VERSION "HNNBNNNYNNNNNNNNNNNNNNNNNNNNNNNNNNNNNNNNNN/4/%%%/4/'%**4NNN///"

NS_ :

BS_:

BU_: AWC BAP_Tester BMC_MLBevo BMS_MV BMS_NV DCDC_800V_PAG DCDC_HV DCDC_HV_02 DCDC_IHEV FCU_MLBevo_FCEV Gateway Gateway_PAG Ladegeraet_2 Ladegeraet_Konzern LE1 LE2 LE2_3_MLBevo_LB LE_MLBevo LE_MLBevo_LB Sub_Gateway TME

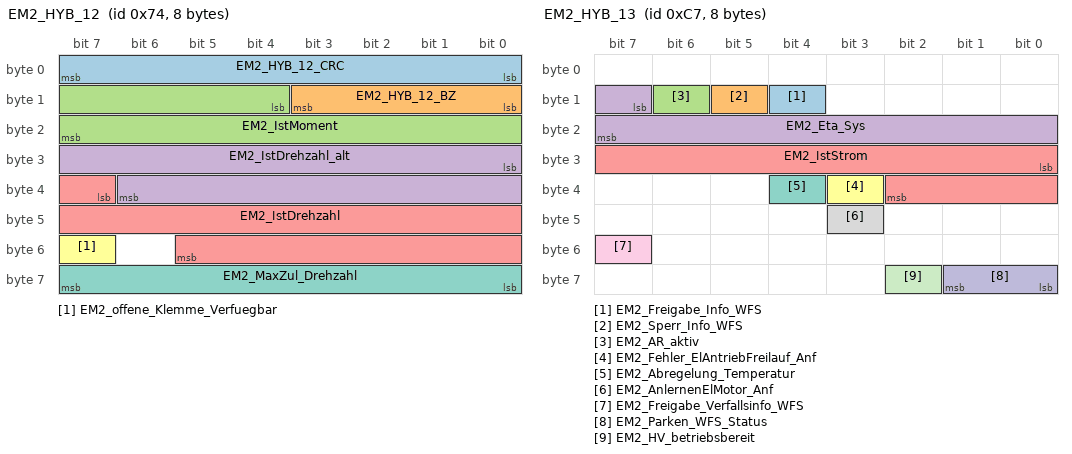
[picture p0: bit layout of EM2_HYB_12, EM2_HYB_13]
BO_ 116 EM2_HYB_12: 8 Gateway
 SG_ EM2_HYB_12_CRC : 0|8@1+ (1,0) [0|255] ""  Sub_Gateway
 SG_ EM2_HYB_12_BZ : 8|4@1+ (1,0) [0|15] ""  Sub_Gateway
 SG_ EM2_IstMoment : 12|12@1+ (0.5,-1023) [-1023|1023.5] "Unit_NewtoMeter"  Sub_Gateway
 SG_ EM2_IstDrehzahl_alt : 24|15@1+ (1,-10000) [-10000|22765] "Unit_MinutInver"  Sub_Gateway
 SG_ EM2_IstDrehzahl : 39|15@1+ (1,-10000) [-10000|22765] "Unit_MinutInver"  Sub_Gateway
 SG_ EM2_offene_Klemme_Verfuegbar : 55|1@1+ (1,0) [0|1] ""  Sub_Gateway
 SG_ EM2_MaxZul_Drehzahl : 56|8@1+ (80,0) [0|20240] "Unit_RevPerMinute"  Sub_Gateway

BO_ 199 EM2_HYB_13: 8 Gateway
 SG_ EM2_Freigabe_Info_WFS : 12|1@1+ (1,0) [0|1] ""  Sub_Gateway
 SG_ EM2_Sperr_Info_WFS : 13|1@1+ (1,0) [0|1] ""  Sub_Gateway
 SG_ EM2_AR_aktiv : 14|1@1+ (1,0) [0|1] ""  Sub_Gateway
 SG_ EM2_Eta_Sys : 15|9@1+ (0.2,0) [0|101.8] "Unit_PerCent"  Sub_Gateway
 SG_ EM2_IstStrom : 24|11@1+ (1,-1023) [-1023|1022] "Unit_Amper"  Sub_Gateway
 SG_ EM2_Fehler_ElAntriebFreilauf_Anf : 35|1@1+ (1,0) [0|1] ""  Sub_Gateway
 SG_ EM2_Abregelung_Temperatur : 36|1@1+ (1,0) [0|1] ""  Sub_Gateway
 SG_ EM2_AnlernenElMotor_Anf : 43|1@1+ (1,0) [0|1] ""  Sub_Gateway
 SG_ EM2_Freigabe_Verfallsinfo_WFS : 55|1@1+ (1,0) [0|1] ""  Sub_Gateway
 SG_ EM2_Parken_WFS_Status : 56|2@1+ (1,0) [0|3] ""  Sub_Gateway
 SG_ EM2_HV_betriebsbereit : 58|1@1+ (1,0) [0|1] ""  Sub_Gateway

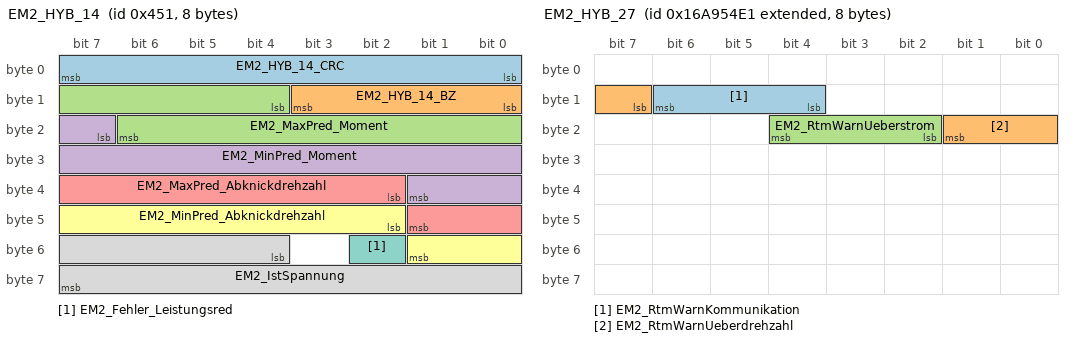
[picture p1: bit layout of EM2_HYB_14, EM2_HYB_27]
BO_ 1105 EM2_HYB_14: 8 Gateway
 SG_ EM2_HYB_14_CRC : 0|8@1+ (1,0) [0|255] ""  Sub_Gateway
 SG_ EM2_HYB_14_BZ : 8|4@1+ (1,0) [0|15] ""  Sub_Gateway
 SG_ EM2_MaxPred_Moment : 12|11@1+ (1,-1023) [-1023|1022] "Unit_NewtoMeter"  Sub_Gateway
 SG_ EM2_MinPred_Moment : 23|11@1+ (1,-1023) [-1023|1022] "Unit_NewtoMeter"  Sub_Gateway
 SG_ EM2_MaxPred_Abknickdrehzahl : 34|8@1+ (50,0) [0|12700] "Unit_MinutInver"  Sub_Gateway
 SG_ EM2_MinPred_Abknickdrehzahl : 42|8@1+ (50,0) [0|12700] "Unit_MinutInver"  Sub_Gateway
 SG_ EM2_Fehler_Leistungsred : 50|1@1+ (1,0) [0|1] ""  Sub_Gateway
 SG_ EM2_IstSpannung : 52|12@1+ (0.25,0) [0|1023.25] "Unit_Volt"  Sub_Gateway

BO_ 2527679713 EM2_HYB_27: 8 Gateway
 SG_ EM2_RtmWarnKommunikation : 12|3@1+ (1,0) [0|7] ""  Sub_Gateway
 SG_ EM2_RtmWarnUeberdrehzahl : 15|3@1+ (1,0) [0|7] ""  Sub_Gateway
 SG_ EM2_RtmWarnUeberstrom : 18|3@1+ (1,0) [0|7] ""  Sub_Gateway

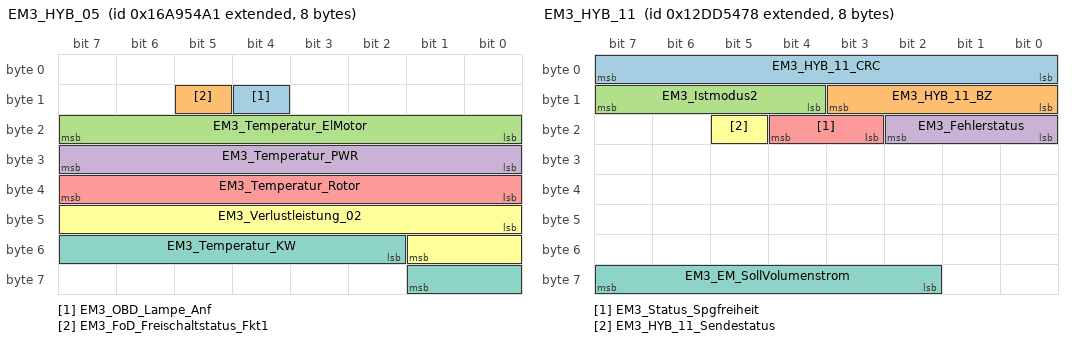
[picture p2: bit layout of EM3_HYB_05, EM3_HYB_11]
BO_ 2527679649 EM3_HYB_05: 8 Gateway
 SG_ EM3_OBD_Lampe_Anf : 12|1@1+ (1,0) [0|1] ""  Sub_Gateway
 SG_ EM3_FoD_Freischaltstatus_Fkt1 : 13|1@1+ (1,0) [0|1] ""  Sub_Gateway
 SG_ EM3_Temperatur_ElMotor : 16|8@1+ (1,-40) [-40|213] "Unit_DegreCelsi"  Sub_Gateway,TME
 SG_ EM3_Temperatur_PWR : 24|8@1+ (1,-40) [-40|213] "Unit_DegreCelsi"  Sub_Gateway,TME
 SG_ EM3_Temperatur_Rotor : 32|8@1+ (1,-40) [-40|213] "Unit_DegreCelsi"  Sub_Gateway,TME
 SG_ EM3_Verlustleistung_02 : 40|10@1+ (80,0) [0|81680] "Unit_Watt"  Sub_Gateway,TME
 SG_ EM3_Temperatur_KW : 50|8@1+ (0.75,-48) [-48|141.75] "Unit_DegreCelsi"  Sub_Gateway

BO_ 2463978616 EM3_HYB_11: 8 Gateway
 SG_ EM3_HYB_11_CRC : 0|8@1+ (1,0) [0|255] ""  Sub_Gateway
 SG_ EM3_HYB_11_BZ : 8|4@1+ (1,0) [0|15] ""  Sub_Gateway
 SG_ EM3_Istmodus2 : 12|4@1+ (1,0) [0|15] ""  Sub_Gateway,TME
 SG_ EM3_Fehlerstatus : 16|3@1+ (1,0) [0|7] ""  Sub_Gateway
 SG_ EM3_Status_Spgfreiheit : 19|2@1+ (1,0) [0|3] ""  Sub_Gateway
 SG_ EM3_HYB_11_Sendestatus : 21|1@1+ (1,0) [0|1] ""  Sub_Gateway
 SG_ EM3_EM_SollVolumenstrom : 58|6@1+ (0.5,0) [0|30.5] "Unit_LiterPerMinut"  Sub_Gateway,TME

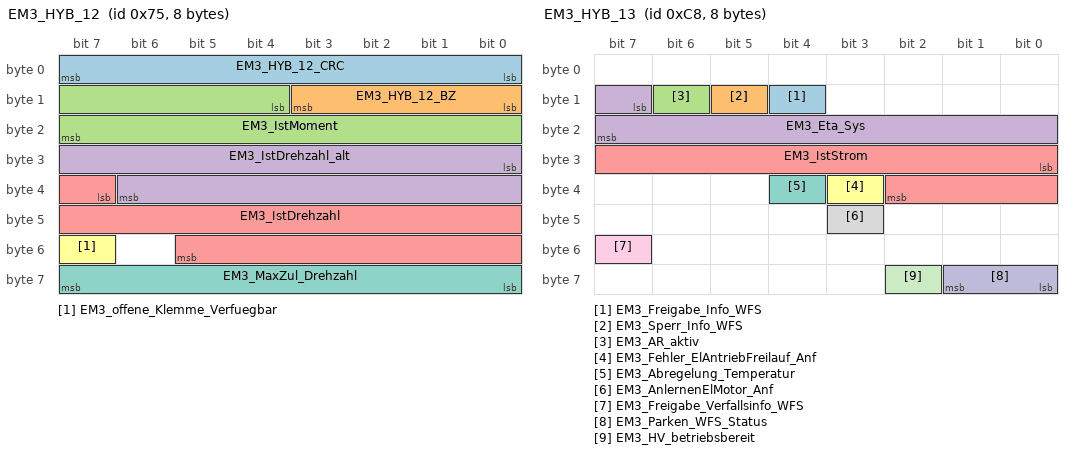
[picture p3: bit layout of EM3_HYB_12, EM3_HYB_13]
BO_ 117 EM3_HYB_12: 8 Gateway
 SG_ EM3_HYB_12_CRC : 0|8@1+ (1,0) [0|255] ""  Sub_Gateway
 SG_ EM3_HYB_12_BZ : 8|4@1+ (1,0) [0|15] ""  Sub_Gateway
 SG_ EM3_IstMoment : 12|12@1+ (0.5,-1023) [-1023|1023.5] "Unit_NewtoMeter"  Sub_Gateway
 SG_ EM3_IstDrehzahl_alt : 24|15@1+ (1,-10000) [-10000|22765] "Unit_MinutInver"  Sub_Gateway
 SG_ EM3_IstDrehzahl : 39|15@1+ (1,-10000) [-10000|22765] "Unit_MinutInver"  Sub_Gateway
 SG_ EM3_offene_Klemme_Verfuegbar : 55|1@1+ (1,0) [0|1] ""  Sub_Gateway
 SG_ EM3_MaxZul_Drehzahl : 56|8@1+ (80,0) [0|20240] "Unit_RevPerMinute"  Sub_Gateway

BO_ 200 EM3_HYB_13: 8 Gateway
 SG_ EM3_Freigabe_Info_WFS : 12|1@1+ (1,0) [0|1] ""  Sub_Gateway
 SG_ EM3_Sperr_Info_WFS : 13|1@1+ (1,0) [0|1] ""  Sub_Gateway
 SG_ EM3_AR_aktiv : 14|1@1+ (1,0) [0|1] ""  Sub_Gateway
 SG_ EM3_Eta_Sys : 15|9@1+ (0.2,0) [0|101.8] "Unit_PerCent"  Sub_Gateway
 SG_ EM3_IstStrom : 24|11@1+ (1,-1023) [-1023|1022] "Unit_Amper"  Sub_Gateway
 SG_ EM3_Fehler_ElAntriebFreilauf_Anf : 35|1@1+ (1,0) [0|1] ""  Sub_Gateway
 SG_ EM3_Abregelung_Temperatur : 36|1@1+ (1,0) [0|1] ""  Sub_Gateway
 SG_ EM3_AnlernenElMotor_Anf : 43|1@1+ (1,0) [0|1] ""  Sub_Gateway
 SG_ EM3_Freigabe_Verfallsinfo_WFS : 55|1@1+ (1,0) [0|1] ""  Sub_Gateway
 SG_ EM3_Parken_WFS_Status : 56|2@1+ (1,0) [0|3] ""  Sub_Gateway
 SG_ EM3_HV_betriebsbereit : 58|1@1+ (1,0) [0|1] ""  Sub_Gateway

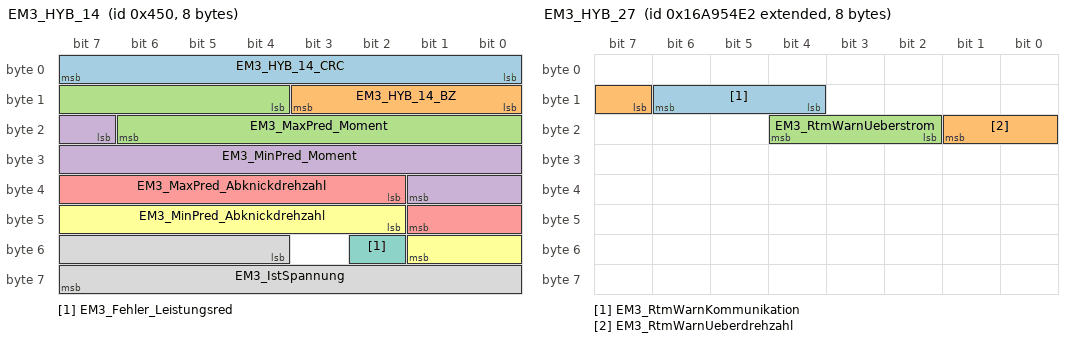
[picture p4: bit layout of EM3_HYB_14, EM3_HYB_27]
BO_ 1104 EM3_HYB_14: 8 Gateway
 SG_ EM3_HYB_14_CRC : 0|8@1+ (1,0) [0|255] ""  Sub_Gateway
 SG_ EM3_HYB_14_BZ : 8|4@1+ (1,0) [0|15] ""  Sub_Gateway
 SG_ EM3_MaxPred_Moment : 12|11@1+ (1,-1023) [-1023|1022] "Unit_NewtoMeter"  Sub_Gateway
 SG_ EM3_MinPred_Moment : 23|11@1+ (1,-1023) [-1023|1022] "Unit_NewtoMeter"  Sub_Gateway
 SG_ EM3_MaxPred_Abknickdrehzahl : 34|8@1+ (50,0) [0|12700] "Unit_MinutInver"  Sub_Gateway
 SG_ EM3_MinPred_Abknickdrehzahl : 42|8@1+ (50,0) [0|12700] "Unit_MinutInver"  Sub_Gateway
 SG_ EM3_Fehler_Leistungsred : 50|1@1+ (1,0) [0|1] ""  Sub_Gateway
 SG_ EM3_IstSpannung : 52|12@1+ (0.25,0) [0|1023.25] "Unit_Volt"  Sub_Gateway

BO_ 2527679714 EM3_HYB_27: 8 Gateway
 SG_ EM3_RtmWarnKommunikation : 12|3@1+ (1,0) [0|7] ""  Sub_Gateway
 SG_ EM3_RtmWarnUeberdrehzahl : 15|3@1+ (1,0) [0|7] ""  Sub_Gateway
 SG_ EM3_RtmWarnUeberstrom : 18|3@1+ (1,0) [0|7] ""  Sub_Gateway

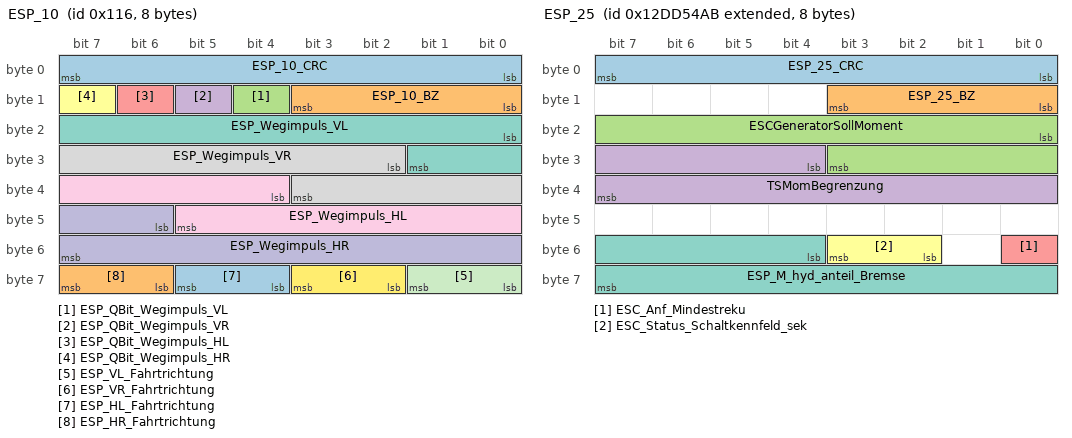
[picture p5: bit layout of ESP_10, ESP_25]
BO_ 278 ESP_10: 8 Gateway
 SG_ ESP_10_CRC : 0|8@1+ (1,0) [0|255] "" Vector__XXX
 SG_ ESP_10_BZ : 8|4@1+ (1,0) [0|15] "" Vector__XXX
 SG_ ESP_QBit_Wegimpuls_VL : 12|1@1+ (1,0) [0|1] ""  AWC
 SG_ ESP_QBit_Wegimpuls_VR : 13|1@1+ (1,0) [0|1] ""  AWC
 SG_ ESP_QBit_Wegimpuls_HL : 14|1@1+ (1,0) [0|1] ""  AWC
 SG_ ESP_QBit_Wegimpuls_HR : 15|1@1+ (1,0) [0|1] ""  AWC
 SG_ ESP_Wegimpuls_VL : 16|10@1+ (1,0) [0|1000] ""  AWC
 SG_ ESP_Wegimpuls_VR : 26|10@1+ (1,0) [0|1000] ""  AWC
 SG_ ESP_Wegimpuls_HL : 36|10@1+ (1,0) [0|1000] ""  AWC
 SG_ ESP_Wegimpuls_HR : 46|10@1+ (1,0) [0|1000] ""  AWC
 SG_ ESP_VL_Fahrtrichtung : 56|2@1+ (1,0) [0|3] ""  AWC
 SG_ ESP_VR_Fahrtrichtung : 58|2@1+ (1,0) [0|3] ""  AWC
 SG_ ESP_HL_Fahrtrichtung : 60|2@1+ (1,0) [0|3] ""  AWC
 SG_ ESP_HR_Fahrtrichtung : 62|2@1+ (1,0) [0|3] ""  AWC

BO_ 418 ESP_15: 8 Gateway
 SG_ ESP_15_CRC : 0|8@1+ (1,0) [0|255] "" Vector__XXX
 SG_ ESP_15_BZ : 8|4@1+ (1,0) [0|15] "" Vector__XXX
 SG_ HMS_P_beibehalten_GE : 12|2@1+ (1,0) [0|3] "" Vector__XXX
 SG_ HMS_Konsistenz_GE : 14|1@1+ (1,0) [0|1] "" Vector__XXX
 SG_ HMS_Konsistenz_IPA : 15|1@1+ (1,0) [0|1] "" Vector__XXX
 SG_ HMS_Konsistenz_STA : 18|1@1+ (1,0) [0|1] "" Vector__XXX
 SG_ HMS_Konsistenz_MO : 19|1@1+ (1,0) [0|1] "" Vector__XXX
 SG_ HMS_halten_nicht_verfuegbar : 20|1@1+ (1,0) [0|1] "" Vector__XXX
 SG_ NL_PRIM_STP_01_Status : 21|3@1+ (1,0) [0|7] "" Vector__XXX
 SG_ VMM_Warnblinken : 24|1@1+ (1,0) [0|1] "" Vector__XXX
 SG_ VZM_Status : 26|3@1+ (1,0) [0|7] "" Vector__XXX
 SG_ HMS_Notstopp_Status : 29|3@1+ (1,0) [0|7] "" Vector__XXX
 SG_ HMS_parken_nicht_verfuegbar : 32|1@1+ (1,0) [0|1] "" Vector__XXX
 SG_ HMS_Anforderung_GE : 33|3@1+ (1,0) [0|7] "" Vector__XXX
 SG_ HMS_Systemstatus : 36|4@1+ (1,0) [0|15] ""  FCU_MLBevo_FCEV,Ladegeraet_Konzern
 SG_ HMS_Stillstand : 40|3@1+ (1,0) [0|7] "" Vector__XXX
 SG_ HMS_aktives_System : 43|5@1+ (1,0) [0|31] ""  Ladegeraet_Konzern
 SG_ HMS_Konsistenz_HVLM : 48|1@1+ (1,0) [0|1] ""  Ladegeraet_Konzern
 SG_ HMS_Konsistenz_ACC : 49|1@1+ (1,0) [0|1] "" Vector__XXX
 SG_ HMS_Fehlerstatus : 50|3@1+ (1,0) [0|7] ""  FCU_MLBevo_FCEV,Ladegeraet_Konzern
 SG_ ESP_Index_Haltemoment : 53|1@1+ (1,0) [0|1] "" Vector__XXX
 SG_ ESP_Haltemoment : 54|10@1+ (10,0) [0|10210] "Unit_NewtoMeter" Vector__XXX

BO_ 1629 ESP_20: 8 Gateway
 SG_ ESP_20_CRC : 0|8@1+ (1,0) [0|255] "" Vector__XXX
 SG_ ESP_20_BZ : 8|4@1+ (1,0) [0|15] "" Vector__XXX
 SG_ BR_Systemart : 12|2@1+ (1,0) [0|3] "" Vector__XXX
 SG_ ESP_SpannungsAnf_02 : 14|2@1+ (1,0) [0|3] "" Vector__XXX
 SG_ ESP_Zaehnezahl : 16|8@1+ (1,0) [0|255] "" Vector__XXX
 SG_ ESP_Charisma_FahrPr : 24|4@1+ (1,0) [0|15] "" Vector__XXX
 SG_ ESP_Charisma_Status : 28|2@1+ (1,0) [0|3] "" Vector__XXX
 SG_ ESP_Wiederstart_Anz_01 : 30|1@1+ (1,0) [0|1] "" Vector__XXX
 SG_ ESP_Wiederstart_Anz_02 : 31|1@1+ (1,0) [0|1] "" Vector__XXX
 SG_ ESP_Wiederstart_Anz_03 : 32|1@1+ (1,0) [0|1] "" Vector__XXX
 SG_ ESP_Wiederstart_Anz_04 : 33|1@1+ (1,0) [0|1] "" Vector__XXX
 SG_ ESP_Stoppverbot_Anz_01 : 34|1@1+ (1,0) [0|1] "" Vector__XXX
 SG_ ESP_Stoppverbot_Anz_02 : 35|1@1+ (1,0) [0|1] "" Vector__XXX
 SG_ ESP_Stoppverbot_Anz_03 : 36|1@1+ (1,0) [0|1] "" Vector__XXX
 SG_ ESP_Stoppverbot_Anz_04 : 37|1@1+ (1,0) [0|1] "" Vector__XXX
 SG_ ESP_Stoppverbot_Anz_05 : 38|1@1+ (1,0) [0|1] "" Vector__XXX
 SG_ ESP_Stoppverbot_Anz_06 : 39|1@1+ (1,0) [0|1] "" Vector__XXX
 SG_ ESP_Stoppverbot_Anz_07 : 40|1@1+ (1,0) [0|1] "" Vector__XXX
 SG_ ESP_Stoppverbot_Anz_Std : 41|1@1+ (1,0) [0|1] "" Vector__XXX
 SG_ ESP_Dachrelingsensor : 42|2@1+ (1,0) [0|3] "" Vector__XXX
 SG_ ESP_Stoppverbot_Anz_08 : 44|1@1+ (1,0) [0|1] "" Vector__XXX
 SG_ HDC_Charisma_FahrPr : 45|4@1+ (1,0) [0|15] "" Vector__XXX
 SG_ HDC_Charisma_Status : 49|2@1+ (1,0) [0|3] "" Vector__XXX
 SG_ BR_QBit_Reifenumfang : 51|1@1+ (1,0) [0|1] ""  AWC
 SG_ BR_Reifenumfang : 52|12@1+ (1,0) [0|4095] "Unit_MilliMeter"  AWC

BO_ 795 ESP_24: 8 Gateway
 SG_ ESP_24_CRC : 0|8@1+ (1,0) [0|255] ""  Sub_Gateway
 SG_ ESP_24_BZ : 8|4@1+ (1,0) [0|15] ""  Sub_Gateway
 SG_ ESP_Lampe : 12|1@1+ (1,0) [0|1] ""  Sub_Gateway
 SG_ ABS_Lampe : 13|1@1+ (1,0) [0|1] ""  Sub_Gateway
 SG_ BK_Lampe_02 : 14|2@1+ (1,0) [0|3] ""  Sub_Gateway
 SG_ TC_Lampe : 16|1@1+ (1,0) [0|1] ""  Sub_Gateway
 SG_ ESP_m_Raddrehz : 17|15@1+ (0.002,0) [0|65.278] "Unit_Hertz"  Sub_Gateway
 SG_ ESP_Textanzeigen_03 : 32|5@1+ (1,0) [0|31] ""  Sub_Gateway
 SG_ ESP_Meldungen : 37|3@1+ (1,0) [0|7] ""  Sub_Gateway
 SG_ ESP_Wegimp_VA : 40|11@1+ (1,0) [0|2047] ""  Sub_Gateway
 SG_ ESP_Fehlerstatus_Wegimp : 51|1@1+ (1,0) [0|1] ""  Sub_Gateway
 SG_ ESP_Wegimp_Ueberlauf : 52|1@1+ (1,0) [0|1] ""  Sub_Gateway
 SG_ ESP_QBit_Wegimp_VA : 53|1@1+ (1,0) [0|1] ""  Sub_Gateway
 SG_ ESP_HDC_Geschw_Farbe : 54|1@1+ (1,0) [0|1] ""  Sub_Gateway
 SG_ ESP_Off_Lampe : 55|1@1+ (1,0) [0|1] ""  Sub_Gateway
 SG_ ESP_HDC_Regelgeschw : 56|7@1+ (0.32,0) [0.32|39.68] "Unit_KiloMeterPerHour"  Sub_Gateway
 SG_ ESP_BKV_Warnung : 63|1@1+ (1,0) [0|1] ""  Sub_Gateway

BO_ 2463978667 ESP_25: 8 Gateway
 SG_ ESP_25_CRC : 0|8@1+ (1,0) [0|255] "" Vector__XXX
 SG_ ESP_25_BZ : 8|4@1+ (1,0) [0|15] "" Vector__XXX
 SG_ ESCGeneratorSollMoment : 16|12@1+ (3,-12279) [-12279|0] "" Vector__XXX
 SG_ TSMomBegrenzung : 28|12@1+ (3,-12279) [-12279|0] "" Vector__XXX
 SG_ ESC_Anf_Mindestreku : 48|1@1+ (1,0) [0|1] ""  TME
 SG_ ESC_Status_Schaltkennfeld_sek : 50|2@1+ (1,0) [0|3] "" Vector__XXX
 SG_ ESP_M_hyd_anteil_Bremse : 52|12@1+ (4,0) [0|16372] "Unit_NewtoMeter" Vector__XXX

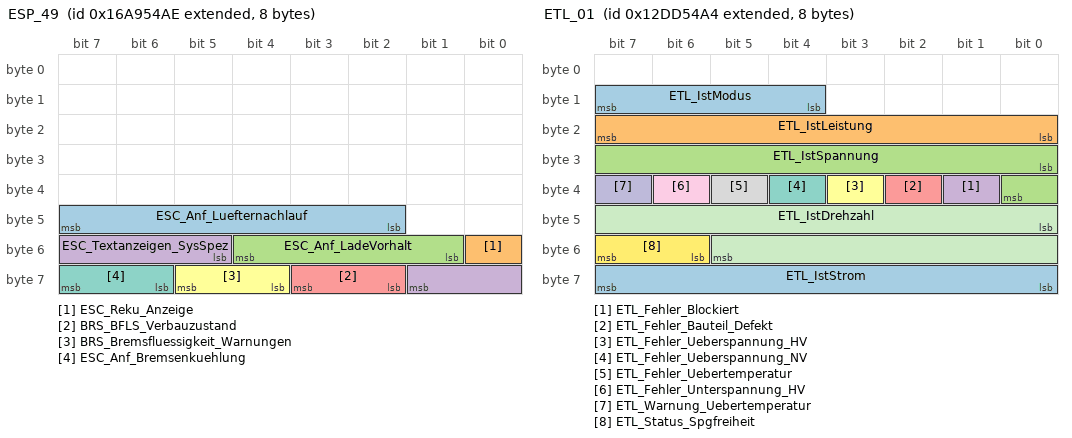
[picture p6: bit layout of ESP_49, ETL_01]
BO_ 2527679662 ESP_49: 8 Gateway
 SG_ ESC_Anf_Luefternachlauf : 42|6@1+ (15,0) [0|945] "Unit_Secon"  TME
 SG_ ESC_Reku_Anzeige : 48|1@1+ (1,0) [0|1] "" Vector__XXX
 SG_ ESC_Anf_LadeVorhalt : 49|4@1+ (1,0) [0|15] ""  Ladegeraet_Konzern
 SG_ ESC_Textanzeigen_SysSpez : 53|5@1+ (1,0) [0|31] "" Vector__XXX
 SG_ BRS_BFLS_Verbauzustand : 58|2@1+ (1,0) [0|3] "" Vector__XXX
 SG_ BRS_Bremsfluessigkeit_Warnungen : 60|2@1+ (1,0) [0|3] "" Vector__XXX
 SG_ ESC_Anf_Bremsenkuehlung : 62|2@1+ (1,0) [0|3] ""  TME

BO_ 2463978660 ETL_01: 8 FCU_MLBevo_FCEV
 SG_ ETL_IstModus : 12|4@1+ (1,0) [0|15] "" Vector__XXX
 SG_ ETL_IstLeistung : 16|8@1+ (200,-25400) [-25400|25400] "Unit_Watt" Vector__XXX
 SG_ ETL_IstSpannung : 24|9@1+ (2,0) [0|1020] "Unit_Volt"  Gateway
 SG_ ETL_Fehler_Blockiert : 33|1@1+ (1,0) [0|1] "" Vector__XXX
 SG_ ETL_Fehler_Bauteil_Defekt : 34|1@1+ (1,0) [0|1] "" Vector__XXX
 SG_ ETL_Fehler_Ueberspannung_HV : 35|1@1+ (1,0) [0|1] "" Vector__XXX
 SG_ ETL_Fehler_Ueberspannung_NV : 36|1@1+ (1,0) [0|1] "" Vector__XXX
 SG_ ETL_Fehler_Uebertemperatur : 37|1@1+ (1,0) [0|1] "" Vector__XXX
 SG_ ETL_Fehler_Unterspannung_HV : 38|1@1+ (1,0) [0|1] "" Vector__XXX
 SG_ ETL_Warnung_Uebertemperatur : 39|1@1+ (1,0) [0|1] "" Vector__XXX
 SG_ ETL_IstDrehzahl : 40|14@1+ (10,0) [0|163820] "Unit_RevPerMinute" Vector__XXX
 SG_ ETL_Status_Spgfreiheit : 54|2@1+ (1,0) [0|3] ""  Gateway
 SG_ ETL_IstStrom : 56|8@1+ (0.5,-63.5) [-63.5|63.5] "Unit_Amper" Vector__XXX

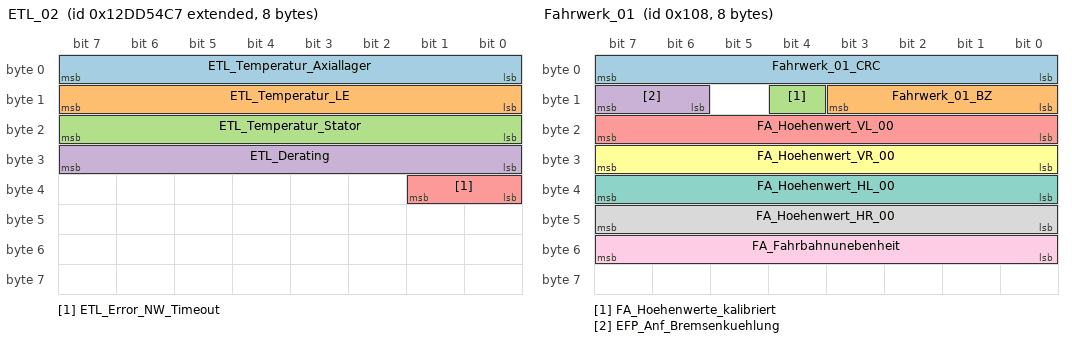
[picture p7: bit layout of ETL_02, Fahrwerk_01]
BO_ 2463978695 ETL_02: 8 FCU_MLBevo_FCEV
 SG_ ETL_Temperatur_Axiallager : 0|8@1+ (1,-40) [-40|213] "Unit_DegreCelsi"  TME
 SG_ ETL_Temperatur_LE : 8|8@1+ (1,-40) [-40|213] "Unit_DegreCelsi"  TME
 SG_ ETL_Temperatur_Stator : 16|8@1+ (1,-40) [-40|213] "Unit_DegreCelsi"  TME
 SG_ ETL_Derating : 24|8@1+ (0.5,0) [0|127] "Unit_PerCent" Vector__XXX
 SG_ ETL_Error_NW_Timeout : 32|2@1+ (1,0) [0|3] "" Vector__XXX

BO_ 264 Fahrwerk_01: 8 Gateway
 SG_ Fahrwerk_01_CRC : 0|8@1+ (1,0) [0|255] "" Vector__XXX
 SG_ Fahrwerk_01_BZ : 8|4@1+ (1,0) [0|15] "" Vector__XXX
 SG_ FA_Hoehenwerte_kalibriert : 12|1@1+ (1,0) [0|1] ""  AWC
 SG_ EFP_Anf_Bremsenkuehlung : 14|2@1+ (1,0) [0|3] ""  TME
 SG_ FA_Hoehenwert_VL_00 : 16|8@1+ (1,-127) [-127|126] "Unit_MilliMeter"  AWC
 SG_ FA_Hoehenwert_VR_00 : 24|8@1+ (1,-127) [-127|126] "Unit_MilliMeter"  AWC
 SG_ FA_Hoehenwert_HL_00 : 32|8@1+ (1,-127) [-127|126] "Unit_MilliMeter"  AWC
 SG_ FA_Hoehenwert_HR_00 : 40|8@1+ (1,-127) [-127|126] "Unit_MilliMeter"  AWC
 SG_ FA_Fahrbahnunebenheit : 48|8@1+ (1,0) [0|253] "" Vector__XXX

BO_ 222 FCU_01: 8 FCU_MLBevo_FCEV
 SG_ FCU_IstLeistung : 50|14@1+ (0.1,-200) [-200|1438.1] "Unit_KiloWatt"  Gateway

BO_ 379 FCU_02: 8 FCU_MLBevo_FCEV
 SG_ FCU_Warn_H2_Konzentrat_Motorraum : 12|3@1+ (1,0) [0|7] ""  Gateway,TME
 SG_ FCU_nicht_verfuegbar : 15|1@1+ (1,0) [0|1] ""  Gateway
 SG_ FCU_Startstopp_Anforderung : 16|4@1+ (1,0) [0|15] ""  Gateway
 SG_ FCU_HV_Anf : 20|2@1+ (1,0) [0|3] ""  Gateway
 SG_ FCU_Klima_Eingr : 22|2@1+ (1,0) [0|3] ""  Gateway,TME
 SG_ FCU_IstModus : 24|5@1+ (1,0) [0|31] ""  Gateway
 SG_ FCU_Status_Spgfreiheit : 29|2@1+ (1,0) [0|3] ""  Gateway
 SG_ FCU_Fehler_Leistungsreduzierung : 31|1@1+ (1,0) [0|1] ""  Gateway
 SG_ FCU_Fehler_Abschaltanforderung : 32|1@1+ (1,0) [0|1] ""  Gateway
 SG_ FCU_Fehler_Notabschaltung : 33|1@1+ (1,0) [0|1] ""  Gateway
 SG_ FCU_Fehler_Entladung_defekt : 34|2@1+ (1,0) [0|3] ""  Gateway
 SG_ FCU_Fehler_Isofehler_I : 36|2@1+ (1,0) [0|3] ""  Gateway
 SG_ FCU_Fehler_Isofehler_II : 38|2@1+ (1,0) [0|3] ""  Gateway
 SG_ FCU_OBD_Lampe_Anf : 40|1@1+ (1,0) [0|1] ""  Gateway
 SG_ FCU_Absperrventil_schliessen : 41|2@1+ (1,0) [0|3] ""  Gateway,TME
 SG_ FCU_TK_Betankung_Anforderung : 43|1@1+ (1,0) [0|1] ""  Gateway,Ladegeraet_Konzern
 SG_ FCU_MinAbs_Leistung : 44|10@1+ (0.1,-50) [-50|52.2] "Unit_KiloWatt"  Gateway
 SG_ FCU_Ionenspuelung_aktiv : 54|2@1+ (1,0) [0|3] ""  Gateway,TME
 SG_ FCU_TK_Freigabe_Tankklappe : 56|2@1+ (1,0) [0|3] ""  Gateway,Ladegeraet_Konzern

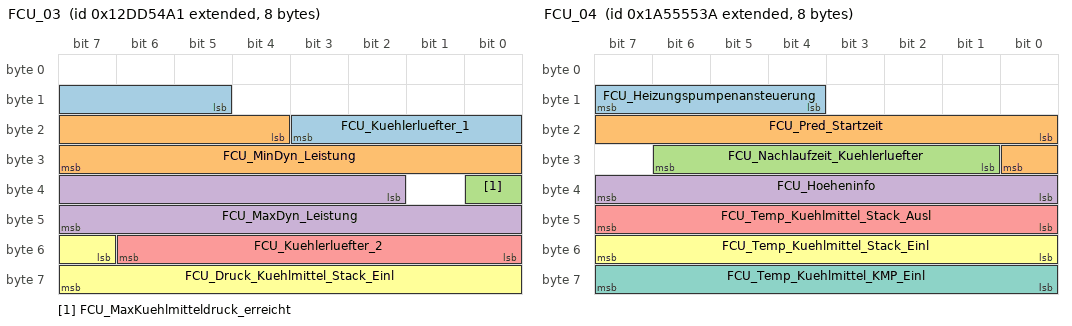
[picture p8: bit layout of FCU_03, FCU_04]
BO_ 2463978657 FCU_03: 8 FCU_MLBevo_FCEV
 SG_ FCU_Kuehlerluefter_1 : 13|7@1+ (1,0) [0|125] "Unit_PerCent"  Gateway,TME
 SG_ FCU_MinDyn_Leistung : 20|12@1+ (0.1,-200) [-200|209.4] "Unit_KiloWatt"  Gateway
 SG_ FCU_MaxKuehlmitteldruck_erreicht : 32|1@1+ (1,0) [0|1] ""  Gateway,TME
 SG_ FCU_MaxDyn_Leistung : 34|14@1+ (0.1,-200) [-200|1438.3] "Unit_KiloWatt"  Gateway
 SG_ FCU_Kuehlerluefter_2 : 48|7@1+ (1,0) [0|125] "Unit_PerCent"  Gateway,TME
 SG_ FCU_Druck_Kuehlmittel_Stack_Einl : 55|9@1+ (15,0) [0|7635] "Unit_MilliBar"  Gateway,TME

BO_ 2589283642 FCU_04: 8 FCU_MLBevo_FCEV
 SG_ FCU_Heizungspumpenansteuerung : 12|4@1+ (10,0) [0|100] "Unit_PerCent"  Gateway,TME
 SG_ FCU_Pred_Startzeit : 16|9@1+ (0.25,0) [0|127.25] "Unit_Secon"  Gateway
 SG_ FCU_Nachlaufzeit_Kuehlerluefter : 25|6@1+ (15,0) [0|945] "Unit_Secon"  Gateway,TME
 SG_ FCU_Hoeheninfo : 32|8@1+ (0.0078125,0) [0|1.984375] "Unit_None"  Gateway,TME
 SG_ FCU_Temp_Kuehlmittel_Stack_Ausl : 40|8@1+ (0.75,-48) [-48|141.75] "Unit_DegreCelsi"  Gateway,TME
 SG_ FCU_Temp_Kuehlmittel_Stack_Einl : 48|8@1+ (0.75,-48) [-48|141.75] "Unit_DegreCelsi"  Gateway,TME
 SG_ FCU_Temp_Kuehlmittel_KMP_Einl : 56|8@1+ (0.75,-48) [-48|141.75] "Unit_DegreCelsi"  Gateway,TME

BO_ 2589283646 FCU_05: 8 FCU_MLBevo_FCEV
 SG_ FCU_Istposition_Thermostatventil : 56|8@1+ (0.395257,0) [0|100.000021] "Unit_PerCent"  TME

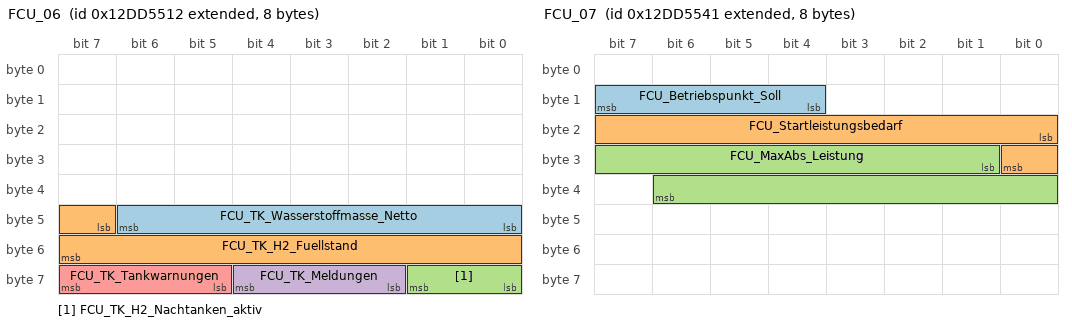
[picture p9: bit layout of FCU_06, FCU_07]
BO_ 2463978770 FCU_06: 8 FCU_MLBevo_FCEV
 SG_ FCU_TK_Wasserstoffmasse_Netto : 40|7@1+ (0.1,0) [0|12.7] "Unit_KiloGram"  Gateway
 SG_ FCU_TK_H2_Fuellstand : 47|9@1+ (0.25,0) [0|127.25] "Unit_PerCent"  Gateway
 SG_ FCU_TK_H2_Nachtanken_aktiv : 56|2@1+ (1,0) [0|3] ""  Gateway
 SG_ FCU_TK_Meldungen : 58|3@1+ (1,0) [0|7] ""  Gateway
 SG_ FCU_TK_Tankwarnungen : 61|3@1+ (1,0) [0|7] ""  Gateway

BO_ 2463978817 FCU_07: 8 FCU_MLBevo_FCEV
 SG_ FCU_Betriebspunkt_Soll : 12|4@1+ (1,0) [0|15] ""  Gateway
 SG_ FCU_Startleistungsbedarf : 16|9@1+ (0.1,0) [0|51] "Unit_KiloWatt"  Gateway
 SG_ FCU_MaxAbs_Leistung : 25|14@1+ (0.1,-200) [-200|1438.2] "Unit_KiloWatt"  Gateway

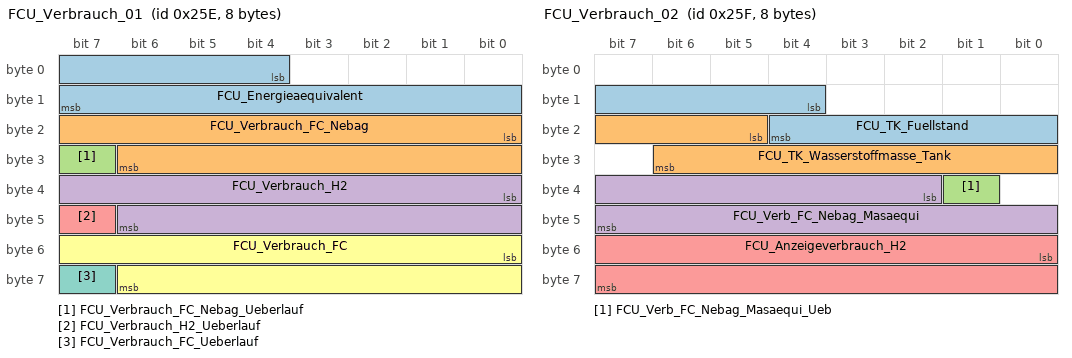
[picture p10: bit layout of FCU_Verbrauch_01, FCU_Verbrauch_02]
BO_ 606 FCU_Verbrauch_01: 8 FCU_MLBevo_FCEV
 SG_ FCU_Energieaequivalent : 4|12@1+ (30,0) [0|122820] "Unit_WattSeconPerGram"  Gateway
 SG_ FCU_Verbrauch_FC_Nebag : 16|15@1+ (1,0) [0|32767] "Unit_WattSecond"  Gateway
 SG_ FCU_Verbrauch_FC_Nebag_Ueberlauf : 31|1@1+ (1,0) [0|1] ""  Gateway
 SG_ FCU_Verbrauch_H2 : 32|15@1+ (0.1,0) [0|3276.7] "Unit_MilliGram"  Gateway
 SG_ FCU_Verbrauch_H2_Ueberlauf : 47|1@1+ (1,0) [0|1] ""  Gateway
 SG_ FCU_Verbrauch_FC : 48|15@1+ (1,0) [0|32767] "Unit_WattSecond"  Gateway
 SG_ FCU_Verbrauch_FC_Ueberlauf : 63|1@1+ (1,0) [0|1] ""  Gateway

BO_ 607 FCU_Verbrauch_02: 8 FCU_MLBevo_FCEV
 SG_ FCU_TK_Fuellstand : 12|9@1+ (0.25,0) [0|127.25] "Unit_PerCent"  Gateway
 SG_ FCU_TK_Wasserstoffmasse_Tank : 21|10@1+ (0.01,0) [0|10.21] "Unit_KiloGram"  Gateway
 SG_ FCU_Verb_FC_Nebag_Masaequi_Ueb : 33|1@1+ (1,0) [0|1] ""  Gateway
 SG_ FCU_Verb_FC_Nebag_Masaequi : 34|14@1+ (0.1,0) [0|1638.3] "Unit_MilliGram"  Gateway
 SG_ FCU_Anzeigeverbrauch_H2 : 48|16@1+ (0.0005,0) [0|32.7675] "Unit_KiloGramPerHour"  Gateway

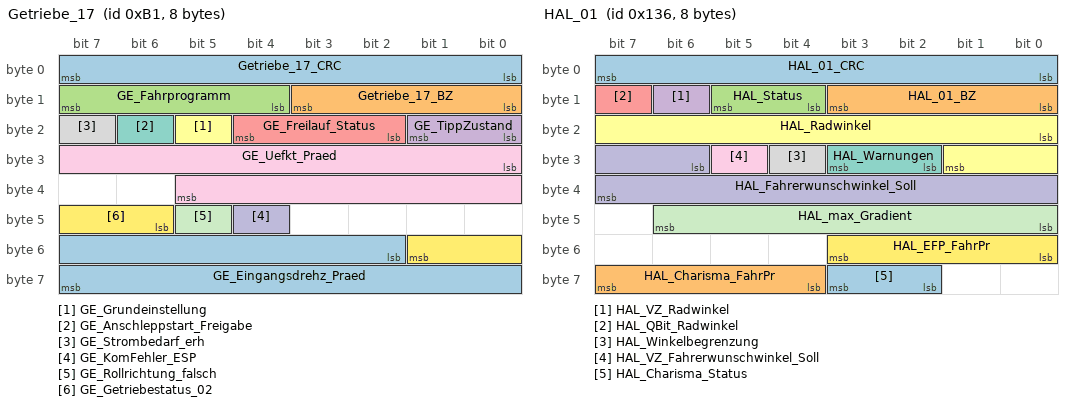
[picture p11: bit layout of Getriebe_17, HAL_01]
BO_ 177 Getriebe_17: 8 Gateway
 SG_ Getriebe_17_CRC : 0|8@1+ (1,0) [0|255] "" Vector__XXX
 SG_ Getriebe_17_BZ : 8|4@1+ (1,0) [0|15] "" Vector__XXX
 SG_ GE_Fahrprogramm : 12|4@1+ (1,0) [0|15] "" Vector__XXX
 SG_ GE_TippZustand : 16|2@1+ (1,0) [0|3] "" Vector__XXX
 SG_ GE_Freilauf_Status : 18|3@1+ (1,0) [0|7] "" Vector__XXX
 SG_ GE_Grundeinstellung : 21|1@1+ (1,0) [0|1] "" Vector__XXX
 SG_ GE_Anschleppstart_Freigabe : 22|1@1+ (1,0) [0|1] "" Vector__XXX
 SG_ GE_Strombedarf_erh : 23|1@1+ (1,0) [0|1] "" Vector__XXX
 SG_ GE_Uefkt_Praed : 24|14@1+ (0.008,0) [0|131.056] "" Vector__XXX
 SG_ GE_KomFehler_ESP : 44|1@1+ (1,0) [0|1] "" Vector__XXX
 SG_ GE_Rollrichtung_falsch : 45|1@1+ (1,0) [0|1] "" Vector__XXX
 SG_ GE_Getriebestatus_02 : 46|4@1+ (1,0) [0|15] ""  BMC_MLBevo,TME
 SG_ GE_Eingangsdrehz_Praed : 50|14@1+ (1,0) [0|16381] "Unit_MinutInver" Vector__XXX

BO_ 310 HAL_01: 8 Gateway
 SG_ HAL_01_CRC : 0|8@1+ (1,0) [0|255] "" Vector__XXX
 SG_ HAL_01_BZ : 8|4@1+ (1,0) [0|15] "" Vector__XXX
 SG_ HAL_Status : 12|2@1+ (1,0) [0|3] "" Vector__XXX
 SG_ HAL_VZ_Radwinkel : 14|1@1+ (1,0) [0|1] ""  AWC
 SG_ HAL_QBit_Radwinkel : 15|1@1+ (1,0) [0|1] ""  AWC
 SG_ HAL_Radwinkel : 16|10@1+ (0.01,0) [0|10.19] "Unit_DegreOfArc"  AWC
 SG_ HAL_Warnungen : 26|2@1+ (1,0) [0|3] "" Vector__XXX
 SG_ HAL_Winkelbegrenzung : 28|1@1+ (1,0) [0|1] "" Vector__XXX
 SG_ HAL_VZ_Fahrerwunschwinkel_Soll : 29|1@1+ (1,0) [0|1] "" Vector__XXX
 SG_ HAL_Fahrerwunschwinkel_Soll : 30|10@1+ (0.01,0) [0|10.21] "Unit_DegreOfArc" Vector__XXX
 SG_ HAL_max_Gradient : 40|7@1+ (0.1,0) [0|12.5] "Unit_DegreOfArcPerSecon" Vector__XXX
 SG_ HAL_EFP_FahrPr : 48|4@1+ (1,0) [0|15] "" Vector__XXX
 SG_ HAL_Charisma_Status : 58|2@1+ (1,0) [0|3] "" Vector__XXX
 SG_ HAL_Charisma_FahrPr : 60|4@1+ (1,0) [0|15] "" Vector__XXX

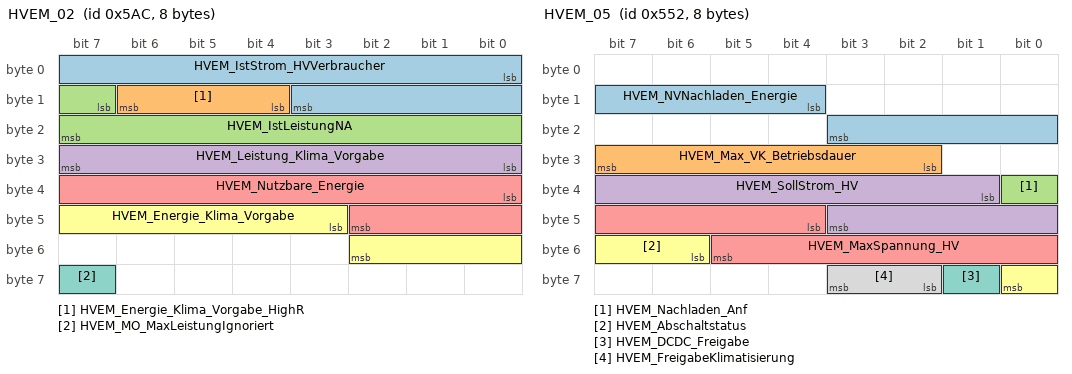
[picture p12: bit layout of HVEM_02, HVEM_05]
BO_ 1452 HVEM_02: 8 Gateway
 SG_ HVEM_IstStrom_HVVerbraucher : 0|12@1+ (0.1,-204.7) [-204.7|204.6] "Unit_Amper" Vector__XXX
 SG_ HVEM_Energie_Klima_Vorgabe_HighR : 12|3@1+ (10,0) [0|50] "Unit_WattHour"  TME
 SG_ HVEM_IstLeistungNA : 15|9@1+ (50,0) [0|25450] "Unit_Watt" Vector__XXX
 SG_ HVEM_Leistung_Klima_Vorgabe : 24|8@1+ (50,0) [0|12650] "Unit_Watt"  TME
 SG_ HVEM_Nutzbare_Energie : 32|11@1+ (50,0) [0|102200] "Unit_WattHour"  Ladegeraet_Konzern
 SG_ HVEM_Energie_Klima_Vorgabe : 43|8@1+ (50,0) [0|12650] "Unit_WattHour"  TME
 SG_ HVEM_MO_MaxLeistungIgnoriert : 63|1@1+ (1,0) [0|1] "" Vector__XXX

BO_ 1362 HVEM_05: 8 Gateway
 SG_ HVEM_NVNachladen_Energie : 12|8@1+ (25,0) [0|6325] "Unit_WattHour"  Ladegeraet_Konzern
 SG_ HVEM_Max_VK_Betriebsdauer : 26|6@1+ (1,0) [0|60] "Unit_Minut"  TME
 SG_ HVEM_Nachladen_Anf : 32|1@1+ (1,0) [0|1] ""  Ladegeraet_Konzern
 SG_ HVEM_SollStrom_HV : 33|11@1+ (0.2,-204.4) [-204.4|204.6] "Unit_Amper"  Ladegeraet_Konzern
 SG_ HVEM_MaxSpannung_HV : 44|10@1+ (1,0) [0|1021] "Unit_Volt" Vector__XXX
 SG_ HVEM_Abschaltstatus : 54|3@1+ (1,0) [0|7] ""  Ladegeraet_Konzern
 SG_ HVEM_DCDC_Freigabe : 57|1@1+ (1,0) [0|1] "" Vector__XXX
 SG_ HVEM_FreigabeKlimatisierung : 58|2@1+ (1,0) [0|3] ""  TME

BO_ 1283 HVK_01: 8 Gateway
 SG_ HVK_01_CRC : 0|8@1+ (1,0) [0|255] ""  BMC_MLBevo,DCDC_800V_PAG,DCDC_HV,DCDC_HV_02,FCU_MLBevo_FCEV,Ladegeraet_2,Ladegeraet_Konzern,LE1,LE2,LE_MLBevo,TME
 SG_ HVK_01_BZ : 8|4@1+ (1,0) [0|15] ""  BMC_MLBevo,DCDC_800V_PAG,DCDC_HV,DCDC_HV_02,FCU_MLBevo_FCEV,Ladegeraet_2,Ladegeraet_Konzern,LE1,LE2,LE_MLBevo,TME
 SG_ HVK_Istmodus_Anf : 12|1@1+ (1,0) [0|1] ""  BMC_MLBevo,DCDC_HV,FCU_MLBevo_FCEV,Ladegeraet_2,Ladegeraet_Konzern,LE1,LE2,LE_MLBevo
 SG_ HVK_TN1_Sollmodus : 13|2@1+ (1,0) [0|3] ""  DCDC_HV_02,FCU_MLBevo_FCEV
 SG_ HVK_MO_EmSollzustand : 16|8@1+ (1,0) [0|255] ""  FCU_MLBevo_FCEV
 SG_ HVK_BMS_Sollmodus : 24|3@1+ (1,0) [0|7] ""  BMC_MLBevo,FCU_MLBevo_FCEV
 SG_ HVK_DCDC_Sollmodus : 27|3@1+ (1,0) [0|7] ""  DCDC_800V_PAG,DCDC_HV,FCU_MLBevo_FCEV,LE_MLBevo
 SG_ HVK_EKK_Sollmodus : 30|3@1+ (1,0) [0|7] ""  FCU_MLBevo_FCEV,TME
 SG_ HVK_HVPTC_Sollmodus : 33|3@1+ (1,0) [0|7] ""  FCU_MLBevo_FCEV,TME
 SG_ HVK_HVLM_Sollmodus : 36|3@1+ (1,0) [0|7] ""  DCDC_HV_02,FCU_MLBevo_FCEV,Ladegeraet_Konzern
 SG_ HVK_HV_Netz_Warnungen : 39|2@1+ (1,0) [0|3] ""  FCU_MLBevo_FCEV
 SG_ HV_Bordnetz_aktiv : 41|1@1+ (1,0) [0|1] ""  DCDC_HV_02,FCU_MLBevo_FCEV,Ladegeraet_Konzern,LE1,LE2,LE_MLBevo
 SG_ HV_Bordnetz_Fehler : 42|1@1+ (1,0) [0|1] ""  FCU_MLBevo_FCEV,Ladegeraet_Konzern,TME
 SG_ HVK_Gesamtst_Spgfreiheit : 43|2@1+ (1,0) [0|3] ""  FCU_MLBevo_FCEV
 SG_ HVK_AktiveEntladung_Anf : 45|1@1+ (1,0) [0|1] ""  DCDC_800V_PAG,DCDC_HV,DCDC_HV_02,FCU_MLBevo_FCEV,LE1,LE2,LE_MLBevo
 SG_ HVK_Iso_Messung_Start : 50|3@1+ (1,0) [0|7] ""  BMC_MLBevo,FCU_MLBevo_FCEV
 SG_ HVK_DCDC_EKK_Sollmodus : 62|2@1+ (1,0) [0|3] ""  DCDC_800V_PAG,FCU_MLBevo_FCEV

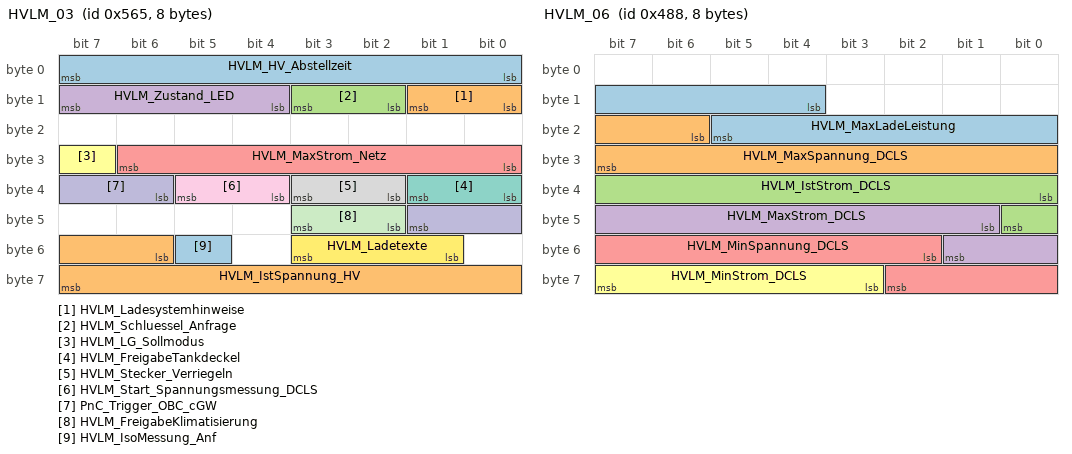
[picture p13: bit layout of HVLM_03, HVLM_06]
BO_ 1381 HVLM_03: 8 Ladegeraet_Konzern
 SG_ HVLM_HV_Abstellzeit : 0|8@1+ (4,0) [0|1012] "Unit_Minut"  Gateway,Gateway_PAG
 SG_ HVLM_Ladesystemhinweise : 8|2@1+ (1,0) [0|3] ""  Gateway,Gateway_PAG
 SG_ HVLM_Schluessel_Anfrage : 10|2@1+ (1,0) [0|3] ""  Gateway,Gateway_PAG
 SG_ HVLM_Zustand_LED : 12|4@1+ (1,0) [0|15] ""  AWC,Gateway,Gateway_PAG
 SG_ HVLM_MaxStrom_Netz : 24|7@1+ (0.5,0) [0|62.5] "Unit_Amper"  Gateway,Gateway_PAG
 SG_ HVLM_LG_Sollmodus : 31|1@1+ (1,0) [0|1] ""  Gateway,Gateway_PAG
 SG_ HVLM_FreigabeTankdeckel : 32|2@1+ (1,0) [0|3] ""  Gateway,Gateway_PAG
 SG_ HVLM_Stecker_Verriegeln : 34|2@1+ (1,0) [0|3] ""  Gateway,Gateway_PAG
 SG_ HVLM_Start_Spannungsmessung_DCLS : 36|2@1+ (1,0) [0|3] ""  BMC_MLBevo,Gateway,Gateway_PAG
 SG_ PnC_Trigger_OBC_cGW : 38|4@1+ (1,0) [0|15] ""  Gateway,Gateway_PAG
 SG_ HVLM_FreigabeKlimatisierung : 42|2@1+ (1,0) [0|3] ""  Gateway,Gateway_PAG,TME
 SG_ HVLM_Ladetexte : 49|3@1+ (1,0) [0|7] ""  Gateway,Gateway_PAG
 SG_ HVLM_IsoMessung_Anf : 53|1@1+ (1,0) [0|1] ""  BMC_MLBevo,DCDC_HV_02,Gateway,Gateway_PAG
 SG_ HVLM_IstSpannung_HV : 54|10@1+ (1,0) [0|1021] "Unit_Volt"  Gateway,Gateway_PAG

BO_ 1340 HVLM_04: 8 Ladegeraet_Konzern
 SG_ HVLM_04_CRC : 0|8@1+ (1,0) [0|255] ""  AWC,BMC_MLBevo,DCDC_HV,Gateway,Gateway_PAG,Sub_Gateway
 SG_ HVLM_04_BZ : 8|4@1+ (1,0) [0|15] ""  AWC,BMC_MLBevo,DCDC_HV,Gateway,Gateway_PAG,Sub_Gateway
 SG_ HVLM_STH_Betriebsmodus : 12|3@1+ (1,0) [0|7] ""  Gateway,Gateway_PAG,Sub_Gateway,TME
 SG_ HVLM_Standklima_Timer_Status : 15|1@1+ (1,0) [0|1] ""  Gateway,Gateway_PAG,Sub_Gateway
 SG_ HVLM_HVEM_MaxLeistung : 16|9@1+ (50,0) [0|25450] "Unit_Watt"  Gateway,Gateway_PAG,Sub_Gateway
 SG_ HVLM_Status_Netz : 25|1@1+ (1,0) [0|1] ""  Gateway,Gateway_PAG,Sub_Gateway,TME
 SG_ HVLM_Anf_Ladescreen : 26|1@1+ (1,0) [0|1] ""  Gateway,Gateway_PAG,Sub_Gateway
 SG_ HVLM_Ladeart : 27|2@1+ (1,0) [0|3] ""  Gateway,Gateway_PAG,Sub_Gateway
 SG_ HVLM_VK_STH_Einsatz : 29|3@1+ (1,0) [0|7] ""  Gateway,Gateway_PAG,Sub_Gateway,TME
 SG_ HVLM_VK_Modus : 32|2@1+ (1,0) [0|3] ""  Gateway,Gateway_PAG,Sub_Gateway,TME
 SG_ HVLM_IstModus_02 : 34|2@1+ (1,0) [0|3] ""  DCDC_800V_PAG,DCDC_HV,Gateway,Gateway_PAG,Sub_Gateway,TME
 SG_ HVLM_HV_Anf : 36|2@1+ (1,0) [0|3] ""  Gateway,Gateway_PAG,Sub_Gateway
 SG_ HVLM_Fehlerstatus : 38|3@1+ (1,0) [0|7] ""  Gateway,Gateway_PAG,Sub_Gateway
 SG_ HVLM_Anforderung_HMS : 41|3@1+ (1,0) [0|7] ""  Gateway,Gateway_PAG,Sub_Gateway
 SG_ HVLM_Parken_beibehalten_HMS : 44|2@1+ (1,0) [0|3] ""  Gateway,Gateway_PAG,Sub_Gateway
 SG_ HVLM_AWC_Sollmodus : 48|3@1+ (1,0) [0|7] ""  AWC,Gateway,Gateway_PAG,Sub_Gateway
 SG_ HVLM_Stecker_Status : 51|2@1+ (1,0) [0|3] ""  BMC_MLBevo,Gateway,Gateway_PAG,Sub_Gateway,TME
 SG_ HVLM_LadeAnforderung : 53|3@1+ (1,0) [0|7] ""  AWC,Gateway,Gateway_PAG,Sub_Gateway,TME
 SG_ HVLM_MaxBatLadestromHV : 56|8@1+ (1,0) [0|253] "Unit_Amper"  Gateway,Gateway_PAG,Sub_Gateway

BO_ 1160 HVLM_06: 8 Ladegeraet_Konzern
 SG_ HVLM_MaxLadeLeistung : 12|10@1+ (250,0) [0|150000] "Unit_Watt"  Gateway,Gateway_PAG,TME
 SG_ HVLM_MaxSpannung_DCLS : 22|10@1+ (1,0) [0|600] "Unit_Volt"  Gateway,Gateway_PAG
 SG_ HVLM_IstStrom_DCLS : 32|9@1+ (1,0) [0|400] "Unit_Amper"  Gateway,Gateway_PAG
 SG_ HVLM_MaxStrom_DCLS : 41|9@1+ (1,0) [0|400] "Unit_Amper"  Gateway,Gateway_PAG
 SG_ HVLM_MinSpannung_DCLS : 50|9@1+ (1,0) [0|400] "Unit_Volt"  Gateway,Gateway_PAG
 SG_ HVLM_MinStrom_DCLS : 59|5@1+ (1,0) [0|29] "Unit_Amper"  Gateway,Gateway_PAG

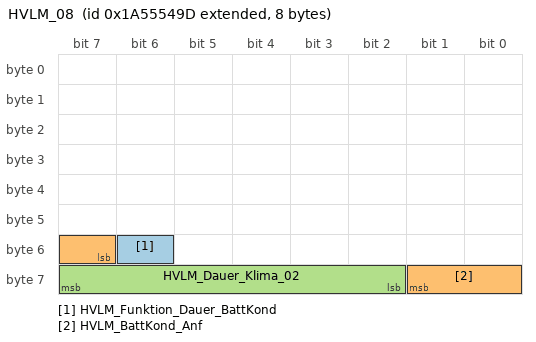
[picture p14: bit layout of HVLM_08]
BO_ 2589283485 HVLM_08: 8 Ladegeraet_Konzern
 SG_ HVLM_Funktion_Dauer_BattKond : 54|1@1+ (1,0) [0|1] ""  BMC_MLBevo,Gateway,Gateway_PAG
 SG_ HVLM_BattKond_Anf : 55|3@1+ (1,0) [0|7] ""  Gateway,Gateway_PAG,TME
 SG_ HVLM_Dauer_Klima_02 : 58|6@1+ (1,0) [0|60] "Unit_Minut"  Gateway,Gateway_PAG,TME

BO_ 2589283605 HVLM_09: 8 Ladegeraet_Konzern
 SG_ HVLM_AWC_Sollstrom : 55|9@1+ (0.1,0) [0|50.9] "Unit_Amper"  AWC

BO_TX_BU_ 116 : Gateway,Gateway_PAG;
BO_TX_BU_ 199 : Gateway,Gateway_PAG;
BO_TX_BU_ 1105 : Gateway,Gateway_PAG;
BO_TX_BU_ 2527679713 : Gateway,Gateway_PAG;
BO_TX_BU_ 2527679649 : Gateway,Gateway_PAG;
BO_TX_BU_ 2463978616 : Gateway,Gateway_PAG;
BO_TX_BU_ 117 : Gateway,Gateway_PAG;
BO_TX_BU_ 200 : Gateway,Gateway_PAG;
BO_TX_BU_ 1104 : Gateway,Gateway_PAG;
BO_TX_BU_ 2527679714 : Gateway,Gateway_PAG;
BO_TX_BU_ 278 : Gateway,Gateway_PAG;
BO_TX_BU_ 418 : Gateway,Gateway_PAG;
BO_TX_BU_ 1629 : Gateway,Gateway_PAG;
BO_TX_BU_ 795 : Gateway,Gateway_PAG;
BO_TX_BU_ 2463978667 : Gateway,Gateway_PAG;
BO_TX_BU_ 2527679662 : Gateway,Gateway_PAG;
BO_TX_BU_ 264 : Gateway,Gateway_PAG;
BO_TX_BU_ 177 : Gateway,Gateway_PAG;
BO_TX_BU_ 310 : Gateway,Gateway_PAG;
BO_TX_BU_ 1452 : Gateway,Gateway_PAG;
BO_TX_BU_ 1362 : Gateway,Gateway_PAG;
BO_TX_BU_ 1283 : Gateway,Gateway_PAG;
CM_ SG_ 116 EM2_HYB_12_CRC "Für MLB:
'Berechnung siehe Lastenheft 'Kommunikationsabsicherung für FlexRay und CAN''

Ab MQB und MLBevo:
'Berechnung siehe Lastenheft 'End-to-End Kommunikationsabsicherung''

Endwerte siehe Begleitdokument 'S-PDU Kennungsfolgen'";
CM_ SG_ 116 EM2_HYB_12_BZ "Botschaft asynchron geroutet. Zählerwert kann springen.";
CM_ SG_ 116 EM2_IstMoment "Momentanwert: E-Maschinen Moment";
CM_ SG_ 116 EM2_IstDrehzahl_alt "Momentanwert: E-Maschinen Drehzahl vor 2,5ms zur Aussetzerdiagnose";
CM_ SG_ 116 EM2_IstDrehzahl "Momentanwert: E-Maschinen Drehzahl";
CM_ SG_ 116 EM2_offene_Klemme_Verfuegbar "Information EM2: Open switches (freewheeling) available / Information EM2: Offene Klemme (Freilauf) verfügbar";
CM_ SG_ 116 EM2_MaxZul_Drehzahl "EM2_MaxZul_Drehzahl stellt die maximale Drehzahlgrenze für LE bzw. EM dar die im Freilauf zulässig ist. Für Drehzahlen größer dieser Grenze wird die LE zum Komponentenschutz unabhängig von der Kommandierung in den AKS umschalten.";
CM_ SG_ 199 EM2_Freigabe_Info_WFS "WFS-Freigabeinformation

";
CM_ SG_ 199 EM2_Sperr_Info_WFS "WFS-Sperrinformation
";
CM_ SG_ 199 EM2_AR_aktiv "Ruckeldämpfer aktiv";
CM_ SG_ 199 EM2_Eta_Sys "Instantaneous efficiency of electrical drive EM2 / Momentaner Wirkungsgrad elektrischer Antrieb EM2";
CM_ SG_ 199 EM2_IstStrom "Momentanwert: Strom über PWR";
CM_ SG_ 199 EM2_Fehler_ElAntriebFreilauf_Anf "Wird gesetzt um den zwingenden Bedarf einer Umschaltung in den Freilauf anzuzeigen. Vergleiche Signal EM1_MaxZul_Drehzahl.";
CM_ SG_ 199 EM2_Abregelung_Temperatur "Leistungsbegrenzung aufgrund Übertemperatur der E-Maschine / des PWR";
CM_ SG_ 199 EM2_AnlernenElMotor_Anf "Diagnoseanforderung von E-Maschine/PWR: Hybrid-Controller schaltet über MO_EM_Sollmodus=6 bzw. MY3_EM_modeReq=6 E-Maschine/PWR aktiv in den Kalibriermodus (Strategie muss sicherstellen, dass kein Moment bei der EM angefordert wird.)";
CM_ SG_ 199 EM2_Freigabe_Verfallsinfo_WFS "WFS";
CM_ SG_ 199 EM2_Parken_WFS_Status "Status der Limitierung";
CM_ SG_ 199 EM2_HV_betriebsbereit "1: Ready_HV / 1: HV-Netz Spannung im Betriebsbereich";
CM_ SG_ 1105 EM2_HYB_14_CRC "Für MLB:
'Berechnung siehe Lastenheft 'Kommunikationsabsicherung für FlexRay und CAN''

Ab MQB und MLBevo:
'Berechnung siehe Lastenheft 'End-to-End Kommunikationsabsicherung''

Endwerte siehe Begleitdokument 'S-PDU Kennungsfolgen'";
CM_ SG_ 1105 EM2_HYB_14_BZ "Botschaft asynchron geroutet. Zählerwert kann springen.";
CM_ SG_ 1105 EM2_MaxPred_Moment "maximal darstellbares Moment für eine im Funktionslastenheft definierte Dauer

Die Berechnung der Momentengrenzen wird projektspezifisch festgelegt
";
CM_ SG_ 1105 EM2_MinPred_Moment "minimal darstellbares Moment für eine im Funktionslastenheft definierte Dauer

Die Berechnung der Momentengrenzen wird projektspezifisch festgelegt
";
CM_ SG_ 1105 EM2_MaxPred_Abknickdrehzahl "rechnerischer Wert: Abknickdrehzahl für maximales motorisches Moment nach Definition Funktionslastenheft";
CM_ SG_ 1105 EM2_MinPred_Abknickdrehzahl "rechnerischer Wert: Abknickdrehzahl für minimales generatorisches Moment nach Definition Funktionslastenheft";
CM_ SG_ 1105 EM2_Fehler_Leistungsred "Eingeschränkte Leistungsfähigkeit auf Grund eins internen Fehlers";
CM_ SG_ 1105 EM2_IstSpannung "Momentanwert: HV-Spannung am PWR";
CM_ SG_ 2527679713 EM2_RtmWarnKommunikation "Real Time Monitoring EM2 bus communication fault";
CM_ SG_ 2527679713 EM2_RtmWarnUeberdrehzahl "RTM Signal overspeed warning EM2";
CM_ SG_ 2527679713 EM2_RtmWarnUeberstrom "RTM Signal over-current warning EM2";
CM_ SG_ 2527679649 EM3_OBD_Lampe_Anf "In allen VW-/Audi-Fahrzeugen ist ein MIL-Master-Konzept umgesetzt. Dazu ermittelt jedes OBD-Steuergerät den eigenen MIL-Status. Eine MIL-Ansteuerung wird vom betroffenen OBD-Steuergerät per MIL-Request über CAN an den MIL-Master weitergegeben. Der MIL-Mas";
CM_ SG_ 2527679649 EM3_FoD_Freischaltstatus_Fkt1 "zeigt den Status der FoD-Freischaltung für das Performanz Paket an";
CM_ SG_ 2527679649 EM3_Temperatur_ElMotor "Momentanwert: Temperatur der E-Maschine";
CM_ SG_ 2527679649 EM3_Temperatur_PWR "Momentanwert: Temperatur des PWR";
CM_ SG_ 2527679649 EM3_Temperatur_Rotor "Momentanwert: Temperatur des Rotors";
CM_ SG_ 2527679649 EM3_Verlustleistung_02 "Instantaneous power loss of electrical drive EM3 / Momentane Verlustleistung elektischer Antrieb EM3";
CM_ SG_ 2527679649 EM3_Temperatur_KW "Aktueller Ist-Wert Kuehlwassertemperatur Leistungselektronik / E-Machine 3";
CM_ SG_ 2463978616 EM3_HYB_11_CRC "Für MLB:
'Berechnung siehe Lastenheft 'Kommunikationsabsicherung für FlexRay und CAN''

Ab MQB und MLBevo:
'Berechnung siehe Lastenheft 'End-to-End Kommunikationsabsicherung''

Endwerte siehe Begleitdokument 'S-PDU Kennungsfolgen'";
CM_ SG_ 2463978616 EM3_HYB_11_BZ "Botschaftszähler";
CM_ SG_ 2463978616 EM3_Istmodus2 "aktuelle Betriebsart der E-Maschine...
0: Standby; Kommunikation aktiv; aktiver Kurzschluss
1: Momentenreglung
2: Drezahlregeung (interner Regelkreis)
3: Spannungsregelung
4: Drehzahlregelung (externer Regelkreis)
5: interner Inverter Fehler; angefo";
CM_ SG_ 2463978616 EM3_Fehlerstatus "aktueller Fehlerstatus der LE3. Anzeige von Fehlern der HV-Sicherheitsfunktionen.";
CM_ SG_ 2463978616 EM3_Status_Spgfreiheit "0 = Init (ohne Funktion)
1 = Leistungselektronik HV-Komponenten spannungsfrei (U_Zwkr < 20V)
2 = Leistungselektronik HV_Komponenten nicht spannungsfrei (U_Zwkr >= 20V)
3 = Fehler (z. B. Fehler in der Sensorik)";
CM_ SG_ 2463978616 EM3_HYB_11_Sendestatus "Gibt den Sendestatus der Botschaft EM3_HYB_11 an (notwendig für IL-Unterstützung)
Dauer hängt von gesetzem HVK_Istmodus_Anf ab.";
CM_ SG_ 2463978616 EM3_EM_SollVolumenstrom "Für die Kühlung der E-Maschine aktuell mindestens benötigter Kühlwasservolumenstrom";
CM_ SG_ 117 EM3_HYB_12_CRC "Für MLB:
'Berechnung siehe Lastenheft 'Kommunikationsabsicherung für FlexRay und CAN''

Ab MQB und MLBevo:
'Berechnung siehe Lastenheft 'End-to-End Kommunikationsabsicherung''

Endwerte siehe Begleitdokument 'S-PDU Kennungsfolgen'";
CM_ SG_ 117 EM3_HYB_12_BZ "Fehlende Beschreibung (Import)
Botschaft asynchron geroutet. Zählerwert kann springen.";
CM_ SG_ 117 EM3_IstMoment "Momentanwert: E-Maschinen Moment";
CM_ SG_ 117 EM3_IstDrehzahl_alt "Momentanwert: E-Maschinen Drehzahl vor 2,5ms zur Aussetzerdiagnose";
CM_ SG_ 117 EM3_IstDrehzahl "Momentanwert: E-Maschinen Drehzahl";
CM_ SG_ 117 EM3_offene_Klemme_Verfuegbar "Information EM3: Open switches (freewheeling) available / Information EM3: Offene Klemme (Freilauf) verfügbar";
CM_ SG_ 117 EM3_MaxZul_Drehzahl "EM2_MaxZul_Drehzahl stellt die maximale Drehzahlgrenze für LE bzw. EM dar die im Freilauf zulässig ist. Für Drehzahlen größer dieser Grenze wird die LE zum Komponentenschutz unabhängig von der Kommandierung in den AKS umschalten.";
CM_ SG_ 200 EM3_Freigabe_Info_WFS "WFS-Freigabeinformation";
CM_ SG_ 200 EM3_Sperr_Info_WFS "WFS-Sperrinformation";
CM_ SG_ 200 EM3_AR_aktiv "Ruckeldämpfer aktiv";
CM_ SG_ 200 EM3_Eta_Sys "Instantaneous efficiency of electrical drive EM3 / Momentaner Wirkungsgrad elektrischer Antrieb EM3";
CM_ SG_ 200 EM3_IstStrom "Momentanwert: Strom über PWR";
CM_ SG_ 200 EM3_Fehler_ElAntriebFreilauf_Anf "Wird gesetzt um den zwingenden Bedarf einer Umschaltung in den Freilauf anzuzeigen. Vergleiche Signal EM3_MaxZul_Drehzahl.";
CM_ SG_ 200 EM3_Abregelung_Temperatur "Leistungsbegrenzung aufgrund Übertemperatur der E-Maschine / des PWR";
CM_ SG_ 200 EM3_AnlernenElMotor_Anf "Diagnoseanforderung von E-Maschine/PWR: Hybrid-Controller schaltet über MO_EM_Sollmodus=6 bzw. MY3_EM_modeReq=6 E-Maschine/PWR aktiv in den Kalibriermodus (Strategie muss sicherstellen, dass kein Moment bei der EM angefordert wird.)";
CM_ SG_ 200 EM3_Freigabe_Verfallsinfo_WFS "WFS Verfallsinfo der Freischaltung";
CM_ SG_ 200 EM3_Parken_WFS_Status "Status der Limitierung";
CM_ SG_ 200 EM3_HV_betriebsbereit "1: Ready_HV / 1: HV-Netz Spannung im Betriebsbereich";
CM_ SG_ 1104 EM3_HYB_14_CRC "Für MLB:
Berechnung siehe Lastenheft 'Kommunikationsabsicherung für FlexRay und CAN'
Ab MQB und MLBevo:
Berechnung siehe Lastenheft 'End-to-End Kommunikationsabsicherung'

Endwerte siehe Begleitdokument 'S-PDU Kennungsfolgen'";
CM_ SG_ 1104 EM3_HYB_14_BZ "4bit Botschaftszähler, wird mit jeder Sendebotschaft inkrementiert
Botschaft asynchron geroutet. Zählerwert kann springen.";
CM_ SG_ 1104 EM3_MaxPred_Moment "maximal darstellbares Moment für eine im Funktionslastenheft definierte Dauer

Die Berechnung der Momentengrenzen wird projektspezifisch festgelegt
";
CM_ SG_ 1104 EM3_MinPred_Moment "minimal darstellbares Moment für eine im Funktionslastenheft definierte Dauer

Die Berechnung der Momentengrenzen wird projektspezifisch festgelegt";
CM_ SG_ 1104 EM3_MaxPred_Abknickdrehzahl "rechnerischer Wert: Abknickdrehzahl für maximales motorisches Moment nach Definition Funktionslastenheft";
CM_ SG_ 1104 EM3_MinPred_Abknickdrehzahl "rechnerischer Wert: Abknickdrehzahl für minimales generatorisches Moment nach Definition Funktionslastenheft";
CM_ SG_ 1104 EM3_Fehler_Leistungsred "Eingeschränkte Leistungsfähigkeit auf Grund eins internen Fehlers";
CM_ SG_ 1104 EM3_IstSpannung "Momentanwert: HV-Spannung am PWR";
CM_ SG_ 2527679714 EM3_RtmWarnKommunikation "Real Time Monitoring EM3 bus communication fault";
CM_ SG_ 2527679714 EM3_RtmWarnUeberdrehzahl "RTM Signal overspeed warning EM3";
CM_ SG_ 2527679714 EM3_RtmWarnUeberstrom "RTM Signal over-current warning EM3";
CM_ SG_ 278 ESP_10_CRC "Für MLB:
'Berechnung siehe Lastenheft 'Kommunikationsabsicherung für FlexRay und CAN''

Ab MQB und MLBevo:
'Berechnung siehe Lastenheft 'End-to-End Kommunikationsabsicherung''

Endwerte siehe Begleitdokument 'S-PDU Kennungsfolgen'

Wird im Projekt";
CM_ SG_ 278 ESP_10_BZ "Botschaftszähler

Wird im Projekt D4 und D4Hybrid nicht verwendet!  Wird im D4 PA verwendet
Botschaft asynchron geroutet. Zählerwert kann springen.";
CM_ SG_ 278 ESP_QBit_Wegimpuls_VL "Qualifizierungsbit Wegimpulszähler VL

Wird im Projekt D4 und D4Hybrid nicht verwendet!  Wird im D4 PA verwendet";
CM_ SG_ 278 ESP_QBit_Wegimpuls_VR "Qualifizierungsbit Wegimpulszähler VR

Wird im Projekt D4 und D4Hybrid nicht verwendet!  Wird im D4 PA verwendet";
CM_ SG_ 278 ESP_QBit_Wegimpuls_HL "Qualifizierungsbit Wegimpulszähler HL

Wird im Projekt D4 und D4Hybrid nicht verwendet!  Wird im D4 PA verwendet";
CM_ SG_ 278 ESP_QBit_Wegimpuls_HR "Qualifizierungsbit Wegimpulszähler HR

Wird im Projekt D4 und D4Hybrid nicht verwendet!  Wird im D4 PA verwendet";
CM_ SG_ 278 ESP_Wegimpuls_VL "Wegimpulszähler VL.
Anzahl der Wegimpulse Vorderrad links (steigende und fallende Flanke)
Zähler läuft grundsätzlich vorwärts, auch bei Rückwärtsfahrt.
Nach SG-Reset ist immer, ohne Ausnahme, 1mal der Init Wert 1021 zu senden.

Wird im Projekt D4 und";
CM_ SG_ 278 ESP_Wegimpuls_VR "Wegimpulszähler VR.
Anzahl der Wegimpulse Vorderrad rechts (steigende und fallende Flanke)
Zähler läuft grundsätzlich vorwärts, auch bei Rückwärtsfahrt.
Nach SG-Reset ist immer, ohne Ausnahme, 1mal der Init Wert 1021 zu senden.

Wird im Projekt D4 un";
CM_ SG_ 278 ESP_Wegimpuls_HL "Wegimpulszähler HL.
Anzahl der Wegimpulse Hinterrad links (steigende und fallende Flanke)
Zähler läuft grundsätzlich vorwärts, auch bei Rückwärtsfahrt.
Nach SG-Reset ist immer, ohne Ausnahme, 1mal der Init Wert 1021 zu senden.

Wird im Projekt D4 und";
CM_ SG_ 278 ESP_Wegimpuls_HR "Wegimpulszähler HR.
Anzahl der Wegimpulse Hinterrad rechts (steigende und fallende Flanke)
Zähler läuft grundsätzlich vorwärts, auch bei Rückwärtsfahrt.
Nach SG-Reset ist immer, ohne Ausnahme, 1mal der Init Wert 1021 zu senden.

Wird im Projekt D4 un";
CM_ SG_ 278 ESP_VL_Fahrtrichtung "Drehrichtung Rad VL

Weiterführende Informationen im Lastenheft spezifiziert und in der entsprechenden Fachabteilung zu erfragen.

Wird im Projekt D4 und D4Hybrid nicht verwendet!  Wird im D4 PA verwendet";
CM_ SG_ 278 ESP_VR_Fahrtrichtung "Drehrichtung Rad VR

Weiterführende Informationen im Lastenheft spezifiziert und in der entsprechenden Fachabteilung zu erfragen.

Wird im Projekt D4 und D4Hybrid nicht verwendet!  Wird im D4 PA verwendet";
CM_ SG_ 278 ESP_HL_Fahrtrichtung "Drehrichtung Rad HL

Weiterführende Informationen im Lastenheft spezifiziert und in der entsprechenden Fachabteilung zu erfragen.

Wird im Projekt D4 und D4Hybrid nicht verwendet!  Wird im D4 PA verwendet";
CM_ SG_ 278 ESP_HR_Fahrtrichtung "Drehrichtung Rad HR

Weiterführende Informationen im Lastenheft spezifiziert und in der entsprechenden Fachabteilung zu erfragen.

Wird im Projekt D4 und D4Hybrid nicht verwendet!  Wird im D4 PA verwendet";
CM_ BO_ 418 "MLBevo verlangsamte 100ms-Botschaft";
CM_ SG_ 418 ESP_15_CRC "Für MLB:
'Berechnung siehe Lastenheft 'Kommunikationsabsicherung für FlexRay und CAN''

Ab MQB und MLBevo:
'Berechnung siehe Lastenheft 'End-to-End Kommunikationsabsicherung''

Endwerte siehe Begleitdokument 'S-PDU Kennungsfolgen'

Wird im Projekt";
CM_ SG_ 418 ESP_15_BZ "Botschaftszähler
Botschaft asynchron geroutet. Zählerwert kann springen.";
CM_ SG_ 418 HMS_P_beibehalten_GE "Fordert das Getriebe auf in Stellung 'P' zu bleiben.";
CM_ SG_ 418 HMS_Konsistenz_GE "Zeigt an, ob die Kommunikation und die Anforderungen plausibel sind.";
CM_ SG_ 418 HMS_Konsistenz_IPA "Zeigt an, ob die Kommunikation und die Anforderungen plausibel sind.
";
CM_ SG_ 418 HMS_Konsistenz_STA "Zeigt an, ob die Kommunikation und die Anforderungen plausibel sind.";
CM_ SG_ 418 HMS_Konsistenz_MO "Zeigt an, ob die Kommunikation und die Anforderungen plausibel sind.";
CM_ SG_ 418 HMS_halten_nicht_verfuegbar "Rueckmeldung HMS-Teilfunktion 'Halten' nicht verfuegbar.";
CM_ SG_ 418 NL_PRIM_STP_01_Status "Das Primär- Bremsregelsystem übermittelt seinen Systemstatus an zFAS und Sekundär- Bremsregelsystem. 

Der Staupilot ermittelt sich über den Status des Primär-und des Sekundärbremsregelsystems den Gesamtzustand des Notlaufreglers.";
CM_ SG_ 418 VMM_Warnblinken "Über dieses Signal wird ein Warnblinken von Funktionen des VMM (VehicleMotionManagers) angefordert.";
CM_ SG_ 418 VZM_Status "Zeigt die Verfuegbarkeit und den Zustand der VZM Funktionen im ESC an";
CM_ SG_ 418 HMS_Notstopp_Status "Statusinformation des Notstoppsystems an die beteiligten Systeme.";
CM_ SG_ 418 HMS_parken_nicht_verfuegbar "Rueckmeldung HMS-Teilfunktionen 'Parken' nicht verfuegbar.";
CM_ SG_ 418 HMS_Anforderung_GE "Fordert vom Getriebe bestimmte Schaltstellungen an.";
CM_ SG_ 418 HMS_Systemstatus "Zeigt den aktuellen Systemstatus des HMS an.";
CM_ SG_ 418 HMS_Stillstand "Das Signal zeigt, basierend auf den vier ESP-Raddrehzahlinformatioen, gefiltert und/oder entprellt mehrstufig den Fahrzeuggeschwindigkeitszustand an.";
CM_ SG_ 418 HMS_aktives_System "Zeigt an, von welchem System die Anforderung gerade umgesetzt wird.";
CM_ SG_ 418 HMS_Konsistenz_HVLM "Zeigt an, ob die Kommunikation und die Anforderungen plausibel sind.";
CM_ SG_ 418 HMS_Konsistenz_ACC "Zeigt an, ob die Kommunikation und die Anforderungen plausibel sind.";
CM_ SG_ 418 HMS_Fehlerstatus "Zeigt den Fehlerstatus des Haltemanagementsystems HMS an.
Details zu den Werten 3/4:
3=Systemeinschränkung, Parken EPB oder GSG nicht möglich
4=Systemstörung bzw. Parken EPB und GSG nicht möglich  ";
CM_ SG_ 418 ESP_Index_Haltemoment "Zeigt an, ob das Summen-Radmoment von ESP_Haltemoment ein Bremsmoment (bergab) oder ein Antriebsmoment (bergauf) darstellt.";
CM_ SG_ 418 ESP_Haltemoment "Zeigt in Abhängigkeit von ESP_Index_Haltemoment das notwendige Summen-Radmoment an (bergab: Bremsmoment; bergauf: Antriebsmoment), das mindestens notwendig ist um das Fahrzeug an der aktuellen Neigung zu halten.";
CM_ BO_ 1629 "neu im MQB";
CM_ SG_ 1629 ESP_20_CRC "Für MLB:
'Berechnung siehe Lastenheft 'Kommunikationsabsicherung für FlexRay und CAN''

Ab MQB und MLBevo:
'Berechnung siehe Lastenheft 'End-to-End Kommunikationsabsicherung''

Endwerte siehe Begleitdokument 'S-PDU Kennungsfolgen'";
CM_ SG_ 1629 ESP_20_BZ "Botschaft asynchron geroutet. Zählerwert kann springen.";
CM_ SG_ 1629 BR_Systemart "Identifikation des verbauten Bremssystems

Dient dem Kombi zur Plausibilisierung";
CM_ SG_ 1629 ESP_SpannungsAnf_02 "Forderung des ESP-SG's zur Spannungsanhebung.";
CM_ SG_ 1629 ESP_Zaehnezahl "Konstanter Wert der Zähnezahl des verwendeten Impulsrades wird ausgegeben, jeder Empfänger der Wegimpulse muss die Zähnezahl einlesen, um eine volle Umdrehung des Rades zu erkennen. 

Weiterführende Informationen im Lastenheft spezifiziert und in der en";
CM_ SG_ 1629 ESP_Charisma_FahrPr "MLBevo: Aktuelles Fahrprogramm des Charisma-Teilnehmers (siehe Systemlastenheft Drive Select)
MQB: Istwert der Kennlinie (siehe Systemlastenheft MQB FPA)";
CM_ SG_ 1629 ESP_Charisma_Status "Systemstatus des Charismateilnehmers

Wert 0x3 ist nur für Fahrzeuge ab MQB relevant";
CM_ SG_ 1629 ESP_Wiederstart_Anz_01 "Dieses Signal gibt die detaillierte Begründung für einen Wiederstart vom Bremsensteuergerät an. ";
CM_ SG_ 1629 ESP_Wiederstart_Anz_02 "Dieses Signal gibt die detaillierte Begründung für einen Wiederstart vom Bremsensteuergerät an. ";
CM_ SG_ 1629 ESP_Wiederstart_Anz_03 "Dieses Signal gibt die detaillierte Begründung für einen Wiederstart vom Bremsensteuergerät an. ";
CM_ SG_ 1629 ESP_Wiederstart_Anz_04 "Dieses Signal gibt die detaillierte Begründung für einen Wiederstart vom Bremsensteuergerät an.";
CM_ SG_ 1629 ESP_Stoppverbot_Anz_01 "Dieses Signal gibt die detaillierte Begründung für ein Stoppverbot vom Bremsensteuergerät an.";
CM_ SG_ 1629 ESP_Stoppverbot_Anz_02 "Dieses Signal gibt die detaillierte Begründung für ein Stoppverbot vom Bremsensteuergerät an.";
CM_ SG_ 1629 ESP_Stoppverbot_Anz_03 "Dieses Signal gibt die detaillierte Begründung für ein Stoppverbot vom Bremsensteuergerät an.";
CM_ SG_ 1629 ESP_Stoppverbot_Anz_04 "Dieses Signal gibt die detaillierte Begründung für ein Stoppverbot vom Bremsensteuergerät an.";
CM_ SG_ 1629 ESP_Stoppverbot_Anz_05 "Dieses Signal gibt die detaillierte Begründung für ein Stoppverbot vom Bremsensteuergerät an.";
CM_ SG_ 1629 ESP_Stoppverbot_Anz_06 "Dieses Signal gibt die detaillierte Begründung für ein Stoppverbot vom Bremsensteuergerät an.";
CM_ SG_ 1629 ESP_Stoppverbot_Anz_07 "Dieses Signal gibt die detaillierte Begründung für ein Stoppverbot vom Bremsensteuergerät an.";
CM_ SG_ 1629 ESP_Stoppverbot_Anz_Std "Dieses Signal gibt die detaillierte Begründung für ein Stoppverbot vom Bremsensteuergerät an.";
CM_ SG_ 1629 ESP_Dachrelingsensor "Erkennung auf Verbau des Dachrelingsensors und Dachquerträger.";
CM_ SG_ 1629 ESP_Stoppverbot_Anz_08 "Dieses Signal gibt die detaillierte Begründung für ein Stoppverbot vom Bremsensteuergerät an.";
CM_ SG_ 1629 HDC_Charisma_FahrPr "MLBevo: Aktuelles Fahrprogramm des Charisma-Teilnehmers (siehe Systemlastenheft Drive Select)
MQB: Istwert der Kennlinie (siehe Systemlastenheft MQB FPA)";
CM_ SG_ 1629 HDC_Charisma_Status "Systemstatus des Charismateilnehmers

Wert 0x3 ist nur für Fahrzeuge ab MQB relevant";
CM_ SG_ 1629 BR_QBit_Reifenumfang "Gesetzt bei Ersatzwert, Init oder Fehler.";
CM_ SG_ 1629 BR_Reifenumfang "Mittlerer Radumfang gerechnet in Millimeter.
Von der Bremse plausibilisierter Wert (Kopie von KBI_Reifenumfang wenn dieser plausibel) oder Ersatzwert aus Bremse wenn KBI_Reifenumfang unplausibel. Bitte das QBit beachten!

Im MEB wird das Signal KBI_Rei";
CM_ BO_ 795 "neu für MQB wg. Absicherung
Entstanden aus ESP_04";
CM_ SG_ 795 ESP_24_CRC "Für MLB:
'Berechnung siehe Lastenheft 'Kommunikationsabsicherung für FlexRay und CAN''

Ab MQB und MLBevo:
'Berechnung siehe Lastenheft 'End-to-End Kommunikationsabsicherung''

Endwerte siehe Begleitdokument 'S-PDU Kennungsfolgen'";
CM_ SG_ 795 ESP_24_BZ "Botschaft asynchron geroutet. Zählerwert kann springen.";
CM_ SG_ 795 ESP_Lampe "Zustand der Fahrdynamikregelungslampe (MLB: ASR und/oder ESP, MQB: nur ESP)

Weiterführende Informationen im Lastenheft spezifiziert und in der entsprechenden Fachabteilung zu erfragen.";
CM_ SG_ 795 ABS_Lampe "Sicherheitswarnlampe

Weiterführende Informationen im Lastenheft spezifiziert und in der entsprechenden Fachabteilung zu erfragen.";
CM_ SG_ 795 BK_Lampe_02 "Sicherheitswarnlampe signalisiert EBV-Ausfall

MQB: wird auch bei HBV-Ausfall verwendet.

Weiterführende Informationen im Lastenheft spezifiziert und in der entsprechenden Fachabteilung zu erfragen.";
CM_ SG_ 795 TC_Lampe "M-ABS Lampe (separate Lampe für M-ABS-Systeme Markt Brasilien)

Weiterführende Informationen im Lastenheft spezifiziert und in der entsprechenden Fachabteilung zu erfragen.";
CM_ SG_ 795 ESP_m_Raddrehz "Radumdrehungen pro Sekunde sind Eingangsgröße für die Geschwindigkeitsberechnung im Kombi. Aus dieser Raddrehzahl und dem Radumfang wird die Fahrzeuggeschwindigkeit errechnet.

MLB: Exklusiver Empfänger ist das Kombiinstrument!
MQB: Bei Frontantrieb un";
CM_ SG_ 795 ESP_Textanzeigen_03 "Textanzeigen der Fahrdynamikregelung im Kombiinstrument

Weiterführende Informationen im Lastenheft spezifiziert und in der entsprechenden Fachabteilung zu erfragen.

Der Signalwert 24 wird nur im BY736 verwendet.";
CM_ SG_ 795 ESP_Meldungen "ESP sendet im Hinweis- /Störungsfall an das Kombi Informationen zum Anzeigen

Weiterführende Informationen im Lastenheft spezifiziert und in der entsprechenden Fachabteilung zu erfragen.
Ergänzender Hinweis:
1 = Autohold_Hinweis_1 (Anfahrassistent: nu";
CM_ SG_ 795 ESP_Wegimp_VA "Weiterführende Informationen im Lastenheft spezifiziert und in der entsprechenden Fachabteilung zu erfragen.

MLB: Die Wegimpulse Vorderachse sind die gemittelten Werte (reine mathematische Operation: Addition und Division durch zwei, keine Filterung) d";
CM_ SG_ 795 ESP_Fehlerstatus_Wegimp "Weiterführende Informationen im Lastenheft spezifiziert und in der entsprechenden Fachabteilung zu erfragen.

MLB: Fehler wird gesetzt, wenn beide ESP-Drehzahlfühler an der Vorderachse defekt sind.

MQB: Fehler wird gesetzt, wenn beide Raddrehzahlfühl";
CM_ SG_ 795 ESP_Wegimp_Ueberlauf "Der Wegimpulszähler ist pro Zündungslauf mindestens einmal übergelaufen

Weiterführende Informationen im Lastenheft spezifiziert und in der entsprechenden Fachabteilung zu erfragen.";
CM_ SG_ 795 ESP_QBit_Wegimp_VA "Gesetzt bei Ersatzwert, Init oder Fehler.";
CM_ SG_ 795 ESP_HDC_Geschw_Farbe "Farbdarstellung der angezeigten HDC-Geschwindigkeit";
CM_ SG_ 795 ESP_Off_Lampe "Bit zur Ansteuerung der separaten ESP-off-Lampe im Kombi (Gesetzesforderung USA)

MLB:
Verwendung/Bedienung ab D4";
CM_ SG_ 795 ESP_HDC_Regelgeschw "Verwendung/Bedienung nur im AU57x Allroad:
HDC-Geschwindigkeit
Dient der Anzeige der HDC-Geschwindigkeit und eines Bergabfahrsymbols im Kombi.
HDC-Standby wird gesetzt sobald der Fahrer den HDC-Taster aktiviert hat.
Bei HDC-Off oder während der Initia";
CM_ SG_ 795 ESP_BKV_Warnung "ESP sendet im Hinweis- /Störungsfall an das Kombi Informationen zum Anzeigen (Text + Akustik)

Im MQB wird dieses Signal nicht unterstützt!
";
CM_ SG_ 2463978667 ESP_25_CRC "Für MLB:
'Berechnung siehe Lastenheft 'Kommunikationsabsicherung für FlexRay und CAN''

Ab MQB und MLBevo:
'Berechnung siehe Lastenheft 'End-to-End Kommunikationsabsicherung''

Endwerte siehe Begleitdokument 'S-PDU Kennungsfolgen'";
CM_ SG_ 2463978667 ESP_25_BZ "Botschaftszaehler
Botschaft asynchron geroutet. Zählerwert kann springen.";
CM_ SG_ 2463978667 ESCGeneratorSollMoment "In MLBevo Faktor in TS_Faktor_Radmomente beachten!

Verzögernd wirkender Antriebsstrangsollmomentenanteil aus Bremspedalbetätigung auf Summenradebene.";
CM_ SG_ 2463978667 TSMomBegrenzung "In MLBevo Faktor in TS_Faktor_Radmomente beachten!

Begrenzung des verzögernd wirkenden Antriebsstrangsollmomentenanteil auf Summenradebene";
CM_ SG_ 2463978667 ESC_Anf_Mindestreku "Bei Wert == 1 soll durch den Antrieb eine im Projekt definierte Mindestrekuperationsleistung des E-Antriebs zur Anforderung durch das Bremssystem schnellst möglich frei gegeben werden. Dies dient zur Entlastung der Reibbremse.";
CM_ SG_ 2463978667 ESC_Status_Schaltkennfeld_sek "Das Signal qualifiziert Wunscheingriffe auf die Getriebeschaltstrategie der sekundären Achse! Signal zur Verwendung im B9 PHEV mit e-quattro Antriebsstrang!";
CM_ SG_ 2463978667 ESP_M_hyd_anteil_Bremse "- Sollmoment hydraulisch bei Rekuperation 
- evtl. Sollmoment hydraulisch bei aktiven Druckaufbauten über eBKV
- Summenradmoment";
CM_ SG_ 2527679662 ESC_Anf_Luefternachlauf "Steuert den Nachlauf des Kühlerlüfters zur Bremsenkühlung nach Klemme 15 aus.";
CM_ SG_ 2527679662 ESC_Reku_Anzeige "Mit der Reku Anzeige wird eine durch einen Fehler verursachte nicht verfügbare Rekuperationsfunktion
im Kombi angezeigt";
CM_ SG_ 2527679662 ESC_Anf_LadeVorhalt "Steuert den Ladevorhalt, um Rekuperation bei langer Bergabfahrt sicherzustellen.";
CM_ SG_ 2527679662 ESC_Textanzeigen_SysSpez "Textanzeigen des Bremsregelsystems zur Anzeige von systemspezifischen Textmeldungen";
CM_ SG_ 2527679662 BRS_BFLS_Verbauzustand "Verbauzustand Bremsfluessigkeitsstand-Sensor (BFLS).

0: Init
1: Sensor nicht am BRS verbaut (MLBevo-Standard: BCM1)
2: Sensor am BRS verbaut

ESP & ESP_PAG: Dauerhafte Bedienung Init.";
CM_ SG_ 2527679662 BRS_Bremsfluessigkeit_Warnungen "Ansteuerung Bewarnung Bremsflüssigkeitsmangel.

0: Init
1: Fuellstand i.O.
2: Warnstufe 1 (gelbe Lampe)
3: Warnstufe 2 (rote Lampe)";
CM_ SG_ 2527679662 ESC_Anf_Bremsenkuehlung "Signal steuert das Oeffnen des Bremsenkuehlkanals und ggf. das Aktivieren eines unterstützenden Lüfters.";
CM_ SG_ 2463978660 ETL_IstModus "Istmodus des ETLs, gesendet von ETL";
CM_ SG_ 2463978660 ETL_IstLeistung "DC-Leistungsaufnahme des ETL, gesendet von ETL";
CM_ SG_ 2463978660 ETL_IstSpannung "DC-Spannung des ETL, gesendet von ETL";
CM_ SG_ 2463978660 ETL_Fehler_Blockiert "Läufer des ETLs ist blockiert, gesendet von ETL";
CM_ SG_ 2463978660 ETL_Fehler_Bauteil_Defekt "Fehler bei Bauteildefekt (elekrischer Fehler, o.ä.), gesendet von ETL";
CM_ SG_ 2463978660 ETL_Fehler_Ueberspannung_HV "Ueberspannung im HV-DC-Netz, gesendet von ETL";
CM_ SG_ 2463978660 ETL_Fehler_Ueberspannung_NV "Ueberspannung im NV-Netz, gesendet von ETL";
CM_ SG_ 2463978660 ETL_Fehler_Uebertemperatur "Fehler sobald Temperatur eine kritische Fehlerschwelle ueberschreitet, gesendet von ETL";
CM_ SG_ 2463978660 ETL_Fehler_Unterspannung_HV "Unterspannung im HV-DC-Netz, gesendet von ETL";
CM_ SG_ 2463978660 ETL_Warnung_Uebertemperatur "Warnung sobald Temperaturschwelle überschritten wird, gesendet von ETL";
CM_ SG_ 2463978660 ETL_IstDrehzahl "Ist-Drehzahl, gesendet von ETL";
CM_ SG_ 2463978660 ETL_Status_Spgfreiheit "Status der HV-Spannungsfreiheitserfassungsfunktion in der LE des ETL";
CM_ SG_ 2463978660 ETL_IstStrom "aktuell gezogener DC Strom, gesendet von ETL";
CM_ SG_ 2463978695 ETL_Temperatur_Axiallager "Temperatur am Axiallager, gesendet von ETL";
CM_ SG_ 2463978695 ETL_Temperatur_LE "Temperatur Leistungselektronik, gesendet von ETL";
CM_ SG_ 2463978695 ETL_Temperatur_Stator "Stator-Temperatur, gesendet von ETL";
CM_ SG_ 2463978695 ETL_Derating "Rückmeldung des ETL falls und wie stark er 'derated', gesendet von ETL";
CM_ SG_ 2463978695 ETL_Error_NW_Timeout "Fehler in CAN-Kommunikation, gesendet von ETL";
CM_ BO_ 264 "ab MLBevo mit CRC";
CM_ SG_ 264 Fahrwerk_01_CRC "Für MLB:
'Berechnung siehe Lastenheft 'Kommunikationsabsicherung für FlexRay und CAN''

Ab MQB und MLBevo:
'Berechnung siehe Lastenheft 'End-to-End Kommunikationsabsicherung''

Endwerte siehe Begleitdokument 'S-PDU Kennungsfolgen'";
CM_ SG_ 264 Fahrwerk_01_BZ "Botschaft asynchron geroutet. Zählerwert kann springen.";
CM_ SG_ 264 FA_Hoehenwerte_kalibriert "Legt fest, wie die Höhensensorwerte interpretiert werden müssen. Umschaltung kalibrierte Höhenwerte / Rohsignale in Byte 3-6

Achtung:
Im AUDI B8 Konstante: 0x1. D.h. es werden nur Rohwerte bedient!
Im AUDI D4 Konstante: 0x0. D.h. es werden nur Millim";
CM_ SG_ 264 EFP_Anf_Bremsenkuehlung "Signal steuert das Oeffnen des Bremsenkuehlkanals und ggf. das Aktivieren eines unterstützenden Lüfters.";
CM_ SG_ 264 FA_Hoehenwert_VL_00 "Aktueller Höhenwert (kalibriert) Vorne Links; ungefiltertes Signal
Einheit, Offset und Faktor sind abhänig von 'FA_Hoehenwert_kalibriert'

Achtung:
Wird im AUDI B8 nicht bedient";
CM_ SG_ 264 FA_Hoehenwert_VR_00 "Aktueller Höhenwert (kalibriert) Vorne Rechts; ungefiltertes Signal
Einheit, Offset und Faktor sind abhänig von 'FA_Hoehenwert_kalibriert'

Achtung:
Wird im AUDI B8 nicht bedient";
CM_ SG_ 264 FA_Hoehenwert_HL_00 "Aktueller Höhenwert (kalibriert) Hinten Links; ungefiltertes Signal
Einheit, Offset und Faktor sind abhänig von 'FA_Hoehenwert_kalibriert'

Achtung:
Wird im AUDI B8 nicht bedient";
CM_ SG_ 264 FA_Hoehenwert_HR_00 "Aktueller Höhenwert (kalibriert) Hinten Rechts; ungefiltertes Signal
Einheit, Offset und Faktor sind abhänig von 'FA_Hoehenwert_kalibriert'

Achtung:
Wird im AUDI B8 nicht bedient";
CM_ SG_ 264 FA_Fahrbahnunebenheit "Informationsbeschreibung des Fahrbahnzustandes";
CM_ SG_ 222 FCU_IstLeistung "Aktuelle Ist-Leistung (netto) des Brennstoffzellensystems 

Leistungsabgabe BZ-System - positiv
Leistungsaufnahme BZ-System - negativ";
CM_ SG_ 379 FCU_Warn_H2_Konzentrat_Motorraum "Warnung H2-Konzentration im Motorraum

Ansteuerung Kühlerlüfter für Motorraumspülung & ggf. Deaktivierung Innenraumgebläse. Ggf. müssen Akustikgrenzen aufgehoben werden";
CM_ SG_ 379 FCU_nicht_verfuegbar "FCU-System-Verfuegbarkeitsstatus";
CM_ SG_ 379 FCU_Startstopp_Anforderung "Start/Stop-Anforderungen der FCU, z.B. Stopverbot, -freigabe, -anforderung, -wunsch und Startwunsch";
CM_ SG_ 379 FCU_HV_Anf "Anforderung 'HV-Netz aktivieren'";
CM_ SG_ 379 FCU_Klima_Eingr "beschränkt Kompressorleistung / Kompressorabwurf";
CM_ SG_ 379 FCU_IstModus "IST-Modus des FCU-Systems";
CM_ SG_ 379 FCU_Status_Spgfreiheit "0=Init
1=HV-Komponente spannungsfrei (U_Zwkr < 20V)
2=HV-Komponente nicht spannungsfrei (U_Zwkr >/= 25V, Hysterese)
3=Fehler (z.B. Fehler in der Sensorik)";
CM_ SG_ 379 FCU_Fehler_Leistungsreduzierung "Leistungsreduzierung der FCU aufgrund Fehler aktiv (nur mit Fehlerspeichereintrag), z.B. LimpHome";
CM_ SG_ 379 FCU_Fehler_Abschaltanforderung "FCU-System-Stoppanforderung der FCU aufgrund Fehler in der FCU (nur mit Fehlerspeichereintrag)";
CM_ SG_ 379 FCU_Fehler_Notabschaltung "FCU-System-Notabschaltung  aufgrund Fehler in der FCU (nur mit Fehlerspeichereintrag)";
CM_ SG_ 379 FCU_Fehler_Entladung_defekt "Aktueller Fehlerstatus der Entladung";
CM_ SG_ 379 FCU_Fehler_Isofehler_I "Aktueller Isofehlerstatus des Brennstoffzellensystems";
CM_ SG_ 379 FCU_Fehler_Isofehler_II "Aktueller Isofehlerstatus des Brennstoffzellensystems";
CM_ SG_ 379 FCU_OBD_Lampe_Anf "Anforderung MIL (MalfunctionIndicationLamp) von FCU";
CM_ SG_ 379 FCU_Absperrventil_schliessen "Abtrennung HT-Kreis von Heizkreis";
CM_ SG_ 379 FCU_TK_Betankung_Anforderung "Notwendig für Tankvorgang, um Weiterfahrt zu unterbinden.

Triggert:
- BZ zum Herunterfahren bzw. Sleep-Mode
- EPB aktivieren
- Fahrbereitschaft deaktivieren";
CM_ SG_ 379 FCU_MinAbs_Leistung "Absolute minimale Leistung des BZ-Systems

Leistungsabgabe BZ-System - positiv
Leistungsaufnahme BZ-System - negativ";
CM_ SG_ 379 FCU_Ionenspuelung_aktiv "Spülung aller Kühlkreisläufe der Brennstoffzelle
0= keine Spülung
1= Spülung zwingend notwendig
2= Spülung Anforderung";
CM_ SG_ 379 FCU_TK_Freigabe_Tankklappe "Freigabesignal für Entriegelung Tankklappe.";
CM_ SG_ 2463978657 FCU_Kuehlerluefter_1 "Ansteuertastverhaeltnis (PWM) der Kuehlerluefterendstufe 1";
CM_ SG_ 2463978657 FCU_MinDyn_Leistung "minimale Leistung des BZ-Systems Wert ist für eine Dauer von 1s garantiert

Leistungsabgabe BZ-System - positiv
Leistungsaufnahme BZ-System - negativ";
CM_ SG_ 2463978657 FCU_MaxKuehlmitteldruck_erreicht "maximaler Kuehlmitteldruck erreicht";
CM_ SG_ 2463978657 FCU_MaxDyn_Leistung "maximale Leistung des BZ-Systems Wert ist für eine Dauer von 1s garantiert

Leistungsabgabe BZ-System - positiv
Leistungsaufnahme BZ-System - negativ";
CM_ SG_ 2463978657 FCU_Kuehlerluefter_2 "Ansteuertastverhaeltnis (PWM) der Kuehlerluefterendstufe 2";
CM_ SG_ 2463978657 FCU_Druck_Kuehlmittel_Stack_Einl "Mapping Sensor 3p1";
CM_ SG_ 2589283642 FCU_Heizungspumpenansteuerung "Heizungspumpenansteuerung. Erforderlich für Leitfähigkeit-Spülfunktion";
CM_ SG_ 2589283642 FCU_Pred_Startzeit "Prädizierte Startzeit (-dauer) für den nächsten Start des FCU-System";
CM_ SG_ 2589283642 FCU_Nachlaufzeit_Kuehlerluefter "Nachlaufzeit des Kuehlerluefters am HWK";
CM_ SG_ 2589283642 FCU_Hoeheninfo "Korrekturfaktor Höhe (1 entspricht 1013 mbar)";
CM_ SG_ 2589283642 FCU_Temp_Kuehlmittel_Stack_Ausl "Mapping von Sensor 3T2";
CM_ SG_ 2589283642 FCU_Temp_Kuehlmittel_Stack_Einl "Mapping von Sensor 3T1";
CM_ SG_ 2589283642 FCU_Temp_Kuehlmittel_KMP_Einl "Mapping von Sensor 3T3";
CM_ SG_ 2589283646 FCU_Istposition_Thermostatventil "Istposition 3V1 Thermostatventil";
CM_ SG_ 2463978770 FCU_TK_Wasserstoffmasse_Netto "Wasserstoffmasse Netto ( Behälterschutz und Worst-Case-Reserve berücksichtigt)";
CM_ SG_ 2463978770 FCU_TK_H2_Fuellstand "Wasserstoff-Füllstand für Anzeige im Kombi";
CM_ SG_ 2463978770 FCU_TK_H2_Nachtanken_aktiv "Wird bei einer H2 Betankung gesetzt, und bleibt gesetzt bis v>5km/h für >5s";
CM_ SG_ 2463978770 FCU_TK_Meldungen "Anzeige von Infos und Fehler im  Kombi";
CM_ SG_ 2463978770 FCU_TK_Tankwarnungen "Warnt den Fahrer vor geringem Füllstand (analog: Reserve 1; Reserve 2)";
CM_ SG_ 2463978817 FCU_Betriebspunkt_Soll "Betriebspunkt-Anforderung des Brennstofzellensystems an die Betriebsstrategie";
CM_ SG_ 2463978817 FCU_Startleistungsbedarf "Leistungsaufnahme des BZ-Systems im Startfall";
CM_ SG_ 2463978817 FCU_MaxAbs_Leistung "Absolute maximale Leistung des BZ-Systems

Leistungsabgabe BZ-System - positiv
Leistungsaufnahme BZ-System - negativ";
CM_ SG_ 606 FCU_Energieaequivalent "BZ-System-Wirkungsgrad korrigierter Heizwert";
CM_ SG_ 606 FCU_Verbrauch_FC_Nebag "Überlaufender Zähler von den BZ Nebenaggregaten aufgenommene Arbeit";
CM_ SG_ 606 FCU_Verbrauch_FC_Nebag_Ueberlauf "Erster Überlauf Verbrauchssignal";
CM_ SG_ 606 FCU_Verbrauch_H2 "Überlaufender Zähler/Eingebrachte H2 Masse";
CM_ SG_ 606 FCU_Verbrauch_H2_Ueberlauf "Erster Überlauf Verbrauchssignal";
CM_ SG_ 606 FCU_Verbrauch_FC "Überlaufender Zähler von der BZ abgegebene elektrische Arbeit";
CM_ SG_ 606 FCU_Verbrauch_FC_Ueberlauf "Erster Überlauf Verbrauchssignal";
CM_ SG_ 607 FCU_TK_Fuellstand "Aktueller nutzbarer Tankfüllstand wird in FCU berechnet.";
CM_ SG_ 607 FCU_TK_Wasserstoffmasse_Tank "Nutzbare Gewichtsmasse des sich in den Tanks befindenden Wasserstoffs.";
CM_ SG_ 607 FCU_Verb_FC_Nebag_Masaequi_Ueb "Erster Überlauf Verbrauchssignal";
CM_ SG_ 607 FCU_Verb_FC_Nebag_Masaequi "Überlaufender Zähler/Eingebrachte H2 Masse für Nebenaggregate";
CM_ SG_ 607 FCU_Anzeigeverbrauch_H2 "Momentanverbrauch H2";
CM_ SG_ 177 Getriebe_17_CRC "Für MLB:
'Berechnung siehe Lastenheft 'Kommunikationsabsicherung für FlexRay und CAN''

Ab MQB und MLBevo:
'Berechnung siehe Lastenheft 'End-to-End Kommunikationsabsicherung''

Endwerte siehe Begleitdokument 'S-PDU Kennungsfolgen'";
CM_ SG_ 177 Getriebe_17_BZ "Botschaftszähler
Botschaft asynchron geroutet. Zählerwert kann springen.";
CM_ SG_ 177 GE_Fahrprogramm "Signalisiert das Fahrprogramm  im Bezug auf
die Fahrstufe des Getriebes.

Audi/MQB:
Offroad

Bentley:
Snow
Gravel
Mud_Ruts
Sand_Dune

Touareg:
Offroad
Snow";
CM_ SG_ 177 GE_TippZustand "Zeigt den Tippzustand in eine Fahrstufe und ein Fahrprogramm via Paddles oder Schaltbetätigung an.
Das Signal ist gültig in Kombination mit GE_Fahrstufe und GE_Fahrprogramm.

MLBevo:
DL und AL: nur Tipp_in_permanent
PDK2: Tipp_in_temporaer und Tipp_i";
CM_ SG_ 177 GE_Freilauf_Status "Freilauf-Status-Signal vom Frailauf-Master an aktive Freilauf-Teilnehmer. In diesem Signal zeigt der Freilauf-Master an, welchen aktuellen Status die Freilauf-Betriebsstrategie hat.";
CM_ SG_ 177 GE_Grundeinstellung "Grundeinstellung des Getriebes ist aktiv

Hinweis:
Verwendung nur im MQB";
CM_ SG_ 177 GE_Anschleppstart_Freigabe "Bilden einer Schleppstartfreigabe aus Fahrdynamiksicht. Schleppstartabbruch bei kritischer Fahrzeugstabilität";
CM_ SG_ 177 GE_Strombedarf_erh "Das GSG teilt dem MSG einen aufgrund der Kühlung erhöhten Strombedarf mit, damit gleichzeitig die Kühler-Lüfter-Ansteuerung kurzzeitig reduziert wird.

Signal wird bisher nur im MQB-PHEV verwendet.";
CM_ SG_ 177 GE_Uefkt_Praed "Praedizierte Triebstrangübertragungsfunktion 
(Verständnis Übertragungsfunktion gemäß Ge_Uefkt_02)
Weiterführende Informationen sind bei der entsprechenden Fachabteilung zu erfragen.";
CM_ SG_ 177 GE_KomFehler_ESP "Anzeige Kommunikationsfehler bei Empfang vom ESP.

Einsatz nur in PDK-Projekten.";
CM_ SG_ 177 GE_Rollrichtung_falsch "Rollrichtung des Fahrzeugs ist entgegen der eingelegten Fahrstufe (bezogen auf GE_Fahrstufe);
0 = Rollrichtung richtig bzw. Init (auch im Stillstand bzw. in P/N/Zwischenposition)
1 = Rollrichtung falsch";
CM_ SG_ 177 GE_Getriebestatus_02 "Signalisierung von speziellen Betriebszuständen des Getriebes:
1= Rennstartvorbereitung; genutzt im MSG zum Aufbau einer Momentenreserve, in Allrad und Quersperre (GQS)
2= Rennstart; nicht genutzt im MSG
3= Anfahrt; genutzt im MSG zur Umschaltung des F";
CM_ SG_ 177 GE_Eingangsdrehz_Praed "prädizierte Getriebe-Eingangsdrehzahl (während Schaltungen kann die voraussichtliche Drehzahl am Ende der Schaltung gezeigt werden)";
CM_ SG_ 310 HAL_01_CRC "Für MLB:
'Berechnung siehe Lastenheft 'Kommunikationsabsicherung für FlexRay und CAN''

Ab MQB und MLBevo:
'Berechnung siehe Lastenheft 'End-to-End Kommunikationsabsicherung''

Endwerte siehe Begleitdokument 'S-PDU Kennungsfolgen'
";
CM_ SG_ 310 HAL_01_BZ "Botschaft asynchron geroutet. Zählerwert kann springen.";
CM_ SG_ 310 HAL_Status "Status der Hinterachslenkung
0: normaler Betrieb 
1: HAL verriegelt (z.B. harter Fehler, nicht kalibriert)
2: Rücknahme der Leistung, Funktion eingeschränkt/Derating aktiv 
3: HAL deaktiviert";
CM_ SG_ 310 HAL_VZ_Radwinkel "Lenkrichtung der HAL";
CM_ SG_ 310 HAL_QBit_Radwinkel "Wenn Bit gesetzt, dann entspreicht das Signal nicht mehr ASIL-D. (z.B. Ausfall der redundanten Sensorik)";
CM_ SG_ 310 HAL_Radwinkel "Zusätzlich durch die HAL gestellter Radwinkeloffset an der Hinterachse in Grad";
CM_ SG_ 310 HAL_Warnungen "Warnmeldungsanforderung von der Hinterachslenkung an das Kombiinstrumnent";
CM_ SG_ 310 HAL_Winkelbegrenzung "Signal liefert die Info über eine aktive Winkelbegrenzung in der HAL aufgrund Bauteilschutz";
CM_ SG_ 310 HAL_VZ_Fahrerwunschwinkel_Soll "Soll-Lenkrichtung der HAL";
CM_ SG_ 310 HAL_Fahrerwunschwinkel_Soll "Zielwinkel (=Fahrerwunschwinkel) am Rad Hinterachslenkung in Grad";
CM_ SG_ 310 HAL_max_Gradient "maximaler Zustellgradient für die Stabilisierungsfunktion mit HAL durch ESP";
CM_ SG_ 310 HAL_EFP_FahrPr "Aktueller Ist-Zustand der HAL";
CM_ SG_ 310 HAL_Charisma_Status "Rückmeldung an den Charisma-Master";
CM_ SG_ 310 HAL_Charisma_FahrPr "MLBevo: Aktuelles Fahrprogramm des Charisma-Teilnehmers (siehe Systemlastenheft Drive Select)
MQB: Istwert der Kennlinie (siehe Systemlastenheft MQB FPA)";
CM_ SG_ 1452 HVEM_IstStrom_HVVerbraucher "Iststromaufnahme der elektrischen Nebenaggregate aus dem HV Zwischenkreis";
CM_ SG_ 1452 HVEM_Energie_Klima_Vorgabe_HighR "Erweiterte Auflösung von 10Wh für Signal HVEM_Energie_Klima_Vorgabe.
Signalwert wird zu HVEM_Energie_Klima_Vorgabe Addiert";
CM_ SG_ 1452 HVEM_IstLeistungNA "aktuelle Leistungsaufnahme der Nebenaggregate";
CM_ SG_ 1452 HVEM_Leistung_Klima_Vorgabe "Leistungsvorgabe Thermo (für Kühlen und Heizen)";
CM_ SG_ 1452 HVEM_Nutzbare_Energie "Nutzbare Energie welche für Komfortfunktionen vom HVEM freigegeben wird.";
CM_ SG_ 1452 HVEM_Energie_Klima_Vorgabe "HVEM-Energievorgabe für Klima-Vorkonditionierung";
CM_ SG_ 1452 HVEM_MO_MaxLeistungIgnoriert "Rueckmeldung des HVEM ob die vorgegebene MaxLeistung vom MSG eingehalten wird.";
CM_ SG_ 1362 HVEM_NVNachladen_Energie "HV-Lademanagement benötigt die Energiemenge für das Laden der 12V Batterie, um die Ladezeit zu berechnen";
CM_ SG_ 1362 HVEM_Max_VK_Betriebsdauer "Betriebslaufzeit der Standklimatisierung";
CM_ SG_ 1362 HVEM_Nachladen_Anf "Anforderung für HV Laden bei gestecktem Stecker und deaktivierter Ladeanforderung";
CM_ SG_ 1362 HVEM_SollStrom_HV "Sollstrom Laden auf der HV-Seite";
CM_ SG_ 1362 HVEM_MaxSpannung_HV "maximale Ladespannung an das Ladegerät bzw. DC-Ladestation";
CM_ SG_ 1362 HVEM_Abschaltstatus "Status der Reduzierungsstufen der Klimakomponenten beim Laden

0 = 100% (keine Reduzierung)
1 = 75%
2 = 50%
3 = 25%
7 = Init";
CM_ SG_ 1362 HVEM_DCDC_Freigabe "Freigabe des DCDC wenn das Fzg nicht Fahrbereit ist.";
CM_ SG_ 1362 HVEM_FreigabeKlimatisierung "Klimatisierung freigeben";
CM_ SG_ 1283 HVK_01_CRC "Für MLB:
'Berechnung siehe Lastenheft 'Kommunikationsabsicherung für FlexRay und CAN''

Ab MQB und MLBevo:
'Berechnung siehe Lastenheft 'End-to-End Kommunikationsabsicherung''

Endwerte siehe Begleitdokument 'S-PDU Kennungsfolgen'";
CM_ SG_ 1283 HVK_Istmodus_Anf "HVK-Anforderung an alle HV-Komponenten deren Istmodus im schnellen Zyklus (Inhibitzeit) zu senden.";
CM_ SG_ 1283 HVK_TN1_Sollmodus "Angeforderter Sollmodus der Steuereinheit für das Schütze des Teilnetz1 'Ladepfad':
0 : HV_Off                                
1 : HV_On (Schütz geschlossen)                
2 : reserviert
3 : Init   (CAN-Initialisierung)";
CM_ SG_ 1283 HVK_MO_EmSollzustand "Anforderung vom HVK Sollzustand der Elm_State
0 = HvOff              
1 = HvStbyReq          
2 = HvStbyWait         
3 = HvBattOnReq        
4 = HvBattOnWait       
10 = HvOnIdle          
18 = HvOnDrvReq        
19 = HvOnDrvWait       
20 = HvO";
CM_ SG_ 1283 HVK_BMS_Sollmodus "Angeforderter Sollmodus der HV-Batterie:
0 : HV_Off                                
1 : HV_On (HS geschlossen)                
2 : nicht belegbar                        
3 : AC-Laden_erw (HS +AC_2-Schütze geschlossen)                         
4 : AC-";
CM_ SG_ 1283 HVK_DCDC_Sollmodus "angeforderte Soll-Betriebsart des DC/DC-Wandlers: 
0: Standby; Kommunikation aktiv
1: Zwischenkreis des HV-Netzes wird vorgeladen; HV-Netz wird aktiviert und darf nicht  
    belastet werden.
2: Tiefsetzen (HV --> BN 14,4V)
    Sollwertvorgabe projek";
CM_ SG_ 1283 HVK_EKK_Sollmodus "Sollmodus elektrischer Klimakompressor";
CM_ SG_ 1283 HVK_HVPTC_Sollmodus "Sollmodus HV-PTC
0 : keine Freigabe
1 : Freigabe
2 : Freigabe_ausgesetzt
3 : nicht belegbar
4 : nicht belegbar
5 : nicht belegbar
6 : nicht belegbar
7 : Init   (CAN-Initialisierung)   

Info: 'nicht belegbar' d.h. Sollmodus nicht relevant für HV";
CM_ SG_ 1283 HVK_HVLM_Sollmodus "Angeforderter Sollmodus des Lademanagers.";
CM_ SG_ 1283 HVK_HV_Netz_Warnungen "Anforderung Warnung/Fehler HV-System im Kombi
0: Keine Warnung/Init
1:Anforderung_Anzeige_Warnung_HV-Netz (gelbes Symbol)
2:Anforderung_Anzeige_Fehler_HV-Netz (rotes Symbol)
3:Anforderung_Anzeige_Warnung_Kein_Wiederstart_möglich";
CM_ SG_ 1283 HV_Bordnetz_aktiv "Signalisiert ein aktives Hochvoltbordnetz. Für die Belastbarkeit des HV-Netzes müssen Strom- bzw. Leistungsgrenzen eingehalten werden";
CM_ SG_ 1283 HV_Bordnetz_Fehler "Status ob im  HV-Netz ein Fehler detektiert wurde.";
CM_ SG_ 1283 HVK_Gesamtst_Spgfreiheit "Status des HV-Systems";
CM_ SG_ 1283 HVK_AktiveEntladung_Anf "Anforderung zum aktiven Entladen des HV-Netzes, während der Abschaltung des HV-Netz.";
CM_ SG_ 1283 HVK_Iso_Messung_Start "Anforderung an die isolationswiderstandsüberwachenden HV-Komponenten zur Durchführung der Isolations-Widerstandsmessung.";
CM_ SG_ 1283 HVK_DCDC_EKK_Sollmodus "Bedarfsgerechtes Aktivieren des 400V-DCDC-Wandlers bei Anforderung durch TME";
CM_ SG_ 1381 HVLM_HV_Abstellzeit "Zeitraum zwischen HV-Deaktiviert und HV-Aktiviert";
CM_ SG_ 1381 HVLM_Ladesystemhinweise "Anzeigen von Hinweisen zum Ladesystem.
Anzeigen, dass das Ladesystem defekt ist.";
CM_ SG_ 1381 HVLM_Schluessel_Anfrage "Anforderung HVLM an BCM für Schlüsselsuche über Kessy";
CM_ SG_ 1381 HVLM_Zustand_LED "Zustand der Lade-LED im Kombi und Dosenbeleuchtung";
CM_ SG_ 1381 HVLM_MaxStrom_Netz "maximal zulässiger Strom auf Primärseite (AC) des Ladegerätes
Minima aus
Vorgabe z.B. über
- intelligente Kommunikation
- Control Pilot Duty Cycle
- Widerstandskodierung Kabel (Proximity)
- Vorgabe MMI, o.ä.";
CM_ SG_ 1381 HVLM_LG_Sollmodus "Sollmodus AC Ladegerät";
CM_ SG_ 1381 HVLM_FreigabeTankdeckel "Tankdeckelfreigabe";
CM_ SG_ 1381 HVLM_Stecker_Verriegeln "Anforderung Steckerverriegelung";
CM_ SG_ 1381 HVLM_Start_Spannungsmessung_DCLS "Meldung an das BMS, dass an der DC-Ladesäule eine Messspannung aufgeschaltet wird.";
CM_ SG_ 1381 PnC_Trigger_OBC_cGW "Trigger-Signal für die UDS-Kommunikation zwischen cGW und OBC für die Funktion Plug & Charge Online";
CM_ SG_ 1381 HVLM_FreigabeKlimatisierung "Klimatisierung freigeben";
CM_ SG_ 1381 HVLM_Ladetexte "Anzeige, ob AC- oder DC-Laden nicht möglich ist";
CM_ SG_ 1381 HVLM_IsoMessung_Anf "Signalisierung an den HVK, ob während des Ladens eine Iso-Messung durchgeführt werden muss.
0 = Laden mit Isomessung
1 = Laden ohne Isomessung";
CM_ SG_ 1381 HVLM_IstSpannung_HV "Ausgangsspannung des Ladegerätes und DC-Spannung der Ladesäule. Messung zwischen den DC HV-Leitungen. ";
CM_ BO_ 1340 "CAN-Botschaft";
CM_ SG_ 1340 HVLM_04_CRC "Für MLB:
'Berechnung siehe Lastenheft 'Kommunikationsabsicherung für FlexRay und CAN''

Ab MQB und MLBevo:
'Berechnung siehe Lastenheft 'End-to-End Kommunikationsabsicherung''

Endwerte siehe Begleitdokument 'S-PDU Kennungsfolgen'";
CM_ SG_ 1340 HVLM_04_BZ "Fortlaufender Botschaftszaehler";
CM_ SG_ 1340 HVLM_STH_Betriebsmodus "Betriebsmodus der Standheizung für Vorkonditionierung und Timerklimatisierung";
CM_ SG_ 1340 HVLM_Standklima_Timer_Status "Signalisierung an das KBT ob mind. ein Timer zur Standklimatisierung programmiert ist";
CM_ SG_ 1340 HVLM_HVEM_MaxLeistung "Maximal zulässige Leistung, die das HVEM vom Lader nutzen darf. Wenn das Fzg nicht über einen Lader mit dem AC Netz verbunden ist ist dieser Wert 0.";
CM_ SG_ 1340 HVLM_Status_Netz "Information, ob das Fahrzeug mit einem Stromnetz verbunden ist.";
CM_ SG_ 1340 HVLM_Anf_Ladescreen "Anforderung für Ladescreen (BEV)";
CM_ SG_ 1340 HVLM_Ladeart "Anzeige, ob Strom in das Fzg. fließt und wofür er verwendet wird.";
CM_ SG_ 1340 HVLM_VK_STH_Einsatz "Auswahl der PHEV Standheizung";
CM_ SG_ 1340 HVLM_VK_Modus "Übermittlung des aktuellen Konditionierungs-Status für HMI, Mobile Online Dienste";
CM_ SG_ 1340 HVLM_IstModus_02 "aktueller Modus";
CM_ SG_ 1340 HVLM_HV_Anf "HV-Aktivierung Anforderung und Grund der Anforderung";
CM_ SG_ 1340 HVLM_Fehlerstatus "aktueller Fehlerstatus des Ladegerätes
";
CM_ SG_ 1340 HVLM_Anforderung_HMS "Anforderung zur Verriegelung des Triebstrangs";
CM_ SG_ 1340 HVLM_Parken_beibehalten_HMS "Anforderung den Triebstrang verriegelt zu halten";
CM_ SG_ 1340 HVLM_AWC_Sollmodus "Sollmodus AWC Ladegerät";
CM_ SG_ 1340 HVLM_Stecker_Status "Status der Steckererkennung unabhängig vom Lademodus (AC oder DC)";
CM_ SG_ 1340 HVLM_LadeAnforderung "Mitteilung des Lademanagements an das MSG ob Stecker erkannt wurde, Laden gestartet, ein autonomer Betriebszustand aktiviert, eine Relaxing Phase für die Batterie angefordert werden soll";
CM_ SG_ 1340 HVLM_MaxBatLadestromHV "Empfohlener HV Batterieladestrom bei einer geplanten Ladung";
CM_ SG_ 1160 HVLM_MaxLadeLeistung "maximale DC Ladeleistung";
CM_ SG_ 1160 HVLM_MaxSpannung_DCLS "maximale DC Ladespannung";
CM_ SG_ 1160 HVLM_IstStrom_DCLS "aktueller DC Ladestrom";
CM_ SG_ 1160 HVLM_MaxStrom_DCLS "maximaler DC Ladestrom";
CM_ SG_ 1160 HVLM_MinSpannung_DCLS "minimale DC Ladespannung";
CM_ SG_ 1160 HVLM_MinStrom_DCLS "minimaler DC Ladestrom";
CM_ SG_ 2589283485 HVLM_Funktion_Dauer_BattKond "Funktion Dauerkonditionierung HV-Batterie.";
CM_ SG_ 2589283485 HVLM_BattKond_Anf "Anforderung Batteriekonditionierung";
CM_ SG_ 2589283485 HVLM_Dauer_Klima_02 "Dauer der Innenraumklimatisierung.";
CM_ SG_ 2589283605 HVLM_AWC_Sollstrom "Angeforderter Sollstrom für AWC Laden";
BA_DEF_ BO_  "DiagRequest" ENUM  "No","Yes";
BA_DEF_ BO_  "DiagResponse" ENUM  "No","Yes";
BA_DEF_ BO_  "DiagState" ENUM  "No","Yes";
BA_DEF_ BO_  "GenMsgChkConstant" HEX 0 4095;
BA_DEF_ BO_  "GenMsgCycleTime" INT 0 65535;
BA_DEF_ BO_  "GenMsgCycleTimeFast" INT 0 65535;
BA_DEF_ BO_  "GenMsgDelayTime" INT 0 100000;
BA_DEF_ BO_  "GenMsgILSupport" ENUM  "No","Yes";
BA_DEF_ BO_  "GenMsgNrOfRepetition" INT 0 100;
BA_DEF_ BO_  "GenMsgPDUConstants" STRING ;
BA_DEF_ BO_  "GenMsgSendType" ENUM  "Cyclic","not_used","not_used","not_used","not_used","not_used","not_used","IfActive","NoMsgSendType";
BA_DEF_ BO_  "GenMsgStartDelayTime" INT 0 100000;
BA_DEF_ BO_  "NmMessage" ENUM  "No","Yes";
BA_DEF_ BO_  "NmhMessage" ENUM  "No","Yes";
BA_DEF_ BO_  "MsgType" ENUM  "Application","NM ","NMH","TP2.0","ISO-TP ","BAP","EID","KS","XCP_PRE_CONFIGURED","XCP_RUNTIME_CONFIGURED";
BA_DEF_ BO_  "VAGTP20_API" HEX 0 255;
BA_DEF_ BO_  "VAGTP20_DynConnection" ENUM  "No","Yes";
BA_DEF_ BO_  "VAGTP20_DynSetup" ENUM  "No","Yes";
BA_DEF_ BO_  "VAGTP20_StatConnection" ENUM  "No","Yes";
BA_DEF_ SG_  "GenSigActiveRepetitions" INT -2147483648 2147483647;
BA_DEF_ SG_  "GenSigInactiveValue" INT -2147483648 2147483647;
BA_DEF_ SG_  "GenSigSendType" ENUM  "Cyclic","OnWrite","OnWriteWithRepetition","OnChange","OnChangeWithRepetition","IfActive","IfActiveWithRepetition","NoSigSendType","OnChangeAndIfActive","OnChangeAndIfActiveWithRepetition";
BA_DEF_ SG_  "GenSigStartValue" INT -2147483648 2147483647;
BA_DEF_ SG_  "NWM-WakeupAllowed" ENUM  "No","Yes";
BA_DEF_ SG_  "GenSigFuncType" ENUM  "NoFunction","MsgCounter","CRC-8","XOR","XOR-2","DatedBit","SW-Kl15","CHK","Constant","Protocol","CRC-8-SAE_J1850","CRC-32","DataLength","DataID","MsgCounter16","SOK-Signatur","Cluster";
BA_DEF_ SG_  "GenSigSwitchedByIgnition" ENUM  "No","Yes";
BA_DEF_ SG_  "Fehlerwert" HEX 0 2147483647;
BA_DEF_ SG_  "GenSigMissingSourceValue" HEX 0 2147483647;
BA_DEF_REL_ BU_SG_REL_  "GenSigTimeoutTime" INT 0 65535;
BA_DEF_DEF_REL_ "GenSigTimeoutTime" 0;
BA_DEF_DEF_  "DiagRequest" "No";
BA_DEF_DEF_  "DiagResponse" "No";
BA_DEF_DEF_  "DiagState" "No";
BA_DEF_DEF_  "GenMsgChkConstant" 0;
BA_DEF_DEF_  "GenMsgCycleTime" 0;
BA_DEF_DEF_  "GenMsgCycleTimeFast" 0;
BA_DEF_DEF_  "GenMsgDelayTime" 0;
BA_DEF_DEF_  "GenMsgILSupport" "No";
BA_DEF_DEF_  "GenMsgNrOfRepetition" 0;
BA_DEF_DEF_  "GenMsgPDUConstants" "";
BA_DEF_DEF_  "GenMsgSendType" "NoMsgSendType";
BA_DEF_DEF_  "GenMsgStartDelayTime" 0;
BA_DEF_DEF_  "NmMessage" "No";
BA_DEF_DEF_  "NmhMessage" "No";
BA_DEF_DEF_  "MsgType" "Application";
BA_DEF_DEF_  "VAGTP20_API" 0;
BA_DEF_DEF_  "VAGTP20_DynConnection" "No";
BA_DEF_DEF_  "VAGTP20_DynSetup" "No";
BA_DEF_DEF_  "VAGTP20_StatConnection" "No";
BA_DEF_DEF_  "GenSigActiveRepetitions" 0;
BA_DEF_DEF_  "GenSigInactiveValue" 0;
BA_DEF_DEF_  "GenSigSendType" "NoSigSendType";
BA_DEF_DEF_  "GenSigStartValue" 0;
BA_DEF_DEF_  "NWM-WakeupAllowed" "No";
BA_DEF_DEF_  "GenSigFuncType" "NoFunction";
BA_DEF_DEF_  "GenSigSwitchedByIgnition" "Yes";
BA_DEF_DEF_  "Fehlerwert" 0;
BA_DEF_DEF_  "GenSigMissingSourceValue" 0;
BA_ "GenMsgSendType" BO_ 116 0;
BA_ "GenMsgPDUConstants" BO_ 116 "0xb7,0x6e,0x93,0xf5,0xdc,0x38,0xe2,0x40,0x06,0xfb,0x80,0x1c,0x0e,0xe3,0xd5,0xe5";
BA_ "GenMsgILSupport" BO_ 116 1;
BA_ "GenMsgCycleTime" BO_ 116 1000;
BA_ "GenMsgSendType" BO_ 199 0;
BA_ "GenMsgILSupport" BO_ 199 1;
BA_ "GenMsgCycleTime" BO_ 199 1000;
BA_ "GenMsgSendType" BO_ 1105 0;
BA_ "GenMsgPDUConstants" BO_ 1105 "0x19,0xc1,0x1a,0xf6,0x7d,0x28,0x7b,0x12,0xcb,0x29,0x59,0x98,0xd2,0xbf,0x53,0x9d";
BA_ "GenMsgILSupport" BO_ 1105 1;
BA_ "GenMsgCycleTime" BO_ 1105 1000;
BA_ "GenMsgSendType" BO_ 2527679713 0;
BA_ "GenMsgILSupport" BO_ 2527679713 1;
BA_ "GenMsgCycleTime" BO_ 2527679713 960;
BA_ "GenMsgSendType" BO_ 2527679649 0;
BA_ "GenMsgILSupport" BO_ 2527679649 1;
BA_ "GenMsgCycleTime" BO_ 2527679649 320;
BA_ "GenMsgSendType" BO_ 2463978616 0;
BA_ "GenMsgPDUConstants" BO_ 2463978616 "0xe0,0x2f,0x8d,0x3c,0x70,0x22,0x03,0x60,0x0e,0x18,0xd9,0xeb,0x95,0x63,0xcb,0x76";
BA_ "GenMsgNrOfRepetition" BO_ 2463978616 5;
BA_ "GenMsgILSupport" BO_ 2463978616 1;
BA_ "GenMsgDelayTime" BO_ 2463978616 40;
BA_ "GenMsgCycleTimeFast" BO_ 2463978616 40;
BA_ "GenMsgCycleTime" BO_ 2463978616 480;
BA_ "GenMsgSendType" BO_ 117 0;
BA_ "GenMsgPDUConstants" BO_ 117 "0x63,0x04,0xb4,0x32,0x56,0xc1,0xfa,0x97,0x1f,0xa6,0xae,0xd7,0x64,0xc3,0xbe,0x42";
BA_ "GenMsgILSupport" BO_ 117 1;
BA_ "GenMsgCycleTime" BO_ 117 1000;
BA_ "GenMsgSendType" BO_ 200 0;
BA_ "GenMsgILSupport" BO_ 200 1;
BA_ "GenMsgCycleTime" BO_ 200 1000;
BA_ "GenMsgSendType" BO_ 1104 0;
BA_ "GenMsgPDUConstants" BO_ 1104 "0x30,0x25,0xc2,0x1f,0x02,0xb1,0x9e,0xe0,0x73,0x51,0xe1,0xa5,0xab,0x0d,0xf4,0x2f";
BA_ "GenMsgILSupport" BO_ 1104 1;
BA_ "GenMsgCycleTime" BO_ 1104 1000;
BA_ "GenMsgSendType" BO_ 2527679714 0;
BA_ "GenMsgILSupport" BO_ 2527679714 1;
BA_ "GenMsgCycleTime" BO_ 2527679714 960;
BA_ "GenMsgSendType" BO_ 278 0;
BA_ "GenMsgPDUConstants" BO_ 278 "0xac,0xac,0xac,0xac,0xac,0xac,0xac,0xac,0xac,0xac,0xac,0xac,0xac,0xac,0xac,0xac";
BA_ "GenMsgILSupport" BO_ 278 1;
BA_ "GenMsgCycleTime" BO_ 278 100;
BA_ "GenMsgChkConstant" BO_ 278 172;
BA_ "GenMsgStartDelayTime" BO_ 418 20;
BA_ "GenMsgSendType" BO_ 418 0;
BA_ "GenMsgPDUConstants" BO_ 418 "0xcb,0x47,0xd7,0xd2,0x56,0x3e,0x20,0xea,0x6e,0x6d,0x8c,0x1b,0xdf,0x49,0xaa,0xab";
BA_ "GenMsgILSupport" BO_ 418 1;
BA_ "GenMsgDelayTime" BO_ 418 20;
BA_ "GenMsgCycleTime" BO_ 418 200;
BA_ "GenMsgSendType" BO_ 1629 0;
BA_ "GenMsgPDUConstants" BO_ 1629 "0xac,0xb3,0xab,0xeb,0x7a,0xe1,0x3b,0xf7,0x73,0xba,0x7c,0x9e,0x06,0x5f,0x02,0xd9";
BA_ "GenMsgILSupport" BO_ 1629 1;
BA_ "GenMsgCycleTime" BO_ 1629 1000;
BA_ "GenMsgSendType" BO_ 795 0;
BA_ "GenMsgPDUConstants" BO_ 795 "0x67,0x8a,0xae,0x22,0x4d,0xd0,0x51,0x80,0x5c,0xb9,0xce,0x1e,0xdf,0x02,0x2d,0xd4";
BA_ "GenMsgILSupport" BO_ 795 1;
BA_ "GenMsgCycleTime" BO_ 795 1000;
BA_ "GenMsgStartDelayTime" BO_ 2463978667 50;
BA_ "GenMsgSendType" BO_ 2463978667 0;
BA_ "GenMsgPDUConstants" BO_ 2463978667 "0xab,0xe1,0x73,0x9e,0x02,0xc2,0x30,0xe9,0x75,0x48,0x2e,0x98,0x7f,0xf5,0xa7,0xb6";
BA_ "GenMsgILSupport" BO_ 2463978667 1;
BA_ "GenMsgDelayTime" BO_ 2463978667 10;
BA_ "GenMsgCycleTime" BO_ 2463978667 1000;
BA_ "GenMsgSendType" BO_ 2527679662 0;
BA_ "GenMsgILSupport" BO_ 2527679662 1;
BA_ "GenMsgCycleTime" BO_ 2527679662 160;
BA_ "GenMsgSendType" BO_ 2463978660 0;
BA_ "GenMsgILSupport" BO_ 2463978660 1;
BA_ "GenMsgDelayTime" BO_ 2463978660 10;
BA_ "GenMsgCycleTime" BO_ 2463978660 100;
BA_ "GenMsgSendType" BO_ 2463978695 0;
BA_ "GenMsgILSupport" BO_ 2463978695 1;
BA_ "GenMsgCycleTime" BO_ 2463978695 100;
BA_ "GenMsgSendType" BO_ 264 0;
BA_ "GenMsgPDUConstants" BO_ 264 "0x09,0x09,0x09,0x09,0x09,0x09,0x09,0x09,0x09,0x09,0x09,0x09,0x09,0x09,0x09,0x09";
BA_ "GenMsgILSupport" BO_ 264 1;
BA_ "GenMsgCycleTime" BO_ 264 200;
BA_ "GenMsgChkConstant" BO_ 264 9;
BA_ "GenMsgSendType" BO_ 222 0;
BA_ "GenMsgILSupport" BO_ 222 1;
BA_ "GenMsgCycleTime" BO_ 222 10;
BA_ "GenMsgSendType" BO_ 379 0;
BA_ "GenMsgILSupport" BO_ 379 1;
BA_ "GenMsgDelayTime" BO_ 379 10;
BA_ "GenMsgCycleTime" BO_ 379 100;
BA_ "GenMsgSendType" BO_ 2463978657 0;
BA_ "GenMsgILSupport" BO_ 2463978657 1;
BA_ "GenMsgCycleTime" BO_ 2463978657 100;
BA_ "GenMsgSendType" BO_ 2589283642 0;
BA_ "GenMsgILSupport" BO_ 2589283642 1;
BA_ "GenMsgCycleTime" BO_ 2589283642 500;
BA_ "GenMsgSendType" BO_ 2589283646 0;
BA_ "GenMsgILSupport" BO_ 2589283646 1;
BA_ "GenMsgCycleTime" BO_ 2589283646 500;
BA_ "GenMsgSendType" BO_ 2463978770 0;
BA_ "GenMsgILSupport" BO_ 2463978770 1;
BA_ "GenMsgCycleTime" BO_ 2463978770 100;
BA_ "GenMsgSendType" BO_ 2463978817 0;
BA_ "GenMsgILSupport" BO_ 2463978817 1;
BA_ "GenMsgCycleTime" BO_ 2463978817 100;
BA_ "GenMsgSendType" BO_ 606 0;
BA_ "GenMsgILSupport" BO_ 606 1;
BA_ "GenMsgCycleTime" BO_ 606 50;
BA_ "GenMsgSendType" BO_ 607 0;
BA_ "GenMsgILSupport" BO_ 607 1;
BA_ "GenMsgCycleTime" BO_ 607 50;
BA_ "GenMsgStartDelayTime" BO_ 177 70;
BA_ "GenMsgSendType" BO_ 177 0;
BA_ "GenMsgPDUConstants" BO_ 177 "0xe1,0x9e,0xc2,0xe9,0x48,0x98,0xf5,0xb6,0x47,0x83,0x26,0x45,0x9a,0x10,0x7b,0x1c";
BA_ "GenMsgILSupport" BO_ 177 1;
BA_ "GenMsgDelayTime" BO_ 177 10;
BA_ "GenMsgCycleTime" BO_ 177 500;
BA_ "GenMsgSendType" BO_ 310 0;
BA_ "GenMsgPDUConstants" BO_ 310 "0x37,0x37,0x37,0x37,0x37,0x37,0x37,0x37,0x37,0x37,0x37,0x37,0x37,0x37,0x37,0x37";
BA_ "GenMsgILSupport" BO_ 310 1;
BA_ "GenMsgCycleTime" BO_ 310 100;
BA_ "GenMsgChkConstant" BO_ 310 55;
BA_ "GenMsgStartDelayTime" BO_ 1452 100;
BA_ "GenMsgSendType" BO_ 1452 0;
BA_ "GenMsgILSupport" BO_ 1452 1;
BA_ "GenMsgCycleTime" BO_ 1452 100;
BA_ "GenMsgStartDelayTime" BO_ 1362 100;
BA_ "GenMsgSendType" BO_ 1362 0;
BA_ "GenMsgILSupport" BO_ 1362 1;
BA_ "GenMsgCycleTime" BO_ 1362 100;
BA_ "GenMsgStartDelayTime" BO_ 1283 10;
BA_ "GenMsgSendType" BO_ 1283 0;
BA_ "GenMsgPDUConstants" BO_ 1283 "0xed,0xd6,0x96,0x63,0xa5,0x12,0xd5,0x9a,0x1e,0x0d,0x24,0xcd,0x8c,0xa6,0x2f,0x41";
BA_ "GenMsgILSupport" BO_ 1283 1;
BA_ "GenMsgDelayTime" BO_ 1283 10;
BA_ "GenMsgCycleTime" BO_ 1283 100;
BA_ "GenMsgSendType" BO_ 1381 0;
BA_ "GenMsgILSupport" BO_ 1381 1;
BA_ "GenMsgDelayTime" BO_ 1381 50;
BA_ "GenMsgCycleTime" BO_ 1381 100;
BA_ "GenMsgSendType" BO_ 1340 0;
BA_ "GenMsgPDUConstants" BO_ 1340 "0x8e,0xf9,0xe1,0x2e,0x83,0x34,0xd0,0xf1,0xaa,0x2c,0xbb,0x81,0x17,0x60,0x11,0x37";
BA_ "GenMsgILSupport" BO_ 1340 1;
BA_ "GenMsgCycleTime" BO_ 1340 100;
BA_ "GenMsgSendType" BO_ 1160 0;
BA_ "GenMsgILSupport" BO_ 1160 1;
BA_ "GenMsgDelayTime" BO_ 1160 100;
BA_ "GenMsgCycleTime" BO_ 1160 1000;
BA_ "GenMsgSendType" BO_ 2589283485 0;
BA_ "GenMsgILSupport" BO_ 2589283485 1;
BA_ "GenMsgDelayTime" BO_ 2589283485 200;
BA_ "GenMsgCycleTime" BO_ 2589283485 2000;
BA_ "GenMsgSendType" BO_ 2589283605 0;
BA_ "GenMsgILSupport" BO_ 2589283605 1;
BA_ "GenMsgCycleTime" BO_ 2589283605 200;
BA_ "GenSigSwitchedByIgnition" SG_ 116 EM2_HYB_12_CRC 0;
BA_ "GenSigFuncType" SG_ 116 EM2_HYB_12_CRC 2;
BA_ "GenSigSendType" SG_ 116 EM2_HYB_12_CRC 0;
BA_ "GenSigSwitchedByIgnition" SG_ 116 EM2_HYB_12_BZ 0;
BA_ "GenSigFuncType" SG_ 116 EM2_HYB_12_BZ 1;
BA_ "GenSigSendType" SG_ 116 EM2_HYB_12_BZ 0;
BA_ "Fehlerwert" SG_ 116 EM2_IstMoment 4095;
BA_ "GenSigSwitchedByIgnition" SG_ 116 EM2_IstMoment 0;
BA_ "GenSigStartValue" SG_ 116 EM2_IstMoment 4094;
BA_ "GenSigSendType" SG_ 116 EM2_IstMoment 0;
BA_ "Fehlerwert" SG_ 116 EM2_IstDrehzahl_alt 32767;
BA_ "GenSigStartValue" SG_ 116 EM2_IstDrehzahl_alt 32766;
BA_ "GenSigSendType" SG_ 116 EM2_IstDrehzahl_alt 0;
BA_ "Fehlerwert" SG_ 116 EM2_IstDrehzahl 32767;
BA_ "GenSigSwitchedByIgnition" SG_ 116 EM2_IstDrehzahl 0;
BA_ "GenSigStartValue" SG_ 116 EM2_IstDrehzahl 32766;
BA_ "GenSigSendType" SG_ 116 EM2_IstDrehzahl 0;
BA_ "GenSigSwitchedByIgnition" SG_ 116 EM2_offene_Klemme_Verfuegbar 0;
BA_ "GenSigSendType" SG_ 116 EM2_offene_Klemme_Verfuegbar 0;
BA_ "Fehlerwert" SG_ 116 EM2_MaxZul_Drehzahl 255;
BA_ "GenSigSwitchedByIgnition" SG_ 116 EM2_MaxZul_Drehzahl 0;
BA_ "GenSigStartValue" SG_ 116 EM2_MaxZul_Drehzahl 254;
BA_ "GenSigSendType" SG_ 116 EM2_MaxZul_Drehzahl 0;
BA_ "GenSigSwitchedByIgnition" SG_ 199 EM2_Freigabe_Info_WFS 0;
BA_ "GenSigSendType" SG_ 199 EM2_Freigabe_Info_WFS 0;
BA_ "GenSigSwitchedByIgnition" SG_ 199 EM2_Sperr_Info_WFS 0;
BA_ "GenSigSendType" SG_ 199 EM2_Sperr_Info_WFS 0;
BA_ "GenSigSwitchedByIgnition" SG_ 199 EM2_AR_aktiv 0;
BA_ "GenSigSendType" SG_ 199 EM2_AR_aktiv 0;
BA_ "Fehlerwert" SG_ 199 EM2_Eta_Sys 511;
BA_ "GenSigSwitchedByIgnition" SG_ 199 EM2_Eta_Sys 0;
BA_ "GenSigStartValue" SG_ 199 EM2_Eta_Sys 510;
BA_ "GenSigSendType" SG_ 199 EM2_Eta_Sys 0;
BA_ "Fehlerwert" SG_ 199 EM2_IstStrom 2047;
BA_ "GenSigSwitchedByIgnition" SG_ 199 EM2_IstStrom 0;
BA_ "GenSigStartValue" SG_ 199 EM2_IstStrom 2046;
BA_ "GenSigSendType" SG_ 199 EM2_IstStrom 0;
BA_ "GenSigSwitchedByIgnition" SG_ 199 EM2_Fehler_ElAntriebFreilauf_Anf 0;
BA_ "GenSigSendType" SG_ 199 EM2_Fehler_ElAntriebFreilauf_Anf 0;
BA_ "GenSigSwitchedByIgnition" SG_ 199 EM2_Abregelung_Temperatur 0;
BA_ "GenSigSendType" SG_ 199 EM2_Abregelung_Temperatur 0;
BA_ "GenSigSwitchedByIgnition" SG_ 199 EM2_AnlernenElMotor_Anf 0;
BA_ "GenSigSendType" SG_ 199 EM2_AnlernenElMotor_Anf 0;
BA_ "GenSigSwitchedByIgnition" SG_ 199 EM2_Freigabe_Verfallsinfo_WFS 0;
BA_ "GenSigSendType" SG_ 199 EM2_Freigabe_Verfallsinfo_WFS 0;
BA_ "GenSigSwitchedByIgnition" SG_ 199 EM2_Parken_WFS_Status 0;
BA_ "GenSigSendType" SG_ 199 EM2_Parken_WFS_Status 0;
BA_ "GenSigSwitchedByIgnition" SG_ 199 EM2_HV_betriebsbereit 0;
BA_ "GenSigSendType" SG_ 199 EM2_HV_betriebsbereit 0;
BA_ "GenSigSwitchedByIgnition" SG_ 1105 EM2_HYB_14_CRC 0;
BA_ "GenSigFuncType" SG_ 1105 EM2_HYB_14_CRC 2;
BA_ "GenSigSendType" SG_ 1105 EM2_HYB_14_CRC 0;
BA_ "GenSigSwitchedByIgnition" SG_ 1105 EM2_HYB_14_BZ 0;
BA_ "GenSigFuncType" SG_ 1105 EM2_HYB_14_BZ 1;
BA_ "GenSigSendType" SG_ 1105 EM2_HYB_14_BZ 0;
BA_ "Fehlerwert" SG_ 1105 EM2_MaxPred_Moment 2047;
BA_ "GenSigSwitchedByIgnition" SG_ 1105 EM2_MaxPred_Moment 0;
BA_ "GenSigStartValue" SG_ 1105 EM2_MaxPred_Moment 2046;
BA_ "GenSigSendType" SG_ 1105 EM2_MaxPred_Moment 0;
BA_ "Fehlerwert" SG_ 1105 EM2_MinPred_Moment 2047;
BA_ "GenSigSwitchedByIgnition" SG_ 1105 EM2_MinPred_Moment 0;
BA_ "GenSigStartValue" SG_ 1105 EM2_MinPred_Moment 2046;
BA_ "GenSigSendType" SG_ 1105 EM2_MinPred_Moment 0;
BA_ "GenSigSwitchedByIgnition" SG_ 1105 EM2_MaxPred_Abknickdrehzahl 0;
BA_ "GenSigStartValue" SG_ 1105 EM2_MaxPred_Abknickdrehzahl 255;
BA_ "GenSigSendType" SG_ 1105 EM2_MaxPred_Abknickdrehzahl 0;
BA_ "GenSigSwitchedByIgnition" SG_ 1105 EM2_MinPred_Abknickdrehzahl 0;
BA_ "GenSigStartValue" SG_ 1105 EM2_MinPred_Abknickdrehzahl 255;
BA_ "GenSigSendType" SG_ 1105 EM2_MinPred_Abknickdrehzahl 0;
BA_ "GenSigSwitchedByIgnition" SG_ 1105 EM2_Fehler_Leistungsred 0;
BA_ "GenSigSendType" SG_ 1105 EM2_Fehler_Leistungsred 0;
BA_ "Fehlerwert" SG_ 1105 EM2_IstSpannung 4095;
BA_ "GenSigSwitchedByIgnition" SG_ 1105 EM2_IstSpannung 0;
BA_ "GenSigStartValue" SG_ 1105 EM2_IstSpannung 4094;
BA_ "GenSigSendType" SG_ 1105 EM2_IstSpannung 0;
BA_ "GenSigSwitchedByIgnition" SG_ 2527679713 EM2_RtmWarnKommunikation 0;
BA_ "GenSigSendType" SG_ 2527679713 EM2_RtmWarnKommunikation 0;
BA_ "GenSigSwitchedByIgnition" SG_ 2527679713 EM2_RtmWarnUeberdrehzahl 0;
BA_ "GenSigSendType" SG_ 2527679713 EM2_RtmWarnUeberdrehzahl 0;
BA_ "GenSigSwitchedByIgnition" SG_ 2527679713 EM2_RtmWarnUeberstrom 0;
BA_ "GenSigSendType" SG_ 2527679713 EM2_RtmWarnUeberstrom 0;
BA_ "GenSigSwitchedByIgnition" SG_ 2527679649 EM3_OBD_Lampe_Anf 0;
BA_ "GenSigSendType" SG_ 2527679649 EM3_OBD_Lampe_Anf 0;
BA_ "GenSigSwitchedByIgnition" SG_ 2527679649 EM3_FoD_Freischaltstatus_Fkt1 0;
BA_ "GenSigSendType" SG_ 2527679649 EM3_FoD_Freischaltstatus_Fkt1 0;
BA_ "Fehlerwert" SG_ 2527679649 EM3_Temperatur_ElMotor 255;
BA_ "GenSigSwitchedByIgnition" SG_ 2527679649 EM3_Temperatur_ElMotor 0;
BA_ "GenSigStartValue" SG_ 2527679649 EM3_Temperatur_ElMotor 254;
BA_ "GenSigSendType" SG_ 2527679649 EM3_Temperatur_ElMotor 0;
BA_ "Fehlerwert" SG_ 2527679649 EM3_Temperatur_PWR 255;
BA_ "GenSigSwitchedByIgnition" SG_ 2527679649 EM3_Temperatur_PWR 0;
BA_ "GenSigStartValue" SG_ 2527679649 EM3_Temperatur_PWR 254;
BA_ "GenSigSendType" SG_ 2527679649 EM3_Temperatur_PWR 0;
BA_ "Fehlerwert" SG_ 2527679649 EM3_Temperatur_Rotor 255;
BA_ "GenSigSwitchedByIgnition" SG_ 2527679649 EM3_Temperatur_Rotor 0;
BA_ "GenSigStartValue" SG_ 2527679649 EM3_Temperatur_Rotor 254;
BA_ "GenSigSendType" SG_ 2527679649 EM3_Temperatur_Rotor 0;
BA_ "Fehlerwert" SG_ 2527679649 EM3_Verlustleistung_02 1023;
BA_ "GenSigSwitchedByIgnition" SG_ 2527679649 EM3_Verlustleistung_02 0;
BA_ "GenSigStartValue" SG_ 2527679649 EM3_Verlustleistung_02 1022;
BA_ "GenSigSendType" SG_ 2527679649 EM3_Verlustleistung_02 0;
BA_ "Fehlerwert" SG_ 2527679649 EM3_Temperatur_KW 255;
BA_ "GenSigSwitchedByIgnition" SG_ 2527679649 EM3_Temperatur_KW 0;
BA_ "GenSigStartValue" SG_ 2527679649 EM3_Temperatur_KW 254;
BA_ "GenSigSendType" SG_ 2527679649 EM3_Temperatur_KW 0;
BA_ "GenSigSwitchedByIgnition" SG_ 2463978616 EM3_HYB_11_CRC 0;
BA_ "GenSigFuncType" SG_ 2463978616 EM3_HYB_11_CRC 2;
BA_ "GenSigSendType" SG_ 2463978616 EM3_HYB_11_CRC 0;
BA_ "GenSigSwitchedByIgnition" SG_ 2463978616 EM3_HYB_11_BZ 0;
BA_ "GenSigFuncType" SG_ 2463978616 EM3_HYB_11_BZ 1;
BA_ "GenSigSendType" SG_ 2463978616 EM3_HYB_11_BZ 0;
BA_ "GenSigSwitchedByIgnition" SG_ 2463978616 EM3_Istmodus2 0;
BA_ "GenSigStartValue" SG_ 2463978616 EM3_Istmodus2 15;
BA_ "GenSigSendType" SG_ 2463978616 EM3_Istmodus2 3;
BA_ "GenSigSwitchedByIgnition" SG_ 2463978616 EM3_Fehlerstatus 0;
BA_ "GenSigStartValue" SG_ 2463978616 EM3_Fehlerstatus 7;
BA_ "GenSigSendType" SG_ 2463978616 EM3_Fehlerstatus 3;
BA_ "GenSigSwitchedByIgnition" SG_ 2463978616 EM3_Status_Spgfreiheit 0;
BA_ "GenSigSendType" SG_ 2463978616 EM3_Status_Spgfreiheit 3;
BA_ "GenSigSwitchedByIgnition" SG_ 2463978616 EM3_HYB_11_Sendestatus 0;
BA_ "GenSigSendType" SG_ 2463978616 EM3_HYB_11_Sendestatus 9;
BA_ "GenSigActiveRepetitions" SG_ 2463978616 EM3_HYB_11_Sendestatus 5;
BA_ "Fehlerwert" SG_ 2463978616 EM3_EM_SollVolumenstrom 63;
BA_ "GenSigSwitchedByIgnition" SG_ 2463978616 EM3_EM_SollVolumenstrom 0;
BA_ "GenSigStartValue" SG_ 2463978616 EM3_EM_SollVolumenstrom 62;
BA_ "GenSigSendType" SG_ 2463978616 EM3_EM_SollVolumenstrom 3;
BA_ "GenSigSwitchedByIgnition" SG_ 117 EM3_HYB_12_CRC 0;
BA_ "GenSigFuncType" SG_ 117 EM3_HYB_12_CRC 2;
BA_ "GenSigSendType" SG_ 117 EM3_HYB_12_CRC 0;
BA_ "GenSigSwitchedByIgnition" SG_ 117 EM3_HYB_12_BZ 0;
BA_ "GenSigFuncType" SG_ 117 EM3_HYB_12_BZ 1;
BA_ "GenSigSendType" SG_ 117 EM3_HYB_12_BZ 0;
BA_ "Fehlerwert" SG_ 117 EM3_IstMoment 4095;
BA_ "GenSigSwitchedByIgnition" SG_ 117 EM3_IstMoment 0;
BA_ "GenSigStartValue" SG_ 117 EM3_IstMoment 4094;
BA_ "GenSigSendType" SG_ 117 EM3_IstMoment 0;
BA_ "Fehlerwert" SG_ 117 EM3_IstDrehzahl_alt 32767;
BA_ "GenSigStartValue" SG_ 117 EM3_IstDrehzahl_alt 32766;
BA_ "GenSigSendType" SG_ 117 EM3_IstDrehzahl_alt 0;
BA_ "Fehlerwert" SG_ 117 EM3_IstDrehzahl 32767;
BA_ "GenSigSwitchedByIgnition" SG_ 117 EM3_IstDrehzahl 0;
BA_ "GenSigStartValue" SG_ 117 EM3_IstDrehzahl 32766;
BA_ "GenSigSendType" SG_ 117 EM3_IstDrehzahl 0;
BA_ "GenSigSwitchedByIgnition" SG_ 117 EM3_offene_Klemme_Verfuegbar 0;
BA_ "GenSigSendType" SG_ 117 EM3_offene_Klemme_Verfuegbar 0;
BA_ "Fehlerwert" SG_ 117 EM3_MaxZul_Drehzahl 255;
BA_ "GenSigSwitchedByIgnition" SG_ 117 EM3_MaxZul_Drehzahl 0;
BA_ "GenSigStartValue" SG_ 117 EM3_MaxZul_Drehzahl 254;
BA_ "GenSigSendType" SG_ 117 EM3_MaxZul_Drehzahl 0;
BA_ "GenSigSwitchedByIgnition" SG_ 200 EM3_Freigabe_Info_WFS 0;
BA_ "GenSigSendType" SG_ 200 EM3_Freigabe_Info_WFS 0;
BA_ "GenSigSwitchedByIgnition" SG_ 200 EM3_Sperr_Info_WFS 0;
BA_ "GenSigSendType" SG_ 200 EM3_Sperr_Info_WFS 0;
BA_ "GenSigSwitchedByIgnition" SG_ 200 EM3_AR_aktiv 0;
BA_ "GenSigSendType" SG_ 200 EM3_AR_aktiv 0;
BA_ "Fehlerwert" SG_ 200 EM3_Eta_Sys 511;
BA_ "GenSigSwitchedByIgnition" SG_ 200 EM3_Eta_Sys 0;
BA_ "GenSigStartValue" SG_ 200 EM3_Eta_Sys 510;
BA_ "GenSigSendType" SG_ 200 EM3_Eta_Sys 0;
BA_ "Fehlerwert" SG_ 200 EM3_IstStrom 2047;
BA_ "GenSigSwitchedByIgnition" SG_ 200 EM3_IstStrom 0;
BA_ "GenSigStartValue" SG_ 200 EM3_IstStrom 2046;
BA_ "GenSigSendType" SG_ 200 EM3_IstStrom 0;
BA_ "GenSigSwitchedByIgnition" SG_ 200 EM3_Fehler_ElAntriebFreilauf_Anf 0;
BA_ "GenSigSendType" SG_ 200 EM3_Fehler_ElAntriebFreilauf_Anf 0;
BA_ "GenSigSwitchedByIgnition" SG_ 200 EM3_Abregelung_Temperatur 0;
BA_ "GenSigSendType" SG_ 200 EM3_Abregelung_Temperatur 0;
BA_ "GenSigSwitchedByIgnition" SG_ 200 EM3_AnlernenElMotor_Anf 0;
BA_ "GenSigSendType" SG_ 200 EM3_AnlernenElMotor_Anf 0;
BA_ "GenSigSwitchedByIgnition" SG_ 200 EM3_Freigabe_Verfallsinfo_WFS 0;
BA_ "GenSigSendType" SG_ 200 EM3_Freigabe_Verfallsinfo_WFS 0;
BA_ "GenSigSwitchedByIgnition" SG_ 200 EM3_Parken_WFS_Status 0;
BA_ "GenSigSendType" SG_ 200 EM3_Parken_WFS_Status 0;
BA_ "GenSigSwitchedByIgnition" SG_ 200 EM3_HV_betriebsbereit 0;
BA_ "GenSigSendType" SG_ 200 EM3_HV_betriebsbereit 0;
BA_ "GenSigSwitchedByIgnition" SG_ 1104 EM3_HYB_14_CRC 0;
BA_ "GenSigFuncType" SG_ 1104 EM3_HYB_14_CRC 2;
BA_ "GenSigSendType" SG_ 1104 EM3_HYB_14_CRC 0;
BA_ "GenSigSwitchedByIgnition" SG_ 1104 EM3_HYB_14_BZ 0;
BA_ "GenSigFuncType" SG_ 1104 EM3_HYB_14_BZ 1;
BA_ "GenSigSendType" SG_ 1104 EM3_HYB_14_BZ 0;
BA_ "Fehlerwert" SG_ 1104 EM3_MaxPred_Moment 2047;
BA_ "GenSigSwitchedByIgnition" SG_ 1104 EM3_MaxPred_Moment 0;
BA_ "GenSigStartValue" SG_ 1104 EM3_MaxPred_Moment 2046;
BA_ "GenSigSendType" SG_ 1104 EM3_MaxPred_Moment 0;
BA_ "Fehlerwert" SG_ 1104 EM3_MinPred_Moment 2047;
BA_ "GenSigSwitchedByIgnition" SG_ 1104 EM3_MinPred_Moment 0;
BA_ "GenSigStartValue" SG_ 1104 EM3_MinPred_Moment 2046;
BA_ "GenSigSendType" SG_ 1104 EM3_MinPred_Moment 0;
BA_ "GenSigSwitchedByIgnition" SG_ 1104 EM3_MaxPred_Abknickdrehzahl 0;
BA_ "GenSigStartValue" SG_ 1104 EM3_MaxPred_Abknickdrehzahl 255;
BA_ "GenSigSendType" SG_ 1104 EM3_MaxPred_Abknickdrehzahl 0;
BA_ "GenSigSwitchedByIgnition" SG_ 1104 EM3_MinPred_Abknickdrehzahl 0;
BA_ "GenSigStartValue" SG_ 1104 EM3_MinPred_Abknickdrehzahl 255;
BA_ "GenSigSendType" SG_ 1104 EM3_MinPred_Abknickdrehzahl 0;
BA_ "GenSigSwitchedByIgnition" SG_ 1104 EM3_Fehler_Leistungsred 0;
BA_ "GenSigSendType" SG_ 1104 EM3_Fehler_Leistungsred 0;
BA_ "Fehlerwert" SG_ 1104 EM3_IstSpannung 4095;
BA_ "GenSigSwitchedByIgnition" SG_ 1104 EM3_IstSpannung 0;
BA_ "GenSigStartValue" SG_ 1104 EM3_IstSpannung 4094;
BA_ "GenSigSendType" SG_ 1104 EM3_IstSpannung 0;
BA_ "GenSigSwitchedByIgnition" SG_ 2527679714 EM3_RtmWarnKommunikation 0;
BA_ "GenSigSendType" SG_ 2527679714 EM3_RtmWarnKommunikation 0;
BA_ "GenSigSwitchedByIgnition" SG_ 2527679714 EM3_RtmWarnUeberdrehzahl 0;
BA_ "GenSigSendType" SG_ 2527679714 EM3_RtmWarnUeberdrehzahl 0;
BA_ "GenSigSwitchedByIgnition" SG_ 2527679714 EM3_RtmWarnUeberstrom 0;
BA_ "GenSigSendType" SG_ 2527679714 EM3_RtmWarnUeberstrom 0;
BA_ "GenSigSwitchedByIgnition" SG_ 278 ESP_10_CRC 0;
BA_ "GenSigFuncType" SG_ 278 ESP_10_CRC 2;
BA_ "GenSigSendType" SG_ 278 ESP_10_CRC 0;
BA_ "GenSigSwitchedByIgnition" SG_ 278 ESP_10_BZ 0;
BA_ "GenSigFuncType" SG_ 278 ESP_10_BZ 1;
BA_ "GenSigSendType" SG_ 278 ESP_10_BZ 0;
BA_ "GenSigSwitchedByIgnition" SG_ 278 ESP_QBit_Wegimpuls_VL 0;
BA_ "GenSigStartValue" SG_ 278 ESP_QBit_Wegimpuls_VL 1;
BA_ "GenSigSendType" SG_ 278 ESP_QBit_Wegimpuls_VL 0;
BA_ "GenSigSwitchedByIgnition" SG_ 278 ESP_QBit_Wegimpuls_VR 0;
BA_ "GenSigStartValue" SG_ 278 ESP_QBit_Wegimpuls_VR 1;
BA_ "GenSigSendType" SG_ 278 ESP_QBit_Wegimpuls_VR 0;
BA_ "GenSigSwitchedByIgnition" SG_ 278 ESP_QBit_Wegimpuls_HL 0;
BA_ "GenSigStartValue" SG_ 278 ESP_QBit_Wegimpuls_HL 1;
BA_ "GenSigSendType" SG_ 278 ESP_QBit_Wegimpuls_HL 0;
BA_ "GenSigSwitchedByIgnition" SG_ 278 ESP_QBit_Wegimpuls_HR 0;
BA_ "GenSigStartValue" SG_ 278 ESP_QBit_Wegimpuls_HR 1;
BA_ "GenSigSendType" SG_ 278 ESP_QBit_Wegimpuls_HR 0;
BA_ "Fehlerwert" SG_ 278 ESP_Wegimpuls_VL 1023;
BA_ "GenSigSwitchedByIgnition" SG_ 278 ESP_Wegimpuls_VL 0;
BA_ "GenSigStartValue" SG_ 278 ESP_Wegimpuls_VL 1021;
BA_ "GenSigSendType" SG_ 278 ESP_Wegimpuls_VL 0;
BA_ "Fehlerwert" SG_ 278 ESP_Wegimpuls_VR 1023;
BA_ "GenSigSwitchedByIgnition" SG_ 278 ESP_Wegimpuls_VR 0;
BA_ "GenSigStartValue" SG_ 278 ESP_Wegimpuls_VR 1021;
BA_ "GenSigSendType" SG_ 278 ESP_Wegimpuls_VR 0;
BA_ "Fehlerwert" SG_ 278 ESP_Wegimpuls_HL 1023;
BA_ "GenSigSwitchedByIgnition" SG_ 278 ESP_Wegimpuls_HL 0;
BA_ "GenSigStartValue" SG_ 278 ESP_Wegimpuls_HL 1021;
BA_ "GenSigSendType" SG_ 278 ESP_Wegimpuls_HL 0;
BA_ "Fehlerwert" SG_ 278 ESP_Wegimpuls_HR 1023;
BA_ "GenSigSwitchedByIgnition" SG_ 278 ESP_Wegimpuls_HR 0;
BA_ "GenSigStartValue" SG_ 278 ESP_Wegimpuls_HR 1021;
BA_ "GenSigSendType" SG_ 278 ESP_Wegimpuls_HR 0;
BA_ "GenSigSwitchedByIgnition" SG_ 278 ESP_VL_Fahrtrichtung 0;
BA_ "GenSigStartValue" SG_ 278 ESP_VL_Fahrtrichtung 2;
BA_ "GenSigSendType" SG_ 278 ESP_VL_Fahrtrichtung 0;
BA_ "GenSigSwitchedByIgnition" SG_ 278 ESP_VR_Fahrtrichtung 0;
BA_ "GenSigStartValue" SG_ 278 ESP_VR_Fahrtrichtung 2;
BA_ "GenSigSendType" SG_ 278 ESP_VR_Fahrtrichtung 0;
BA_ "GenSigSwitchedByIgnition" SG_ 278 ESP_HL_Fahrtrichtung 0;
BA_ "GenSigStartValue" SG_ 278 ESP_HL_Fahrtrichtung 2;
BA_ "GenSigSendType" SG_ 278 ESP_HL_Fahrtrichtung 0;
BA_ "GenSigSwitchedByIgnition" SG_ 278 ESP_HR_Fahrtrichtung 0;
BA_ "GenSigStartValue" SG_ 278 ESP_HR_Fahrtrichtung 2;
BA_ "GenSigSendType" SG_ 278 ESP_HR_Fahrtrichtung 0;
BA_ "GenSigSwitchedByIgnition" SG_ 418 ESP_15_CRC 0;
BA_ "GenSigFuncType" SG_ 418 ESP_15_CRC 2;
BA_ "GenSigSendType" SG_ 418 ESP_15_CRC 0;
BA_ "GenSigSwitchedByIgnition" SG_ 418 ESP_15_BZ 0;
BA_ "GenSigFuncType" SG_ 418 ESP_15_BZ 1;
BA_ "GenSigSendType" SG_ 418 ESP_15_BZ 0;
BA_ "Fehlerwert" SG_ 418 HMS_P_beibehalten_GE 3;
BA_ "GenSigSwitchedByIgnition" SG_ 418 HMS_P_beibehalten_GE 0;
BA_ "GenSigStartValue" SG_ 418 HMS_P_beibehalten_GE 2;
BA_ "GenSigSendType" SG_ 418 HMS_P_beibehalten_GE 0;
BA_ "GenSigSwitchedByIgnition" SG_ 418 HMS_Konsistenz_GE 0;
BA_ "GenSigSendType" SG_ 418 HMS_Konsistenz_GE 0;
BA_ "GenSigSwitchedByIgnition" SG_ 418 HMS_Konsistenz_IPA 0;
BA_ "GenSigSendType" SG_ 418 HMS_Konsistenz_IPA 3;
BA_ "GenSigSwitchedByIgnition" SG_ 418 HMS_Konsistenz_STA 0;
BA_ "GenSigSendType" SG_ 418 HMS_Konsistenz_STA 0;
BA_ "GenSigSwitchedByIgnition" SG_ 418 HMS_Konsistenz_MO 0;
BA_ "GenSigSendType" SG_ 418 HMS_Konsistenz_MO 0;
BA_ "GenSigSwitchedByIgnition" SG_ 418 HMS_halten_nicht_verfuegbar 0;
BA_ "GenSigSendType" SG_ 418 HMS_halten_nicht_verfuegbar 0;
BA_ "GenSigSwitchedByIgnition" SG_ 418 NL_PRIM_STP_01_Status 0;
BA_ "GenSigSendType" SG_ 418 NL_PRIM_STP_01_Status 0;
BA_ "GenSigSwitchedByIgnition" SG_ 418 VMM_Warnblinken 0;
BA_ "GenSigSendType" SG_ 418 VMM_Warnblinken 3;
BA_ "Fehlerwert" SG_ 418 VZM_Status 4;
BA_ "GenSigSwitchedByIgnition" SG_ 418 VZM_Status 0;
BA_ "GenSigSendType" SG_ 418 VZM_Status 0;
BA_ "GenSigSwitchedByIgnition" SG_ 418 HMS_Notstopp_Status 0;
BA_ "GenSigSendType" SG_ 418 HMS_Notstopp_Status 0;
BA_ "GenSigSwitchedByIgnition" SG_ 418 HMS_parken_nicht_verfuegbar 0;
BA_ "GenSigSendType" SG_ 418 HMS_parken_nicht_verfuegbar 0;
BA_ "GenSigSwitchedByIgnition" SG_ 418 HMS_Anforderung_GE 0;
BA_ "GenSigSendType" SG_ 418 HMS_Anforderung_GE 0;
BA_ "Fehlerwert" SG_ 418 HMS_Systemstatus 15;
BA_ "GenSigSwitchedByIgnition" SG_ 418 HMS_Systemstatus 0;
BA_ "GenSigStartValue" SG_ 418 HMS_Systemstatus 14;
BA_ "GenSigSendType" SG_ 418 HMS_Systemstatus 3;
BA_ "Fehlerwert" SG_ 418 HMS_Stillstand 7;
BA_ "GenSigSwitchedByIgnition" SG_ 418 HMS_Stillstand 0;
BA_ "GenSigStartValue" SG_ 418 HMS_Stillstand 6;
BA_ "GenSigSendType" SG_ 418 HMS_Stillstand 3;
BA_ "GenSigSwitchedByIgnition" SG_ 418 HMS_aktives_System 0;
BA_ "GenSigSendType" SG_ 418 HMS_aktives_System 3;
BA_ "GenSigSwitchedByIgnition" SG_ 418 HMS_Konsistenz_HVLM 0;
BA_ "GenSigSendType" SG_ 418 HMS_Konsistenz_HVLM 3;
BA_ "GenSigSwitchedByIgnition" SG_ 418 HMS_Konsistenz_ACC 0;
BA_ "GenSigSendType" SG_ 418 HMS_Konsistenz_ACC 0;
BA_ "GenSigSwitchedByIgnition" SG_ 418 HMS_Fehlerstatus 0;
BA_ "GenSigSendType" SG_ 418 HMS_Fehlerstatus 3;
BA_ "GenSigSwitchedByIgnition" SG_ 418 ESP_Index_Haltemoment 0;
BA_ "GenSigSendType" SG_ 418 ESP_Index_Haltemoment 0;
BA_ "Fehlerwert" SG_ 418 ESP_Haltemoment 1023;
BA_ "GenSigSwitchedByIgnition" SG_ 418 ESP_Haltemoment 0;
BA_ "GenSigStartValue" SG_ 418 ESP_Haltemoment 1022;
BA_ "GenSigSendType" SG_ 418 ESP_Haltemoment 0;
BA_ "GenSigSwitchedByIgnition" SG_ 1629 ESP_20_CRC 0;
BA_ "GenSigFuncType" SG_ 1629 ESP_20_CRC 2;
BA_ "GenSigSendType" SG_ 1629 ESP_20_CRC 0;
BA_ "GenSigSwitchedByIgnition" SG_ 1629 ESP_20_BZ 0;
BA_ "GenSigFuncType" SG_ 1629 ESP_20_BZ 1;
BA_ "GenSigSendType" SG_ 1629 ESP_20_BZ 0;
BA_ "GenSigSwitchedByIgnition" SG_ 1629 BR_Systemart 0;
BA_ "GenSigFuncType" SG_ 1629 BR_Systemart 8;
BA_ "GenSigSendType" SG_ 1629 BR_Systemart 0;
BA_ "GenSigSwitchedByIgnition" SG_ 1629 ESP_SpannungsAnf_02 0;
BA_ "GenSigSendType" SG_ 1629 ESP_SpannungsAnf_02 0;
BA_ "GenSigSwitchedByIgnition" SG_ 1629 ESP_Zaehnezahl 0;
BA_ "GenSigFuncType" SG_ 1629 ESP_Zaehnezahl 8;
BA_ "GenSigSendType" SG_ 1629 ESP_Zaehnezahl 0;
BA_ "GenSigSwitchedByIgnition" SG_ 1629 ESP_Charisma_FahrPr 0;
BA_ "GenSigSendType" SG_ 1629 ESP_Charisma_FahrPr 0;
BA_ "GenSigSwitchedByIgnition" SG_ 1629 ESP_Charisma_Status 0;
BA_ "GenSigSendType" SG_ 1629 ESP_Charisma_Status 0;
BA_ "GenSigSwitchedByIgnition" SG_ 1629 ESP_Wiederstart_Anz_01 0;
BA_ "GenSigSendType" SG_ 1629 ESP_Wiederstart_Anz_01 0;
BA_ "GenSigSwitchedByIgnition" SG_ 1629 ESP_Wiederstart_Anz_02 0;
BA_ "GenSigSendType" SG_ 1629 ESP_Wiederstart_Anz_02 0;
BA_ "GenSigSwitchedByIgnition" SG_ 1629 ESP_Wiederstart_Anz_03 0;
BA_ "GenSigSendType" SG_ 1629 ESP_Wiederstart_Anz_03 0;
BA_ "GenSigSwitchedByIgnition" SG_ 1629 ESP_Wiederstart_Anz_04 0;
BA_ "GenSigSendType" SG_ 1629 ESP_Wiederstart_Anz_04 0;
BA_ "GenSigSwitchedByIgnition" SG_ 1629 ESP_Stoppverbot_Anz_01 0;
BA_ "GenSigSendType" SG_ 1629 ESP_Stoppverbot_Anz_01 0;
BA_ "GenSigSwitchedByIgnition" SG_ 1629 ESP_Stoppverbot_Anz_02 0;
BA_ "GenSigSendType" SG_ 1629 ESP_Stoppverbot_Anz_02 0;
BA_ "GenSigSwitchedByIgnition" SG_ 1629 ESP_Stoppverbot_Anz_03 0;
BA_ "GenSigSendType" SG_ 1629 ESP_Stoppverbot_Anz_03 0;
BA_ "GenSigSwitchedByIgnition" SG_ 1629 ESP_Stoppverbot_Anz_04 0;
BA_ "GenSigSendType" SG_ 1629 ESP_Stoppverbot_Anz_04 0;
BA_ "GenSigSwitchedByIgnition" SG_ 1629 ESP_Stoppverbot_Anz_05 0;
BA_ "GenSigSendType" SG_ 1629 ESP_Stoppverbot_Anz_05 0;
BA_ "GenSigSwitchedByIgnition" SG_ 1629 ESP_Stoppverbot_Anz_06 0;
BA_ "GenSigSendType" SG_ 1629 ESP_Stoppverbot_Anz_06 0;
BA_ "GenSigSwitchedByIgnition" SG_ 1629 ESP_Stoppverbot_Anz_07 0;
BA_ "GenSigSendType" SG_ 1629 ESP_Stoppverbot_Anz_07 0;
BA_ "GenSigSendType" SG_ 1629 ESP_Stoppverbot_Anz_Std 0;
BA_ "Fehlerwert" SG_ 1629 ESP_Dachrelingsensor 3;
BA_ "GenSigSwitchedByIgnition" SG_ 1629 ESP_Dachrelingsensor 0;
BA_ "GenSigSendType" SG_ 1629 ESP_Dachrelingsensor 0;
BA_ "GenSigSwitchedByIgnition" SG_ 1629 ESP_Stoppverbot_Anz_08 0;
BA_ "GenSigSendType" SG_ 1629 ESP_Stoppverbot_Anz_08 0;
BA_ "GenSigSwitchedByIgnition" SG_ 1629 HDC_Charisma_FahrPr 0;
BA_ "GenSigSendType" SG_ 1629 HDC_Charisma_FahrPr 0;
BA_ "GenSigSwitchedByIgnition" SG_ 1629 HDC_Charisma_Status 0;
BA_ "GenSigSendType" SG_ 1629 HDC_Charisma_Status 0;
BA_ "GenSigSwitchedByIgnition" SG_ 1629 BR_QBit_Reifenumfang 0;
BA_ "GenSigStartValue" SG_ 1629 BR_QBit_Reifenumfang 1;
BA_ "GenSigSendType" SG_ 1629 BR_QBit_Reifenumfang 0;
BA_ "GenSigSwitchedByIgnition" SG_ 1629 BR_Reifenumfang 0;
BA_ "GenSigSendType" SG_ 1629 BR_Reifenumfang 0;
BA_ "GenSigSwitchedByIgnition" SG_ 795 ESP_24_CRC 0;
BA_ "GenSigFuncType" SG_ 795 ESP_24_CRC 2;
BA_ "GenSigSendType" SG_ 795 ESP_24_CRC 0;
BA_ "GenSigSwitchedByIgnition" SG_ 795 ESP_24_BZ 0;
BA_ "GenSigFuncType" SG_ 795 ESP_24_BZ 1;
BA_ "GenSigSendType" SG_ 795 ESP_24_BZ 0;
BA_ "GenSigSwitchedByIgnition" SG_ 795 ESP_Lampe 0;
BA_ "GenSigStartValue" SG_ 795 ESP_Lampe 1;
BA_ "GenSigSendType" SG_ 795 ESP_Lampe 0;
BA_ "GenSigSwitchedByIgnition" SG_ 795 ABS_Lampe 0;
BA_ "GenSigStartValue" SG_ 795 ABS_Lampe 1;
BA_ "GenSigSendType" SG_ 795 ABS_Lampe 0;
BA_ "GenSigSwitchedByIgnition" SG_ 795 BK_Lampe_02 0;
BA_ "GenSigStartValue" SG_ 795 BK_Lampe_02 1;
BA_ "GenSigSendType" SG_ 795 BK_Lampe_02 0;
BA_ "GenSigSendType" SG_ 795 TC_Lampe 0;
BA_ "Fehlerwert" SG_ 795 ESP_m_Raddrehz 32767;
BA_ "GenSigSwitchedByIgnition" SG_ 795 ESP_m_Raddrehz 0;
BA_ "GenSigStartValue" SG_ 795 ESP_m_Raddrehz 32766;
BA_ "GenSigSendType" SG_ 795 ESP_m_Raddrehz 0;
BA_ "GenSigSwitchedByIgnition" SG_ 795 ESP_Textanzeigen_03 0;
BA_ "GenSigSendType" SG_ 795 ESP_Textanzeigen_03 0;
BA_ "GenSigSwitchedByIgnition" SG_ 795 ESP_Meldungen 0;
BA_ "GenSigSendType" SG_ 795 ESP_Meldungen 0;
BA_ "GenSigSwitchedByIgnition" SG_ 795 ESP_Wegimp_VA 0;
BA_ "GenSigSendType" SG_ 795 ESP_Wegimp_VA 0;
BA_ "GenSigSwitchedByIgnition" SG_ 795 ESP_Fehlerstatus_Wegimp 0;
BA_ "GenSigSendType" SG_ 795 ESP_Fehlerstatus_Wegimp 0;
BA_ "GenSigSwitchedByIgnition" SG_ 795 ESP_Wegimp_Ueberlauf 0;
BA_ "GenSigSendType" SG_ 795 ESP_Wegimp_Ueberlauf 0;
BA_ "GenSigSwitchedByIgnition" SG_ 795 ESP_QBit_Wegimp_VA 0;
BA_ "GenSigStartValue" SG_ 795 ESP_QBit_Wegimp_VA 1;
BA_ "GenSigSendType" SG_ 795 ESP_QBit_Wegimp_VA 0;
BA_ "GenSigSwitchedByIgnition" SG_ 795 ESP_HDC_Geschw_Farbe 0;
BA_ "GenSigSendType" SG_ 795 ESP_HDC_Geschw_Farbe 0;
BA_ "GenSigSwitchedByIgnition" SG_ 795 ESP_Off_Lampe 0;
BA_ "GenSigSendType" SG_ 795 ESP_Off_Lampe 0;
BA_ "Fehlerwert" SG_ 795 ESP_HDC_Regelgeschw 127;
BA_ "GenSigSwitchedByIgnition" SG_ 795 ESP_HDC_Regelgeschw 0;
BA_ "GenSigStartValue" SG_ 795 ESP_HDC_Regelgeschw 126;
BA_ "GenSigSendType" SG_ 795 ESP_HDC_Regelgeschw 0;
BA_ "GenSigSwitchedByIgnition" SG_ 795 ESP_BKV_Warnung 0;
BA_ "GenSigSendType" SG_ 795 ESP_BKV_Warnung 0;
BA_ "GenSigSwitchedByIgnition" SG_ 2463978667 ESP_25_CRC 0;
BA_ "GenSigFuncType" SG_ 2463978667 ESP_25_CRC 2;
BA_ "GenSigSendType" SG_ 2463978667 ESP_25_CRC 0;
BA_ "GenSigSwitchedByIgnition" SG_ 2463978667 ESP_25_BZ 0;
BA_ "GenSigFuncType" SG_ 2463978667 ESP_25_BZ 1;
BA_ "GenSigSendType" SG_ 2463978667 ESP_25_BZ 0;
BA_ "Fehlerwert" SG_ 2463978667 ESCGeneratorSollMoment 4095;
BA_ "GenSigSwitchedByIgnition" SG_ 2463978667 ESCGeneratorSollMoment 0;
BA_ "GenSigStartValue" SG_ 2463978667 ESCGeneratorSollMoment 4094;
BA_ "GenSigSendType" SG_ 2463978667 ESCGeneratorSollMoment 0;
BA_ "Fehlerwert" SG_ 2463978667 TSMomBegrenzung 4095;
BA_ "GenSigSwitchedByIgnition" SG_ 2463978667 TSMomBegrenzung 0;
BA_ "GenSigStartValue" SG_ 2463978667 TSMomBegrenzung 4094;
BA_ "GenSigSendType" SG_ 2463978667 TSMomBegrenzung 0;
BA_ "GenSigSwitchedByIgnition" SG_ 2463978667 ESC_Anf_Mindestreku 0;
BA_ "GenSigSendType" SG_ 2463978667 ESC_Anf_Mindestreku 3;
BA_ "GenSigSwitchedByIgnition" SG_ 2463978667 ESC_Status_Schaltkennfeld_sek 0;
BA_ "GenSigSendType" SG_ 2463978667 ESC_Status_Schaltkennfeld_sek 0;
BA_ "Fehlerwert" SG_ 2463978667 ESP_M_hyd_anteil_Bremse 4095;
BA_ "GenSigSwitchedByIgnition" SG_ 2463978667 ESP_M_hyd_anteil_Bremse 0;
BA_ "GenSigStartValue" SG_ 2463978667 ESP_M_hyd_anteil_Bremse 4094;
BA_ "GenSigSendType" SG_ 2463978667 ESP_M_hyd_anteil_Bremse 0;
BA_ "GenSigSwitchedByIgnition" SG_ 2527679662 ESC_Anf_Luefternachlauf 0;
BA_ "GenSigSendType" SG_ 2527679662 ESC_Anf_Luefternachlauf 0;
BA_ "GenSigSwitchedByIgnition" SG_ 2527679662 ESC_Reku_Anzeige 0;
BA_ "GenSigSendType" SG_ 2527679662 ESC_Reku_Anzeige 0;
BA_ "GenSigSwitchedByIgnition" SG_ 2527679662 ESC_Anf_LadeVorhalt 0;
BA_ "GenSigStartValue" SG_ 2527679662 ESC_Anf_LadeVorhalt 15;
BA_ "GenSigSendType" SG_ 2527679662 ESC_Anf_LadeVorhalt 0;
BA_ "GenSigSwitchedByIgnition" SG_ 2527679662 ESC_Textanzeigen_SysSpez 0;
BA_ "GenSigSendType" SG_ 2527679662 ESC_Textanzeigen_SysSpez 0;
BA_ "GenSigSwitchedByIgnition" SG_ 2527679662 BRS_BFLS_Verbauzustand 0;
BA_ "GenSigSendType" SG_ 2527679662 BRS_BFLS_Verbauzustand 0;
BA_ "GenSigSwitchedByIgnition" SG_ 2527679662 BRS_Bremsfluessigkeit_Warnungen 0;
BA_ "GenSigSendType" SG_ 2527679662 BRS_Bremsfluessigkeit_Warnungen 0;
BA_ "GenSigSwitchedByIgnition" SG_ 2527679662 ESC_Anf_Bremsenkuehlung 0;
BA_ "GenSigSendType" SG_ 2527679662 ESC_Anf_Bremsenkuehlung 0;
BA_ "GenSigSwitchedByIgnition" SG_ 2463978660 ETL_IstModus 0;
BA_ "GenSigSendType" SG_ 2463978660 ETL_IstModus 0;
BA_ "Fehlerwert" SG_ 2463978660 ETL_IstLeistung 255;
BA_ "GenSigSwitchedByIgnition" SG_ 2463978660 ETL_IstLeistung 0;
BA_ "GenSigStartValue" SG_ 2463978660 ETL_IstLeistung 127;
BA_ "GenSigSendType" SG_ 2463978660 ETL_IstLeistung 0;
BA_ "Fehlerwert" SG_ 2463978660 ETL_IstSpannung 511;
BA_ "GenSigSwitchedByIgnition" SG_ 2463978660 ETL_IstSpannung 0;
BA_ "GenSigSendType" SG_ 2463978660 ETL_IstSpannung 0;
BA_ "Fehlerwert" SG_ 2463978660 ETL_Fehler_Blockiert 1;
BA_ "GenSigSwitchedByIgnition" SG_ 2463978660 ETL_Fehler_Blockiert 0;
BA_ "GenSigSendType" SG_ 2463978660 ETL_Fehler_Blockiert 0;
BA_ "Fehlerwert" SG_ 2463978660 ETL_Fehler_Bauteil_Defekt 1;
BA_ "GenSigSwitchedByIgnition" SG_ 2463978660 ETL_Fehler_Bauteil_Defekt 0;
BA_ "GenSigSendType" SG_ 2463978660 ETL_Fehler_Bauteil_Defekt 0;
BA_ "Fehlerwert" SG_ 2463978660 ETL_Fehler_Ueberspannung_HV 1;
BA_ "GenSigSwitchedByIgnition" SG_ 2463978660 ETL_Fehler_Ueberspannung_HV 0;
BA_ "GenSigSendType" SG_ 2463978660 ETL_Fehler_Ueberspannung_HV 0;
BA_ "Fehlerwert" SG_ 2463978660 ETL_Fehler_Ueberspannung_NV 1;
BA_ "GenSigSwitchedByIgnition" SG_ 2463978660 ETL_Fehler_Ueberspannung_NV 0;
BA_ "GenSigSendType" SG_ 2463978660 ETL_Fehler_Ueberspannung_NV 0;
BA_ "Fehlerwert" SG_ 2463978660 ETL_Fehler_Uebertemperatur 1;
BA_ "GenSigSwitchedByIgnition" SG_ 2463978660 ETL_Fehler_Uebertemperatur 0;
BA_ "GenSigSendType" SG_ 2463978660 ETL_Fehler_Uebertemperatur 0;
BA_ "Fehlerwert" SG_ 2463978660 ETL_Fehler_Unterspannung_HV 1;
BA_ "GenSigSwitchedByIgnition" SG_ 2463978660 ETL_Fehler_Unterspannung_HV 0;
BA_ "GenSigSendType" SG_ 2463978660 ETL_Fehler_Unterspannung_HV 0;
BA_ "GenSigSwitchedByIgnition" SG_ 2463978660 ETL_Warnung_Uebertemperatur 0;
BA_ "GenSigSendType" SG_ 2463978660 ETL_Warnung_Uebertemperatur 0;
BA_ "Fehlerwert" SG_ 2463978660 ETL_IstDrehzahl 16383;
BA_ "GenSigSwitchedByIgnition" SG_ 2463978660 ETL_IstDrehzahl 0;
BA_ "GenSigSendType" SG_ 2463978660 ETL_IstDrehzahl 0;
BA_ "GenSigSwitchedByIgnition" SG_ 2463978660 ETL_Status_Spgfreiheit 0;
BA_ "GenSigSendType" SG_ 2463978660 ETL_Status_Spgfreiheit 0;
BA_ "Fehlerwert" SG_ 2463978660 ETL_IstStrom 255;
BA_ "GenSigSwitchedByIgnition" SG_ 2463978660 ETL_IstStrom 0;
BA_ "GenSigStartValue" SG_ 2463978660 ETL_IstStrom 127;
BA_ "GenSigSendType" SG_ 2463978660 ETL_IstStrom 0;
BA_ "Fehlerwert" SG_ 2463978695 ETL_Temperatur_Axiallager 255;
BA_ "GenSigSwitchedByIgnition" SG_ 2463978695 ETL_Temperatur_Axiallager 0;
BA_ "GenSigSendType" SG_ 2463978695 ETL_Temperatur_Axiallager 0;
BA_ "Fehlerwert" SG_ 2463978695 ETL_Temperatur_LE 255;
BA_ "GenSigSwitchedByIgnition" SG_ 2463978695 ETL_Temperatur_LE 0;
BA_ "GenSigStartValue" SG_ 2463978695 ETL_Temperatur_LE 254;
BA_ "GenSigSendType" SG_ 2463978695 ETL_Temperatur_LE 0;
BA_ "Fehlerwert" SG_ 2463978695 ETL_Temperatur_Stator 255;
BA_ "GenSigSwitchedByIgnition" SG_ 2463978695 ETL_Temperatur_Stator 0;
BA_ "GenSigStartValue" SG_ 2463978695 ETL_Temperatur_Stator 254;
BA_ "GenSigSendType" SG_ 2463978695 ETL_Temperatur_Stator 0;
BA_ "Fehlerwert" SG_ 2463978695 ETL_Derating 255;
BA_ "GenSigSwitchedByIgnition" SG_ 2463978695 ETL_Derating 0;
BA_ "GenSigSendType" SG_ 2463978695 ETL_Derating 0;
BA_ "GenSigSwitchedByIgnition" SG_ 2463978695 ETL_Error_NW_Timeout 0;
BA_ "GenSigSendType" SG_ 2463978695 ETL_Error_NW_Timeout 0;
BA_ "GenSigFuncType" SG_ 264 Fahrwerk_01_CRC 2;
BA_ "GenSigSendType" SG_ 264 Fahrwerk_01_CRC 0;
BA_ "GenSigFuncType" SG_ 264 Fahrwerk_01_BZ 1;
BA_ "GenSigSendType" SG_ 264 Fahrwerk_01_BZ 0;
BA_ "GenSigSendType" SG_ 264 FA_Hoehenwerte_kalibriert 0;
BA_ "GenSigSwitchedByIgnition" SG_ 264 EFP_Anf_Bremsenkuehlung 0;
BA_ "GenSigSendType" SG_ 264 EFP_Anf_Bremsenkuehlung 0;
BA_ "Fehlerwert" SG_ 264 FA_Hoehenwert_VL_00 255;
BA_ "GenSigStartValue" SG_ 264 FA_Hoehenwert_VL_00 254;
BA_ "GenSigSendType" SG_ 264 FA_Hoehenwert_VL_00 0;
BA_ "Fehlerwert" SG_ 264 FA_Hoehenwert_VR_00 255;
BA_ "GenSigStartValue" SG_ 264 FA_Hoehenwert_VR_00 254;
BA_ "GenSigSendType" SG_ 264 FA_Hoehenwert_VR_00 0;
BA_ "Fehlerwert" SG_ 264 FA_Hoehenwert_HL_00 255;
BA_ "GenSigStartValue" SG_ 264 FA_Hoehenwert_HL_00 254;
BA_ "GenSigSendType" SG_ 264 FA_Hoehenwert_HL_00 0;
BA_ "Fehlerwert" SG_ 264 FA_Hoehenwert_HR_00 255;
BA_ "GenSigStartValue" SG_ 264 FA_Hoehenwert_HR_00 254;
BA_ "GenSigSendType" SG_ 264 FA_Hoehenwert_HR_00 0;
BA_ "Fehlerwert" SG_ 264 FA_Fahrbahnunebenheit 255;
BA_ "GenSigSwitchedByIgnition" SG_ 264 FA_Fahrbahnunebenheit 0;
BA_ "GenSigStartValue" SG_ 264 FA_Fahrbahnunebenheit 254;
BA_ "GenSigSendType" SG_ 264 FA_Fahrbahnunebenheit 0;
BA_ "Fehlerwert" SG_ 222 FCU_IstLeistung 16383;
BA_ "GenSigSwitchedByIgnition" SG_ 222 FCU_IstLeistung 0;
BA_ "GenSigStartValue" SG_ 222 FCU_IstLeistung 16382;
BA_ "GenSigSendType" SG_ 222 FCU_IstLeistung 0;
BA_ "GenSigSwitchedByIgnition" SG_ 379 FCU_Warn_H2_Konzentrat_Motorraum 0;
BA_ "GenSigSendType" SG_ 379 FCU_Warn_H2_Konzentrat_Motorraum 0;
BA_ "GenSigSwitchedByIgnition" SG_ 379 FCU_nicht_verfuegbar 0;
BA_ "GenSigSendType" SG_ 379 FCU_nicht_verfuegbar 3;
BA_ "GenSigSwitchedByIgnition" SG_ 379 FCU_Startstopp_Anforderung 0;
BA_ "GenSigSendType" SG_ 379 FCU_Startstopp_Anforderung 3;
BA_ "Fehlerwert" SG_ 379 FCU_HV_Anf 3;
BA_ "GenSigSwitchedByIgnition" SG_ 379 FCU_HV_Anf 0;
BA_ "GenSigSendType" SG_ 379 FCU_HV_Anf 0;
BA_ "GenSigSwitchedByIgnition" SG_ 379 FCU_Klima_Eingr 0;
BA_ "GenSigSendType" SG_ 379 FCU_Klima_Eingr 3;
BA_ "GenSigSwitchedByIgnition" SG_ 379 FCU_IstModus 0;
BA_ "GenSigStartValue" SG_ 379 FCU_IstModus 31;
BA_ "GenSigSendType" SG_ 379 FCU_IstModus 3;
BA_ "GenSigSwitchedByIgnition" SG_ 379 FCU_Status_Spgfreiheit 0;
BA_ "GenSigSendType" SG_ 379 FCU_Status_Spgfreiheit 3;
BA_ "Fehlerwert" SG_ 379 FCU_Fehler_Leistungsreduzierung 1;
BA_ "GenSigSwitchedByIgnition" SG_ 379 FCU_Fehler_Leistungsreduzierung 0;
BA_ "GenSigSendType" SG_ 379 FCU_Fehler_Leistungsreduzierung 3;
BA_ "Fehlerwert" SG_ 379 FCU_Fehler_Abschaltanforderung 1;
BA_ "GenSigSwitchedByIgnition" SG_ 379 FCU_Fehler_Abschaltanforderung 0;
BA_ "GenSigSendType" SG_ 379 FCU_Fehler_Abschaltanforderung 3;
BA_ "Fehlerwert" SG_ 379 FCU_Fehler_Notabschaltung 1;
BA_ "GenSigSwitchedByIgnition" SG_ 379 FCU_Fehler_Notabschaltung 0;
BA_ "GenSigSendType" SG_ 379 FCU_Fehler_Notabschaltung 3;
BA_ "Fehlerwert" SG_ 379 FCU_Fehler_Entladung_defekt 1;
BA_ "GenSigSwitchedByIgnition" SG_ 379 FCU_Fehler_Entladung_defekt 0;
BA_ "GenSigStartValue" SG_ 379 FCU_Fehler_Entladung_defekt 3;
BA_ "GenSigSendType" SG_ 379 FCU_Fehler_Entladung_defekt 3;
BA_ "GenSigSwitchedByIgnition" SG_ 379 FCU_Fehler_Isofehler_I 0;
BA_ "GenSigStartValue" SG_ 379 FCU_Fehler_Isofehler_I 3;
BA_ "GenSigSendType" SG_ 379 FCU_Fehler_Isofehler_I 3;
BA_ "GenSigSwitchedByIgnition" SG_ 379 FCU_Fehler_Isofehler_II 0;
BA_ "GenSigStartValue" SG_ 379 FCU_Fehler_Isofehler_II 3;
BA_ "GenSigSendType" SG_ 379 FCU_Fehler_Isofehler_II 3;
BA_ "GenSigSwitchedByIgnition" SG_ 379 FCU_OBD_Lampe_Anf 0;
BA_ "GenSigSendType" SG_ 379 FCU_OBD_Lampe_Anf 0;
BA_ "GenSigSwitchedByIgnition" SG_ 379 FCU_Absperrventil_schliessen 0;
BA_ "GenSigSendType" SG_ 379 FCU_Absperrventil_schliessen 0;
BA_ "GenSigSwitchedByIgnition" SG_ 379 FCU_TK_Betankung_Anforderung 0;
BA_ "GenSigSendType" SG_ 379 FCU_TK_Betankung_Anforderung 0;
BA_ "GenSigSwitchedByIgnition" SG_ 379 FCU_MinAbs_Leistung 0;
BA_ "GenSigStartValue" SG_ 379 FCU_MinAbs_Leistung 1023;
BA_ "GenSigSendType" SG_ 379 FCU_MinAbs_Leistung 0;
BA_ "GenSigSwitchedByIgnition" SG_ 379 FCU_Ionenspuelung_aktiv 0;
BA_ "GenSigSendType" SG_ 379 FCU_Ionenspuelung_aktiv 3;
BA_ "Fehlerwert" SG_ 379 FCU_TK_Freigabe_Tankklappe 3;
BA_ "GenSigSwitchedByIgnition" SG_ 379 FCU_TK_Freigabe_Tankklappe 0;
BA_ "GenSigStartValue" SG_ 379 FCU_TK_Freigabe_Tankklappe 2;
BA_ "GenSigSendType" SG_ 379 FCU_TK_Freigabe_Tankklappe 0;
BA_ "Fehlerwert" SG_ 2463978657 FCU_Kuehlerluefter_1 127;
BA_ "GenSigSwitchedByIgnition" SG_ 2463978657 FCU_Kuehlerluefter_1 0;
BA_ "GenSigStartValue" SG_ 2463978657 FCU_Kuehlerluefter_1 126;
BA_ "GenSigSendType" SG_ 2463978657 FCU_Kuehlerluefter_1 0;
BA_ "GenSigSwitchedByIgnition" SG_ 2463978657 FCU_MinDyn_Leistung 0;
BA_ "GenSigStartValue" SG_ 2463978657 FCU_MinDyn_Leistung 4095;
BA_ "GenSigSendType" SG_ 2463978657 FCU_MinDyn_Leistung 0;
BA_ "GenSigSwitchedByIgnition" SG_ 2463978657 FCU_MaxKuehlmitteldruck_erreicht 0;
BA_ "GenSigSendType" SG_ 2463978657 FCU_MaxKuehlmitteldruck_erreicht 0;
BA_ "GenSigSwitchedByIgnition" SG_ 2463978657 FCU_MaxDyn_Leistung 0;
BA_ "GenSigSendType" SG_ 2463978657 FCU_MaxDyn_Leistung 0;
BA_ "Fehlerwert" SG_ 2463978657 FCU_Kuehlerluefter_2 127;
BA_ "GenSigSwitchedByIgnition" SG_ 2463978657 FCU_Kuehlerluefter_2 0;
BA_ "GenSigStartValue" SG_ 2463978657 FCU_Kuehlerluefter_2 126;
BA_ "GenSigSendType" SG_ 2463978657 FCU_Kuehlerluefter_2 0;
BA_ "Fehlerwert" SG_ 2463978657 FCU_Druck_Kuehlmittel_Stack_Einl 511;
BA_ "GenSigSwitchedByIgnition" SG_ 2463978657 FCU_Druck_Kuehlmittel_Stack_Einl 0;
BA_ "GenSigStartValue" SG_ 2463978657 FCU_Druck_Kuehlmittel_Stack_Einl 510;
BA_ "GenSigSendType" SG_ 2463978657 FCU_Druck_Kuehlmittel_Stack_Einl 0;
BA_ "Fehlerwert" SG_ 2589283642 FCU_Heizungspumpenansteuerung 15;
BA_ "GenSigSwitchedByIgnition" SG_ 2589283642 FCU_Heizungspumpenansteuerung 0;
BA_ "GenSigStartValue" SG_ 2589283642 FCU_Heizungspumpenansteuerung 14;
BA_ "GenSigSendType" SG_ 2589283642 FCU_Heizungspumpenansteuerung 0;
BA_ "Fehlerwert" SG_ 2589283642 FCU_Pred_Startzeit 511;
BA_ "GenSigSwitchedByIgnition" SG_ 2589283642 FCU_Pred_Startzeit 0;
BA_ "GenSigStartValue" SG_ 2589283642 FCU_Pred_Startzeit 510;
BA_ "GenSigSendType" SG_ 2589283642 FCU_Pred_Startzeit 0;
BA_ "GenSigSwitchedByIgnition" SG_ 2589283642 FCU_Nachlaufzeit_Kuehlerluefter 0;
BA_ "GenSigSendType" SG_ 2589283642 FCU_Nachlaufzeit_Kuehlerluefter 0;
BA_ "Fehlerwert" SG_ 2589283642 FCU_Hoeheninfo 255;
BA_ "GenSigSwitchedByIgnition" SG_ 2589283642 FCU_Hoeheninfo 0;
BA_ "GenSigSendType" SG_ 2589283642 FCU_Hoeheninfo 0;
BA_ "Fehlerwert" SG_ 2589283642 FCU_Temp_Kuehlmittel_Stack_Ausl 255;
BA_ "GenSigSwitchedByIgnition" SG_ 2589283642 FCU_Temp_Kuehlmittel_Stack_Ausl 0;
BA_ "GenSigStartValue" SG_ 2589283642 FCU_Temp_Kuehlmittel_Stack_Ausl 254;
BA_ "GenSigSendType" SG_ 2589283642 FCU_Temp_Kuehlmittel_Stack_Ausl 0;
BA_ "Fehlerwert" SG_ 2589283642 FCU_Temp_Kuehlmittel_Stack_Einl 255;
BA_ "GenSigSwitchedByIgnition" SG_ 2589283642 FCU_Temp_Kuehlmittel_Stack_Einl 0;
BA_ "GenSigStartValue" SG_ 2589283642 FCU_Temp_Kuehlmittel_Stack_Einl 254;
BA_ "GenSigSendType" SG_ 2589283642 FCU_Temp_Kuehlmittel_Stack_Einl 0;
BA_ "Fehlerwert" SG_ 2589283642 FCU_Temp_Kuehlmittel_KMP_Einl 255;
BA_ "GenSigSwitchedByIgnition" SG_ 2589283642 FCU_Temp_Kuehlmittel_KMP_Einl 0;
BA_ "GenSigStartValue" SG_ 2589283642 FCU_Temp_Kuehlmittel_KMP_Einl 254;
BA_ "GenSigSendType" SG_ 2589283642 FCU_Temp_Kuehlmittel_KMP_Einl 0;
BA_ "Fehlerwert" SG_ 2589283646 FCU_Istposition_Thermostatventil 255;
BA_ "GenSigSwitchedByIgnition" SG_ 2589283646 FCU_Istposition_Thermostatventil 0;
BA_ "GenSigSendType" SG_ 2589283646 FCU_Istposition_Thermostatventil 0;
BA_ "GenSigSwitchedByIgnition" SG_ 2463978770 FCU_TK_Wasserstoffmasse_Netto 0;
BA_ "GenSigSendType" SG_ 2463978770 FCU_TK_Wasserstoffmasse_Netto 0;
BA_ "Fehlerwert" SG_ 2463978770 FCU_TK_H2_Fuellstand 511;
BA_ "GenSigSwitchedByIgnition" SG_ 2463978770 FCU_TK_H2_Fuellstand 0;
BA_ "GenSigStartValue" SG_ 2463978770 FCU_TK_H2_Fuellstand 510;
BA_ "GenSigSendType" SG_ 2463978770 FCU_TK_H2_Fuellstand 0;
BA_ "Fehlerwert" SG_ 2463978770 FCU_TK_H2_Nachtanken_aktiv 3;
BA_ "GenSigSwitchedByIgnition" SG_ 2463978770 FCU_TK_H2_Nachtanken_aktiv 0;
BA_ "GenSigSendType" SG_ 2463978770 FCU_TK_H2_Nachtanken_aktiv 0;
BA_ "Fehlerwert" SG_ 2463978770 FCU_TK_Meldungen 7;
BA_ "GenSigSwitchedByIgnition" SG_ 2463978770 FCU_TK_Meldungen 0;
BA_ "GenSigSendType" SG_ 2463978770 FCU_TK_Meldungen 0;
BA_ "Fehlerwert" SG_ 2463978770 FCU_TK_Tankwarnungen 7;
BA_ "GenSigSwitchedByIgnition" SG_ 2463978770 FCU_TK_Tankwarnungen 0;
BA_ "GenSigSendType" SG_ 2463978770 FCU_TK_Tankwarnungen 0;
BA_ "GenSigSwitchedByIgnition" SG_ 2463978817 FCU_Betriebspunkt_Soll 0;
BA_ "GenSigSendType" SG_ 2463978817 FCU_Betriebspunkt_Soll 0;
BA_ "GenSigSwitchedByIgnition" SG_ 2463978817 FCU_Startleistungsbedarf 0;
BA_ "GenSigStartValue" SG_ 2463978817 FCU_Startleistungsbedarf 511;
BA_ "GenSigSendType" SG_ 2463978817 FCU_Startleistungsbedarf 0;
BA_ "GenSigSwitchedByIgnition" SG_ 2463978817 FCU_MaxAbs_Leistung 0;
BA_ "GenSigStartValue" SG_ 2463978817 FCU_MaxAbs_Leistung 16383;
BA_ "GenSigSendType" SG_ 2463978817 FCU_MaxAbs_Leistung 0;
BA_ "GenSigSwitchedByIgnition" SG_ 606 FCU_Energieaequivalent 0;
BA_ "GenSigStartValue" SG_ 606 FCU_Energieaequivalent 4095;
BA_ "GenSigSendType" SG_ 606 FCU_Energieaequivalent 0;
BA_ "GenSigSwitchedByIgnition" SG_ 606 FCU_Verbrauch_FC_Nebag 0;
BA_ "GenSigSendType" SG_ 606 FCU_Verbrauch_FC_Nebag 0;
BA_ "GenSigSwitchedByIgnition" SG_ 606 FCU_Verbrauch_FC_Nebag_Ueberlauf 0;
BA_ "GenSigSendType" SG_ 606 FCU_Verbrauch_FC_Nebag_Ueberlauf 0;
BA_ "GenSigSwitchedByIgnition" SG_ 606 FCU_Verbrauch_H2 0;
BA_ "GenSigSendType" SG_ 606 FCU_Verbrauch_H2 0;
BA_ "GenSigSwitchedByIgnition" SG_ 606 FCU_Verbrauch_H2_Ueberlauf 0;
BA_ "GenSigSendType" SG_ 606 FCU_Verbrauch_H2_Ueberlauf 0;
BA_ "GenSigSwitchedByIgnition" SG_ 606 FCU_Verbrauch_FC 0;
BA_ "GenSigSendType" SG_ 606 FCU_Verbrauch_FC 0;
BA_ "GenSigSwitchedByIgnition" SG_ 606 FCU_Verbrauch_FC_Ueberlauf 0;
BA_ "GenSigSendType" SG_ 606 FCU_Verbrauch_FC_Ueberlauf 0;
BA_ "Fehlerwert" SG_ 607 FCU_TK_Fuellstand 511;
BA_ "GenSigSwitchedByIgnition" SG_ 607 FCU_TK_Fuellstand 0;
BA_ "GenSigStartValue" SG_ 607 FCU_TK_Fuellstand 510;
BA_ "GenSigSendType" SG_ 607 FCU_TK_Fuellstand 0;
BA_ "Fehlerwert" SG_ 607 FCU_TK_Wasserstoffmasse_Tank 1023;
BA_ "GenSigSwitchedByIgnition" SG_ 607 FCU_TK_Wasserstoffmasse_Tank 0;
BA_ "GenSigStartValue" SG_ 607 FCU_TK_Wasserstoffmasse_Tank 1022;
BA_ "GenSigSendType" SG_ 607 FCU_TK_Wasserstoffmasse_Tank 0;
BA_ "GenSigSwitchedByIgnition" SG_ 607 FCU_Verb_FC_Nebag_Masaequi_Ueb 0;
BA_ "GenSigSendType" SG_ 607 FCU_Verb_FC_Nebag_Masaequi_Ueb 0;
BA_ "GenSigSwitchedByIgnition" SG_ 607 FCU_Verb_FC_Nebag_Masaequi 0;
BA_ "GenSigSendType" SG_ 607 FCU_Verb_FC_Nebag_Masaequi 0;
BA_ "GenSigSwitchedByIgnition" SG_ 607 FCU_Anzeigeverbrauch_H2 0;
BA_ "GenSigSendType" SG_ 607 FCU_Anzeigeverbrauch_H2 0;
BA_ "GenSigSwitchedByIgnition" SG_ 177 Getriebe_17_CRC 0;
BA_ "GenSigFuncType" SG_ 177 Getriebe_17_CRC 2;
BA_ "GenSigSendType" SG_ 177 Getriebe_17_CRC 0;
BA_ "GenSigSwitchedByIgnition" SG_ 177 Getriebe_17_BZ 0;
BA_ "GenSigFuncType" SG_ 177 Getriebe_17_BZ 1;
BA_ "GenSigSendType" SG_ 177 Getriebe_17_BZ 0;
BA_ "GenSigSwitchedByIgnition" SG_ 177 GE_Fahrprogramm 0;
BA_ "GenSigSendType" SG_ 177 GE_Fahrprogramm 0;
BA_ "GenSigSwitchedByIgnition" SG_ 177 GE_TippZustand 0;
BA_ "GenSigSendType" SG_ 177 GE_TippZustand 0;
BA_ "Fehlerwert" SG_ 177 GE_Freilauf_Status 7;
BA_ "GenSigSwitchedByIgnition" SG_ 177 GE_Freilauf_Status 0;
BA_ "GenSigSendType" SG_ 177 GE_Freilauf_Status 3;
BA_ "GenSigSendType" SG_ 177 GE_Grundeinstellung 0;
BA_ "GenSigSwitchedByIgnition" SG_ 177 GE_Anschleppstart_Freigabe 0;
BA_ "GenSigSendType" SG_ 177 GE_Anschleppstart_Freigabe 0;
BA_ "GenSigSendType" SG_ 177 GE_Strombedarf_erh 0;
BA_ "Fehlerwert" SG_ 177 GE_Uefkt_Praed 16383;
BA_ "GenSigSwitchedByIgnition" SG_ 177 GE_Uefkt_Praed 0;
BA_ "GenSigSendType" SG_ 177 GE_Uefkt_Praed 0;
BA_ "Fehlerwert" SG_ 177 GE_KomFehler_ESP 1;
BA_ "GenSigSwitchedByIgnition" SG_ 177 GE_KomFehler_ESP 0;
BA_ "GenSigSendType" SG_ 177 GE_KomFehler_ESP 0;
BA_ "GenSigSwitchedByIgnition" SG_ 177 GE_Rollrichtung_falsch 0;
BA_ "GenSigSendType" SG_ 177 GE_Rollrichtung_falsch 0;
BA_ "GenSigSwitchedByIgnition" SG_ 177 GE_Getriebestatus_02 0;
BA_ "GenSigSendType" SG_ 177 GE_Getriebestatus_02 0;
BA_ "Fehlerwert" SG_ 177 GE_Eingangsdrehz_Praed 16383;
BA_ "GenSigSwitchedByIgnition" SG_ 177 GE_Eingangsdrehz_Praed 0;
BA_ "GenSigStartValue" SG_ 177 GE_Eingangsdrehz_Praed 16382;
BA_ "GenSigSendType" SG_ 177 GE_Eingangsdrehz_Praed 0;
BA_ "GenSigSwitchedByIgnition" SG_ 310 HAL_01_CRC 0;
BA_ "GenSigFuncType" SG_ 310 HAL_01_CRC 2;
BA_ "GenSigSendType" SG_ 310 HAL_01_CRC 0;
BA_ "GenSigSwitchedByIgnition" SG_ 310 HAL_01_BZ 0;
BA_ "GenSigFuncType" SG_ 310 HAL_01_BZ 1;
BA_ "GenSigSendType" SG_ 310 HAL_01_BZ 0;
BA_ "GenSigSwitchedByIgnition" SG_ 310 HAL_Status 0;
BA_ "GenSigSendType" SG_ 310 HAL_Status 0;
BA_ "GenSigSwitchedByIgnition" SG_ 310 HAL_VZ_Radwinkel 0;
BA_ "GenSigSendType" SG_ 310 HAL_VZ_Radwinkel 0;
BA_ "GenSigSwitchedByIgnition" SG_ 310 HAL_QBit_Radwinkel 0;
BA_ "GenSigSendType" SG_ 310 HAL_QBit_Radwinkel 0;
BA_ "Fehlerwert" SG_ 310 HAL_Radwinkel 1023;
BA_ "GenSigSwitchedByIgnition" SG_ 310 HAL_Radwinkel 0;
BA_ "GenSigStartValue" SG_ 310 HAL_Radwinkel 1022;
BA_ "GenSigSendType" SG_ 310 HAL_Radwinkel 0;
BA_ "GenSigSwitchedByIgnition" SG_ 310 HAL_Warnungen 0;
BA_ "GenSigSendType" SG_ 310 HAL_Warnungen 0;
BA_ "GenSigSwitchedByIgnition" SG_ 310 HAL_Winkelbegrenzung 0;
BA_ "GenSigSendType" SG_ 310 HAL_Winkelbegrenzung 0;
BA_ "GenSigSwitchedByIgnition" SG_ 310 HAL_VZ_Fahrerwunschwinkel_Soll 0;
BA_ "GenSigSendType" SG_ 310 HAL_VZ_Fahrerwunschwinkel_Soll 0;
BA_ "Fehlerwert" SG_ 310 HAL_Fahrerwunschwinkel_Soll 1023;
BA_ "GenSigSwitchedByIgnition" SG_ 310 HAL_Fahrerwunschwinkel_Soll 0;
BA_ "GenSigStartValue" SG_ 310 HAL_Fahrerwunschwinkel_Soll 1022;
BA_ "GenSigSendType" SG_ 310 HAL_Fahrerwunschwinkel_Soll 0;
BA_ "Fehlerwert" SG_ 310 HAL_max_Gradient 127;
BA_ "GenSigSwitchedByIgnition" SG_ 310 HAL_max_Gradient 0;
BA_ "GenSigStartValue" SG_ 310 HAL_max_Gradient 126;
BA_ "GenSigSendType" SG_ 310 HAL_max_Gradient 0;
BA_ "GenSigSwitchedByIgnition" SG_ 310 HAL_EFP_FahrPr 0;
BA_ "GenSigSendType" SG_ 310 HAL_EFP_FahrPr 0;
BA_ "GenSigSwitchedByIgnition" SG_ 310 HAL_Charisma_Status 0;
BA_ "GenSigSendType" SG_ 310 HAL_Charisma_Status 0;
BA_ "GenSigSwitchedByIgnition" SG_ 310 HAL_Charisma_FahrPr 0;
BA_ "GenSigSendType" SG_ 310 HAL_Charisma_FahrPr 0;
BA_ "Fehlerwert" SG_ 1452 HVEM_IstStrom_HVVerbraucher 4095;
BA_ "GenSigSwitchedByIgnition" SG_ 1452 HVEM_IstStrom_HVVerbraucher 0;
BA_ "GenSigStartValue" SG_ 1452 HVEM_IstStrom_HVVerbraucher 4094;
BA_ "GenSigSendType" SG_ 1452 HVEM_IstStrom_HVVerbraucher 0;
BA_ "Fehlerwert" SG_ 1452 HVEM_Energie_Klima_Vorgabe_HighR 7;
BA_ "GenSigSwitchedByIgnition" SG_ 1452 HVEM_Energie_Klima_Vorgabe_HighR 0;
BA_ "GenSigStartValue" SG_ 1452 HVEM_Energie_Klima_Vorgabe_HighR 6;
BA_ "GenSigSendType" SG_ 1452 HVEM_Energie_Klima_Vorgabe_HighR 0;
BA_ "Fehlerwert" SG_ 1452 HVEM_IstLeistungNA 511;
BA_ "GenSigSwitchedByIgnition" SG_ 1452 HVEM_IstLeistungNA 0;
BA_ "GenSigStartValue" SG_ 1452 HVEM_IstLeistungNA 510;
BA_ "GenSigSendType" SG_ 1452 HVEM_IstLeistungNA 0;
BA_ "Fehlerwert" SG_ 1452 HVEM_Leistung_Klima_Vorgabe 255;
BA_ "GenSigSwitchedByIgnition" SG_ 1452 HVEM_Leistung_Klima_Vorgabe 0;
BA_ "GenSigStartValue" SG_ 1452 HVEM_Leistung_Klima_Vorgabe 254;
BA_ "GenSigSendType" SG_ 1452 HVEM_Leistung_Klima_Vorgabe 0;
BA_ "Fehlerwert" SG_ 1452 HVEM_Nutzbare_Energie 2047;
BA_ "GenSigSwitchedByIgnition" SG_ 1452 HVEM_Nutzbare_Energie 0;
BA_ "GenSigStartValue" SG_ 1452 HVEM_Nutzbare_Energie 2046;
BA_ "GenSigSendType" SG_ 1452 HVEM_Nutzbare_Energie 0;
BA_ "Fehlerwert" SG_ 1452 HVEM_Energie_Klima_Vorgabe 255;
BA_ "GenSigSwitchedByIgnition" SG_ 1452 HVEM_Energie_Klima_Vorgabe 0;
BA_ "GenSigStartValue" SG_ 1452 HVEM_Energie_Klima_Vorgabe 254;
BA_ "GenSigSendType" SG_ 1452 HVEM_Energie_Klima_Vorgabe 0;
BA_ "GenSigSwitchedByIgnition" SG_ 1452 HVEM_MO_MaxLeistungIgnoriert 0;
BA_ "GenSigSendType" SG_ 1452 HVEM_MO_MaxLeistungIgnoriert 0;
BA_ "Fehlerwert" SG_ 1362 HVEM_NVNachladen_Energie 255;
BA_ "GenSigSwitchedByIgnition" SG_ 1362 HVEM_NVNachladen_Energie 0;
BA_ "GenSigStartValue" SG_ 1362 HVEM_NVNachladen_Energie 254;
BA_ "GenSigSendType" SG_ 1362 HVEM_NVNachladen_Energie 0;
BA_ "Fehlerwert" SG_ 1362 HVEM_Max_VK_Betriebsdauer 63;
BA_ "GenSigSwitchedByIgnition" SG_ 1362 HVEM_Max_VK_Betriebsdauer 0;
BA_ "GenSigStartValue" SG_ 1362 HVEM_Max_VK_Betriebsdauer 62;
BA_ "GenSigSendType" SG_ 1362 HVEM_Max_VK_Betriebsdauer 0;
BA_ "GenSigSwitchedByIgnition" SG_ 1362 HVEM_Nachladen_Anf 0;
BA_ "GenSigSendType" SG_ 1362 HVEM_Nachladen_Anf 0;
BA_ "Fehlerwert" SG_ 1362 HVEM_SollStrom_HV 2047;
BA_ "GenSigSwitchedByIgnition" SG_ 1362 HVEM_SollStrom_HV 0;
BA_ "GenSigStartValue" SG_ 1362 HVEM_SollStrom_HV 2046;
BA_ "GenSigSendType" SG_ 1362 HVEM_SollStrom_HV 0;
BA_ "Fehlerwert" SG_ 1362 HVEM_MaxSpannung_HV 1023;
BA_ "GenSigStartValue" SG_ 1362 HVEM_MaxSpannung_HV 1022;
BA_ "GenSigSendType" SG_ 1362 HVEM_MaxSpannung_HV 0;
BA_ "GenSigSwitchedByIgnition" SG_ 1362 HVEM_Abschaltstatus 0;
BA_ "GenSigStartValue" SG_ 1362 HVEM_Abschaltstatus 7;
BA_ "GenSigSendType" SG_ 1362 HVEM_Abschaltstatus 0;
BA_ "GenSigSwitchedByIgnition" SG_ 1362 HVEM_DCDC_Freigabe 0;
BA_ "GenSigSendType" SG_ 1362 HVEM_DCDC_Freigabe 0;
BA_ "Fehlerwert" SG_ 1362 HVEM_FreigabeKlimatisierung 3;
BA_ "GenSigSwitchedByIgnition" SG_ 1362 HVEM_FreigabeKlimatisierung 0;
BA_ "GenSigStartValue" SG_ 1362 HVEM_FreigabeKlimatisierung 2;
BA_ "GenSigSendType" SG_ 1362 HVEM_FreigabeKlimatisierung 0;
BA_ "GenSigSwitchedByIgnition" SG_ 1283 HVK_01_CRC 0;
BA_ "GenSigFuncType" SG_ 1283 HVK_01_CRC 2;
BA_ "GenSigSendType" SG_ 1283 HVK_01_CRC 0;
BA_ "GenSigSwitchedByIgnition" SG_ 1283 HVK_01_BZ 0;
BA_ "GenSigFuncType" SG_ 1283 HVK_01_BZ 1;
BA_ "GenSigSendType" SG_ 1283 HVK_01_BZ 0;
BA_ "GenSigSwitchedByIgnition" SG_ 1283 HVK_Istmodus_Anf 0;
BA_ "GenSigSendType" SG_ 1283 HVK_Istmodus_Anf 3;
BA_ "GenSigSwitchedByIgnition" SG_ 1283 HVK_TN1_Sollmodus 0;
BA_ "GenSigStartValue" SG_ 1283 HVK_TN1_Sollmodus 3;
BA_ "GenSigSendType" SG_ 1283 HVK_TN1_Sollmodus 3;
BA_ "GenSigSwitchedByIgnition" SG_ 1283 HVK_MO_EmSollzustand 0;
BA_ "GenSigStartValue" SG_ 1283 HVK_MO_EmSollzustand 255;
BA_ "GenSigSendType" SG_ 1283 HVK_MO_EmSollzustand 3;
BA_ "GenSigSwitchedByIgnition" SG_ 1283 HVK_BMS_Sollmodus 0;
BA_ "GenSigStartValue" SG_ 1283 HVK_BMS_Sollmodus 7;
BA_ "GenSigSendType" SG_ 1283 HVK_BMS_Sollmodus 3;
BA_ "GenSigSwitchedByIgnition" SG_ 1283 HVK_DCDC_Sollmodus 0;
BA_ "GenSigStartValue" SG_ 1283 HVK_DCDC_Sollmodus 7;
BA_ "GenSigSendType" SG_ 1283 HVK_DCDC_Sollmodus 3;
BA_ "GenSigSwitchedByIgnition" SG_ 1283 HVK_EKK_Sollmodus 0;
BA_ "GenSigStartValue" SG_ 1283 HVK_EKK_Sollmodus 7;
BA_ "GenSigSendType" SG_ 1283 HVK_EKK_Sollmodus 3;
BA_ "GenSigSwitchedByIgnition" SG_ 1283 HVK_HVPTC_Sollmodus 0;
BA_ "GenSigStartValue" SG_ 1283 HVK_HVPTC_Sollmodus 7;
BA_ "GenSigSendType" SG_ 1283 HVK_HVPTC_Sollmodus 3;
BA_ "GenSigSwitchedByIgnition" SG_ 1283 HVK_HVLM_Sollmodus 0;
BA_ "GenSigStartValue" SG_ 1283 HVK_HVLM_Sollmodus 7;
BA_ "GenSigSendType" SG_ 1283 HVK_HVLM_Sollmodus 3;
BA_ "GenSigSwitchedByIgnition" SG_ 1283 HVK_HV_Netz_Warnungen 0;
BA_ "GenSigSendType" SG_ 1283 HVK_HV_Netz_Warnungen 3;
BA_ "GenSigSwitchedByIgnition" SG_ 1283 HV_Bordnetz_aktiv 0;
BA_ "GenSigSendType" SG_ 1283 HV_Bordnetz_aktiv 3;
BA_ "Fehlerwert" SG_ 1283 HV_Bordnetz_Fehler 1;
BA_ "GenSigSwitchedByIgnition" SG_ 1283 HV_Bordnetz_Fehler 0;
BA_ "GenSigSendType" SG_ 1283 HV_Bordnetz_Fehler 3;
BA_ "Fehlerwert" SG_ 1283 HVK_Gesamtst_Spgfreiheit 3;
BA_ "GenSigSwitchedByIgnition" SG_ 1283 HVK_Gesamtst_Spgfreiheit 0;
BA_ "GenSigSendType" SG_ 1283 HVK_Gesamtst_Spgfreiheit 0;
BA_ "GenSigSwitchedByIgnition" SG_ 1283 HVK_AktiveEntladung_Anf 0;
BA_ "GenSigSendType" SG_ 1283 HVK_AktiveEntladung_Anf 3;
BA_ "GenSigSwitchedByIgnition" SG_ 1283 HVK_Iso_Messung_Start 0;
BA_ "GenSigSendType" SG_ 1283 HVK_Iso_Messung_Start 3;
BA_ "GenSigSwitchedByIgnition" SG_ 1283 HVK_DCDC_EKK_Sollmodus 0;
BA_ "GenSigStartValue" SG_ 1283 HVK_DCDC_EKK_Sollmodus 3;
BA_ "GenSigSendType" SG_ 1283 HVK_DCDC_EKK_Sollmodus 0;
BA_ "Fehlerwert" SG_ 1381 HVLM_HV_Abstellzeit 255;
BA_ "GenSigStartValue" SG_ 1381 HVLM_HV_Abstellzeit 254;
BA_ "GenSigSendType" SG_ 1381 HVLM_HV_Abstellzeit 0;
BA_ "GenSigSwitchedByIgnition" SG_ 1381 HVLM_Ladesystemhinweise 0;
BA_ "GenSigSendType" SG_ 1381 HVLM_Ladesystemhinweise 0;
BA_ "GenSigSwitchedByIgnition" SG_ 1381 HVLM_Schluessel_Anfrage 0;
BA_ "GenSigSendType" SG_ 1381 HVLM_Schluessel_Anfrage 3;
BA_ "Fehlerwert" SG_ 1381 HVLM_Zustand_LED 15;
BA_ "GenSigSwitchedByIgnition" SG_ 1381 HVLM_Zustand_LED 0;
BA_ "GenSigStartValue" SG_ 1381 HVLM_Zustand_LED 14;
BA_ "GenSigSendType" SG_ 1381 HVLM_Zustand_LED 3;
BA_ "Fehlerwert" SG_ 1381 HVLM_MaxStrom_Netz 127;
BA_ "GenSigStartValue" SG_ 1381 HVLM_MaxStrom_Netz 126;
BA_ "GenSigSendType" SG_ 1381 HVLM_MaxStrom_Netz 3;
BA_ "GenSigSendType" SG_ 1381 HVLM_LG_Sollmodus 3;
BA_ "Fehlerwert" SG_ 1381 HVLM_FreigabeTankdeckel 3;
BA_ "GenSigStartValue" SG_ 1381 HVLM_FreigabeTankdeckel 2;
BA_ "GenSigSendType" SG_ 1381 HVLM_FreigabeTankdeckel 3;
BA_ "GenSigStartValue" SG_ 1381 HVLM_Stecker_Verriegeln 2;
BA_ "GenSigSendType" SG_ 1381 HVLM_Stecker_Verriegeln 3;
BA_ "GenSigSwitchedByIgnition" SG_ 1381 HVLM_Start_Spannungsmessung_DCLS 0;
BA_ "GenSigSendType" SG_ 1381 HVLM_Start_Spannungsmessung_DCLS 3;
BA_ "GenSigSwitchedByIgnition" SG_ 1381 PnC_Trigger_OBC_cGW 0;
BA_ "GenSigSendType" SG_ 1381 PnC_Trigger_OBC_cGW 3;
BA_ "Fehlerwert" SG_ 1381 HVLM_FreigabeKlimatisierung 3;
BA_ "GenSigSwitchedByIgnition" SG_ 1381 HVLM_FreigabeKlimatisierung 0;
BA_ "GenSigStartValue" SG_ 1381 HVLM_FreigabeKlimatisierung 2;
BA_ "GenSigSendType" SG_ 1381 HVLM_FreigabeKlimatisierung 0;
BA_ "GenSigSwitchedByIgnition" SG_ 1381 HVLM_Ladetexte 0;
BA_ "GenSigSendType" SG_ 1381 HVLM_Ladetexte 3;
BA_ "GenSigSwitchedByIgnition" SG_ 1381 HVLM_IsoMessung_Anf 0;
BA_ "GenSigSendType" SG_ 1381 HVLM_IsoMessung_Anf 3;
BA_ "Fehlerwert" SG_ 1381 HVLM_IstSpannung_HV 1023;
BA_ "GenSigSwitchedByIgnition" SG_ 1381 HVLM_IstSpannung_HV 0;
BA_ "GenSigStartValue" SG_ 1381 HVLM_IstSpannung_HV 1022;
BA_ "GenSigSendType" SG_ 1381 HVLM_IstSpannung_HV 0;
BA_ "GenSigSwitchedByIgnition" SG_ 1340 HVLM_04_CRC 0;
BA_ "GenSigFuncType" SG_ 1340 HVLM_04_CRC 2;
BA_ "GenSigSendType" SG_ 1340 HVLM_04_CRC 0;
BA_ "GenSigSwitchedByIgnition" SG_ 1340 HVLM_04_BZ 0;
BA_ "GenSigFuncType" SG_ 1340 HVLM_04_BZ 1;
BA_ "GenSigSendType" SG_ 1340 HVLM_04_BZ 0;
BA_ "Fehlerwert" SG_ 1340 HVLM_STH_Betriebsmodus 7;
BA_ "GenSigSwitchedByIgnition" SG_ 1340 HVLM_STH_Betriebsmodus 0;
BA_ "GenSigStartValue" SG_ 1340 HVLM_STH_Betriebsmodus 6;
BA_ "GenSigSendType" SG_ 1340 HVLM_STH_Betriebsmodus 0;
BA_ "GenSigSwitchedByIgnition" SG_ 1340 HVLM_Standklima_Timer_Status 0;
BA_ "GenSigSendType" SG_ 1340 HVLM_Standklima_Timer_Status 0;
BA_ "Fehlerwert" SG_ 1340 HVLM_HVEM_MaxLeistung 511;
BA_ "GenSigSwitchedByIgnition" SG_ 1340 HVLM_HVEM_MaxLeistung 0;
BA_ "GenSigStartValue" SG_ 1340 HVLM_HVEM_MaxLeistung 510;
BA_ "GenSigSendType" SG_ 1340 HVLM_HVEM_MaxLeistung 0;
BA_ "GenSigSwitchedByIgnition" SG_ 1340 HVLM_Status_Netz 0;
BA_ "GenSigSendType" SG_ 1340 HVLM_Status_Netz 0;
BA_ "GenSigSwitchedByIgnition" SG_ 1340 HVLM_Anf_Ladescreen 0;
BA_ "GenSigSendType" SG_ 1340 HVLM_Anf_Ladescreen 0;
BA_ "GenSigSwitchedByIgnition" SG_ 1340 HVLM_Ladeart 0;
BA_ "GenSigSendType" SG_ 1340 HVLM_Ladeart 0;
BA_ "Fehlerwert" SG_ 1340 HVLM_VK_STH_Einsatz 7;
BA_ "GenSigSwitchedByIgnition" SG_ 1340 HVLM_VK_STH_Einsatz 0;
BA_ "GenSigStartValue" SG_ 1340 HVLM_VK_STH_Einsatz 6;
BA_ "GenSigSendType" SG_ 1340 HVLM_VK_STH_Einsatz 0;
BA_ "Fehlerwert" SG_ 1340 HVLM_VK_Modus 3;
BA_ "GenSigSwitchedByIgnition" SG_ 1340 HVLM_VK_Modus 0;
BA_ "GenSigSendType" SG_ 1340 HVLM_VK_Modus 0;
BA_ "Fehlerwert" SG_ 1340 HVLM_IstModus_02 3;
BA_ "GenSigSwitchedByIgnition" SG_ 1340 HVLM_IstModus_02 0;
BA_ "GenSigStartValue" SG_ 1340 HVLM_IstModus_02 2;
BA_ "GenSigSendType" SG_ 1340 HVLM_IstModus_02 0;
BA_ "GenSigSwitchedByIgnition" SG_ 1340 HVLM_HV_Anf 0;
BA_ "GenSigSendType" SG_ 1340 HVLM_HV_Anf 0;
BA_ "GenSigSwitchedByIgnition" SG_ 1340 HVLM_Fehlerstatus 0;
BA_ "GenSigStartValue" SG_ 1340 HVLM_Fehlerstatus 7;
BA_ "GenSigSendType" SG_ 1340 HVLM_Fehlerstatus 0;
BA_ "GenSigSwitchedByIgnition" SG_ 1340 HVLM_Anforderung_HMS 0;
BA_ "GenSigSendType" SG_ 1340 HVLM_Anforderung_HMS 0;
BA_ "Fehlerwert" SG_ 1340 HVLM_Parken_beibehalten_HMS 3;
BA_ "GenSigSwitchedByIgnition" SG_ 1340 HVLM_Parken_beibehalten_HMS 0;
BA_ "GenSigStartValue" SG_ 1340 HVLM_Parken_beibehalten_HMS 2;
BA_ "GenSigSendType" SG_ 1340 HVLM_Parken_beibehalten_HMS 0;
BA_ "Fehlerwert" SG_ 1340 HVLM_AWC_Sollmodus 7;
BA_ "GenSigSwitchedByIgnition" SG_ 1340 HVLM_AWC_Sollmodus 0;
BA_ "GenSigSendType" SG_ 1340 HVLM_AWC_Sollmodus 0;
BA_ "GenSigSwitchedByIgnition" SG_ 1340 HVLM_Stecker_Status 0;
BA_ "GenSigSendType" SG_ 1340 HVLM_Stecker_Status 0;
BA_ "Fehlerwert" SG_ 1340 HVLM_LadeAnforderung 7;
BA_ "GenSigSwitchedByIgnition" SG_ 1340 HVLM_LadeAnforderung 0;
BA_ "GenSigStartValue" SG_ 1340 HVLM_LadeAnforderung 6;
BA_ "GenSigSendType" SG_ 1340 HVLM_LadeAnforderung 0;
BA_ "Fehlerwert" SG_ 1340 HVLM_MaxBatLadestromHV 255;
BA_ "GenSigSwitchedByIgnition" SG_ 1340 HVLM_MaxBatLadestromHV 0;
BA_ "GenSigStartValue" SG_ 1340 HVLM_MaxBatLadestromHV 254;
BA_ "GenSigSendType" SG_ 1340 HVLM_MaxBatLadestromHV 0;
BA_ "Fehlerwert" SG_ 1160 HVLM_MaxLadeLeistung 1023;
BA_ "GenSigSwitchedByIgnition" SG_ 1160 HVLM_MaxLadeLeistung 0;
BA_ "GenSigStartValue" SG_ 1160 HVLM_MaxLadeLeistung 1022;
BA_ "GenSigSendType" SG_ 1160 HVLM_MaxLadeLeistung 3;
BA_ "Fehlerwert" SG_ 1160 HVLM_MaxSpannung_DCLS 1023;
BA_ "GenSigSwitchedByIgnition" SG_ 1160 HVLM_MaxSpannung_DCLS 0;
BA_ "GenSigStartValue" SG_ 1160 HVLM_MaxSpannung_DCLS 1022;
BA_ "GenSigSendType" SG_ 1160 HVLM_MaxSpannung_DCLS 3;
BA_ "Fehlerwert" SG_ 1160 HVLM_IstStrom_DCLS 511;
BA_ "GenSigSwitchedByIgnition" SG_ 1160 HVLM_IstStrom_DCLS 0;
BA_ "GenSigStartValue" SG_ 1160 HVLM_IstStrom_DCLS 510;
BA_ "GenSigSendType" SG_ 1160 HVLM_IstStrom_DCLS 0;
BA_ "Fehlerwert" SG_ 1160 HVLM_MaxStrom_DCLS 511;
BA_ "GenSigSwitchedByIgnition" SG_ 1160 HVLM_MaxStrom_DCLS 0;
BA_ "GenSigStartValue" SG_ 1160 HVLM_MaxStrom_DCLS 510;
BA_ "GenSigSendType" SG_ 1160 HVLM_MaxStrom_DCLS 3;
BA_ "Fehlerwert" SG_ 1160 HVLM_MinSpannung_DCLS 511;
BA_ "GenSigSwitchedByIgnition" SG_ 1160 HVLM_MinSpannung_DCLS 0;
BA_ "GenSigStartValue" SG_ 1160 HVLM_MinSpannung_DCLS 510;
BA_ "GenSigSendType" SG_ 1160 HVLM_MinSpannung_DCLS 3;
BA_ "Fehlerwert" SG_ 1160 HVLM_MinStrom_DCLS 31;
BA_ "GenSigSwitchedByIgnition" SG_ 1160 HVLM_MinStrom_DCLS 0;
BA_ "GenSigStartValue" SG_ 1160 HVLM_MinStrom_DCLS 30;
BA_ "GenSigSendType" SG_ 1160 HVLM_MinStrom_DCLS 3;
BA_ "GenSigSwitchedByIgnition" SG_ 2589283485 HVLM_Funktion_Dauer_BattKond 0;
BA_ "GenSigSendType" SG_ 2589283485 HVLM_Funktion_Dauer_BattKond 0;
BA_ "Fehlerwert" SG_ 2589283485 HVLM_BattKond_Anf 7;
BA_ "GenSigSwitchedByIgnition" SG_ 2589283485 HVLM_BattKond_Anf 0;
BA_ "GenSigStartValue" SG_ 2589283485 HVLM_BattKond_Anf 6;
BA_ "GenSigSendType" SG_ 2589283485 HVLM_BattKond_Anf 3;
BA_ "Fehlerwert" SG_ 2589283485 HVLM_Dauer_Klima_02 63;
BA_ "GenSigSwitchedByIgnition" SG_ 2589283485 HVLM_Dauer_Klima_02 0;
BA_ "GenSigStartValue" SG_ 2589283485 HVLM_Dauer_Klima_02 62;
BA_ "GenSigSendType" SG_ 2589283485 HVLM_Dauer_Klima_02 3;
BA_ "Fehlerwert" SG_ 2589283605 HVLM_AWC_Sollstrom 511;
BA_ "GenSigSwitchedByIgnition" SG_ 2589283605 HVLM_AWC_Sollstrom 0;
BA_ "GenSigStartValue" SG_ 2589283605 HVLM_AWC_Sollstrom 510;
BA_ "GenSigSendType" SG_ 2589283605 HVLM_AWC_Sollstrom 0;
BA_REL_ "GenSigTimeoutTime" BU_SG_REL_ TME SG_ 2527679649 EM3_Temperatur_ElMotor 3200;
BA_REL_ "GenSigTimeoutTime" BU_SG_REL_ TME SG_ 2527679649 EM3_Temperatur_PWR 3200;
BA_REL_ "GenSigTimeoutTime" BU_SG_REL_ TME SG_ 2527679649 EM3_Temperatur_Rotor 3200;
BA_REL_ "GenSigTimeoutTime" BU_SG_REL_ TME SG_ 2527679649 EM3_Verlustleistung_02 3200;
BA_REL_ "GenSigTimeoutTime" BU_SG_REL_ TME SG_ 2463978616 EM3_Istmodus2 4800;
BA_REL_ "GenSigTimeoutTime" BU_SG_REL_ TME SG_ 2463978616 EM3_EM_SollVolumenstrom 4800;
BA_REL_ "GenSigTimeoutTime" BU_SG_REL_ AWC SG_ 278 ESP_QBit_Wegimpuls_VL 1000;
BA_REL_ "GenSigTimeoutTime" BU_SG_REL_ AWC SG_ 278 ESP_QBit_Wegimpuls_VR 1000;
BA_REL_ "GenSigTimeoutTime" BU_SG_REL_ AWC SG_ 278 ESP_QBit_Wegimpuls_HL 1000;
BA_REL_ "GenSigTimeoutTime" BU_SG_REL_ AWC SG_ 278 ESP_QBit_Wegimpuls_HR 1000;
BA_REL_ "GenSigTimeoutTime" BU_SG_REL_ AWC SG_ 278 ESP_Wegimpuls_VL 1000;
BA_REL_ "GenSigTimeoutTime" BU_SG_REL_ AWC SG_ 278 ESP_Wegimpuls_VR 1000;
BA_REL_ "GenSigTimeoutTime" BU_SG_REL_ AWC SG_ 278 ESP_Wegimpuls_HL 1000;
BA_REL_ "GenSigTimeoutTime" BU_SG_REL_ AWC SG_ 278 ESP_Wegimpuls_HR 1000;
BA_REL_ "GenSigTimeoutTime" BU_SG_REL_ AWC SG_ 278 ESP_VL_Fahrtrichtung 1000;
BA_REL_ "GenSigTimeoutTime" BU_SG_REL_ AWC SG_ 278 ESP_VR_Fahrtrichtung 1000;
BA_REL_ "GenSigTimeoutTime" BU_SG_REL_ AWC SG_ 278 ESP_HL_Fahrtrichtung 1000;
BA_REL_ "GenSigTimeoutTime" BU_SG_REL_ AWC SG_ 278 ESP_HR_Fahrtrichtung 1000;
BA_REL_ "GenSigTimeoutTime" BU_SG_REL_ FCU_MLBevo_FCEV SG_ 418 HMS_Systemstatus 2000;
BA_REL_ "GenSigTimeoutTime" BU_SG_REL_ Ladegeraet_Konzern SG_ 418 HMS_Systemstatus 2000;
BA_REL_ "GenSigTimeoutTime" BU_SG_REL_ Ladegeraet_Konzern SG_ 418 HMS_aktives_System 2000;
BA_REL_ "GenSigTimeoutTime" BU_SG_REL_ Ladegeraet_Konzern SG_ 418 HMS_Konsistenz_HVLM 2000;
BA_REL_ "GenSigTimeoutTime" BU_SG_REL_ FCU_MLBevo_FCEV SG_ 418 HMS_Fehlerstatus 2000;
BA_REL_ "GenSigTimeoutTime" BU_SG_REL_ Ladegeraet_Konzern SG_ 418 HMS_Fehlerstatus 2000;
BA_REL_ "GenSigTimeoutTime" BU_SG_REL_ AWC SG_ 1629 BR_QBit_Reifenumfang 5000;
BA_REL_ "GenSigTimeoutTime" BU_SG_REL_ AWC SG_ 1629 BR_Reifenumfang 5000;
BA_REL_ "GenSigTimeoutTime" BU_SG_REL_ TME SG_ 2463978667 ESC_Anf_Mindestreku 5000;
BA_REL_ "GenSigTimeoutTime" BU_SG_REL_ TME SG_ 2527679662 ESC_Anf_Luefternachlauf 1600;
BA_REL_ "GenSigTimeoutTime" BU_SG_REL_ Ladegeraet_Konzern SG_ 2527679662 ESC_Anf_LadeVorhalt 1600;
BA_REL_ "GenSigTimeoutTime" BU_SG_REL_ TME SG_ 2527679662 ESC_Anf_Bremsenkuehlung 1600;
BA_REL_ "GenSigTimeoutTime" BU_SG_REL_ Gateway SG_ 2463978660 ETL_IstSpannung 1000;
BA_REL_ "GenSigTimeoutTime" BU_SG_REL_ Gateway SG_ 2463978660 ETL_Status_Spgfreiheit 1000;
BA_REL_ "GenSigTimeoutTime" BU_SG_REL_ TME SG_ 2463978695 ETL_Temperatur_Axiallager 1000;
BA_REL_ "GenSigTimeoutTime" BU_SG_REL_ TME SG_ 2463978695 ETL_Temperatur_LE 1000;
BA_REL_ "GenSigTimeoutTime" BU_SG_REL_ TME SG_ 2463978695 ETL_Temperatur_Stator 1000;
BA_REL_ "GenSigTimeoutTime" BU_SG_REL_ AWC SG_ 264 FA_Hoehenwerte_kalibriert 2000;
BA_REL_ "GenSigTimeoutTime" BU_SG_REL_ TME SG_ 264 EFP_Anf_Bremsenkuehlung 2000;
BA_REL_ "GenSigTimeoutTime" BU_SG_REL_ AWC SG_ 264 FA_Hoehenwert_VL_00 2000;
BA_REL_ "GenSigTimeoutTime" BU_SG_REL_ AWC SG_ 264 FA_Hoehenwert_VR_00 2000;
BA_REL_ "GenSigTimeoutTime" BU_SG_REL_ AWC SG_ 264 FA_Hoehenwert_HL_00 2000;
BA_REL_ "GenSigTimeoutTime" BU_SG_REL_ AWC SG_ 264 FA_Hoehenwert_HR_00 2000;
BA_REL_ "GenSigTimeoutTime" BU_SG_REL_ TME SG_ 379 FCU_Warn_H2_Konzentrat_Motorraum 1000;
BA_REL_ "GenSigTimeoutTime" BU_SG_REL_ Gateway SG_ 379 FCU_HV_Anf 1000;
BA_REL_ "GenSigTimeoutTime" BU_SG_REL_ TME SG_ 379 FCU_Klima_Eingr 1000;
BA_REL_ "GenSigTimeoutTime" BU_SG_REL_ Gateway SG_ 379 FCU_Status_Spgfreiheit 1000;
BA_REL_ "GenSigTimeoutTime" BU_SG_REL_ Gateway SG_ 379 FCU_Fehler_Entladung_defekt 1000;
BA_REL_ "GenSigTimeoutTime" BU_SG_REL_ Gateway SG_ 379 FCU_Fehler_Isofehler_I 1000;
BA_REL_ "GenSigTimeoutTime" BU_SG_REL_ Gateway SG_ 379 FCU_Fehler_Isofehler_II 1000;
BA_REL_ "GenSigTimeoutTime" BU_SG_REL_ TME SG_ 379 FCU_Absperrventil_schliessen 1000;
BA_REL_ "GenSigTimeoutTime" BU_SG_REL_ Ladegeraet_Konzern SG_ 379 FCU_TK_Betankung_Anforderung 1000;
BA_REL_ "GenSigTimeoutTime" BU_SG_REL_ TME SG_ 379 FCU_Ionenspuelung_aktiv 1000;
BA_REL_ "GenSigTimeoutTime" BU_SG_REL_ Ladegeraet_Konzern SG_ 379 FCU_TK_Freigabe_Tankklappe 1000;
BA_REL_ "GenSigTimeoutTime" BU_SG_REL_ TME SG_ 2463978657 FCU_Kuehlerluefter_1 1000;
BA_REL_ "GenSigTimeoutTime" BU_SG_REL_ TME SG_ 2463978657 FCU_MaxKuehlmitteldruck_erreicht 1000;
BA_REL_ "GenSigTimeoutTime" BU_SG_REL_ TME SG_ 2463978657 FCU_Kuehlerluefter_2 1000;
BA_REL_ "GenSigTimeoutTime" BU_SG_REL_ TME SG_ 2463978657 FCU_Druck_Kuehlmittel_Stack_Einl 1000;
BA_REL_ "GenSigTimeoutTime" BU_SG_REL_ TME SG_ 2589283642 FCU_Heizungspumpenansteuerung 5000;
BA_REL_ "GenSigTimeoutTime" BU_SG_REL_ TME SG_ 2589283642 FCU_Nachlaufzeit_Kuehlerluefter 5000;
BA_REL_ "GenSigTimeoutTime" BU_SG_REL_ TME SG_ 2589283642 FCU_Hoeheninfo 5000;
BA_REL_ "GenSigTimeoutTime" BU_SG_REL_ TME SG_ 2589283642 FCU_Temp_Kuehlmittel_Stack_Ausl 5000;
BA_REL_ "GenSigTimeoutTime" BU_SG_REL_ TME SG_ 2589283642 FCU_Temp_Kuehlmittel_Stack_Einl 5000;
BA_REL_ "GenSigTimeoutTime" BU_SG_REL_ TME SG_ 2589283642 FCU_Temp_Kuehlmittel_KMP_Einl 5000;
BA_REL_ "GenSigTimeoutTime" BU_SG_REL_ TME SG_ 2589283646 FCU_Istposition_Thermostatventil 5000;
BA_REL_ "GenSigTimeoutTime" BU_SG_REL_ Gateway SG_ 2463978770 FCU_TK_Wasserstoffmasse_Netto 1000;
BA_REL_ "GenSigTimeoutTime" BU_SG_REL_ Gateway SG_ 2463978770 FCU_TK_H2_Fuellstand 1000;
BA_REL_ "GenSigTimeoutTime" BU_SG_REL_ Gateway SG_ 2463978770 FCU_TK_H2_Nachtanken_aktiv 1000;
BA_REL_ "GenSigTimeoutTime" BU_SG_REL_ Gateway SG_ 2463978770 FCU_TK_Meldungen 1000;
BA_REL_ "GenSigTimeoutTime" BU_SG_REL_ Gateway SG_ 2463978770 FCU_TK_Tankwarnungen 1000;
BA_REL_ "GenSigTimeoutTime" BU_SG_REL_ Gateway SG_ 606 FCU_Energieaequivalent 500;
BA_REL_ "GenSigTimeoutTime" BU_SG_REL_ Gateway SG_ 606 FCU_Verbrauch_FC_Nebag 500;
BA_REL_ "GenSigTimeoutTime" BU_SG_REL_ Gateway SG_ 606 FCU_Verbrauch_FC_Nebag_Ueberlauf 500;
BA_REL_ "GenSigTimeoutTime" BU_SG_REL_ Gateway SG_ 606 FCU_Verbrauch_H2 500;
BA_REL_ "GenSigTimeoutTime" BU_SG_REL_ Gateway SG_ 606 FCU_Verbrauch_H2_Ueberlauf 500;
BA_REL_ "GenSigTimeoutTime" BU_SG_REL_ Gateway SG_ 606 FCU_Verbrauch_FC 500;
BA_REL_ "GenSigTimeoutTime" BU_SG_REL_ Gateway SG_ 606 FCU_Verbrauch_FC_Ueberlauf 500;
BA_REL_ "GenSigTimeoutTime" BU_SG_REL_ Gateway SG_ 607 FCU_Verb_FC_Nebag_Masaequi_Ueb 500;
BA_REL_ "GenSigTimeoutTime" BU_SG_REL_ Gateway SG_ 607 FCU_Verb_FC_Nebag_Masaequi 500;
BA_REL_ "GenSigTimeoutTime" BU_SG_REL_ BMC_MLBevo SG_ 177 GE_Getriebestatus_02 5000;
BA_REL_ "GenSigTimeoutTime" BU_SG_REL_ TME SG_ 177 GE_Getriebestatus_02 5000;
BA_REL_ "GenSigTimeoutTime" BU_SG_REL_ AWC SG_ 310 HAL_VZ_Radwinkel 1000;
BA_REL_ "GenSigTimeoutTime" BU_SG_REL_ AWC SG_ 310 HAL_QBit_Radwinkel 1000;
BA_REL_ "GenSigTimeoutTime" BU_SG_REL_ AWC SG_ 310 HAL_Radwinkel 1000;
BA_REL_ "GenSigTimeoutTime" BU_SG_REL_ TME SG_ 1452 HVEM_Energie_Klima_Vorgabe_HighR 1000;
BA_REL_ "GenSigTimeoutTime" BU_SG_REL_ TME SG_ 1452 HVEM_Leistung_Klima_Vorgabe 1000;
BA_REL_ "GenSigTimeoutTime" BU_SG_REL_ Ladegeraet_Konzern SG_ 1452 HVEM_Nutzbare_Energie 1000;
BA_REL_ "GenSigTimeoutTime" BU_SG_REL_ TME SG_ 1452 HVEM_Energie_Klima_Vorgabe 1000;
BA_REL_ "GenSigTimeoutTime" BU_SG_REL_ Ladegeraet_Konzern SG_ 1362 HVEM_NVNachladen_Energie 1000;
BA_REL_ "GenSigTimeoutTime" BU_SG_REL_ TME SG_ 1362 HVEM_Max_VK_Betriebsdauer 1000;
BA_REL_ "GenSigTimeoutTime" BU_SG_REL_ Ladegeraet_Konzern SG_ 1362 HVEM_Nachladen_Anf 1000;
BA_REL_ "GenSigTimeoutTime" BU_SG_REL_ Ladegeraet_Konzern SG_ 1362 HVEM_SollStrom_HV 1000;
BA_REL_ "GenSigTimeoutTime" BU_SG_REL_ Ladegeraet_Konzern SG_ 1362 HVEM_Abschaltstatus 1000;
BA_REL_ "GenSigTimeoutTime" BU_SG_REL_ TME SG_ 1362 HVEM_FreigabeKlimatisierung 1000;
BA_REL_ "GenSigTimeoutTime" BU_SG_REL_ BMC_MLBevo SG_ 1283 HVK_01_CRC 1000;
BA_REL_ "GenSigTimeoutTime" BU_SG_REL_ DCDC_800V_PAG SG_ 1283 HVK_01_CRC 1000;
BA_REL_ "GenSigTimeoutTime" BU_SG_REL_ DCDC_HV SG_ 1283 HVK_01_CRC 1000;
BA_REL_ "GenSigTimeoutTime" BU_SG_REL_ DCDC_HV_02 SG_ 1283 HVK_01_CRC 1000;
BA_REL_ "GenSigTimeoutTime" BU_SG_REL_ Ladegeraet_2 SG_ 1283 HVK_01_CRC 1000;
BA_REL_ "GenSigTimeoutTime" BU_SG_REL_ Ladegeraet_Konzern SG_ 1283 HVK_01_CRC 1000;
BA_REL_ "GenSigTimeoutTime" BU_SG_REL_ LE1 SG_ 1283 HVK_01_CRC 1000;
BA_REL_ "GenSigTimeoutTime" BU_SG_REL_ LE2 SG_ 1283 HVK_01_CRC 1000;
BA_REL_ "GenSigTimeoutTime" BU_SG_REL_ LE_MLBevo SG_ 1283 HVK_01_CRC 1000;
BA_REL_ "GenSigTimeoutTime" BU_SG_REL_ TME SG_ 1283 HVK_01_CRC 1000;
BA_REL_ "GenSigTimeoutTime" BU_SG_REL_ BMC_MLBevo SG_ 1283 HVK_01_BZ 1000;
BA_REL_ "GenSigTimeoutTime" BU_SG_REL_ DCDC_800V_PAG SG_ 1283 HVK_01_BZ 1000;
BA_REL_ "GenSigTimeoutTime" BU_SG_REL_ DCDC_HV SG_ 1283 HVK_01_BZ 1000;
BA_REL_ "GenSigTimeoutTime" BU_SG_REL_ DCDC_HV_02 SG_ 1283 HVK_01_BZ 1000;
BA_REL_ "GenSigTimeoutTime" BU_SG_REL_ Ladegeraet_2 SG_ 1283 HVK_01_BZ 1000;
BA_REL_ "GenSigTimeoutTime" BU_SG_REL_ Ladegeraet_Konzern SG_ 1283 HVK_01_BZ 1000;
BA_REL_ "GenSigTimeoutTime" BU_SG_REL_ LE1 SG_ 1283 HVK_01_BZ 1000;
BA_REL_ "GenSigTimeoutTime" BU_SG_REL_ LE2 SG_ 1283 HVK_01_BZ 1000;
BA_REL_ "GenSigTimeoutTime" BU_SG_REL_ LE_MLBevo SG_ 1283 HVK_01_BZ 1000;
BA_REL_ "GenSigTimeoutTime" BU_SG_REL_ TME SG_ 1283 HVK_01_BZ 1000;
BA_REL_ "GenSigTimeoutTime" BU_SG_REL_ BMC_MLBevo SG_ 1283 HVK_Istmodus_Anf 1000;
BA_REL_ "GenSigTimeoutTime" BU_SG_REL_ DCDC_HV SG_ 1283 HVK_Istmodus_Anf 1000;
BA_REL_ "GenSigTimeoutTime" BU_SG_REL_ Ladegeraet_2 SG_ 1283 HVK_Istmodus_Anf 1000;
BA_REL_ "GenSigTimeoutTime" BU_SG_REL_ Ladegeraet_Konzern SG_ 1283 HVK_Istmodus_Anf 1000;
BA_REL_ "GenSigTimeoutTime" BU_SG_REL_ LE1 SG_ 1283 HVK_Istmodus_Anf 1000;
BA_REL_ "GenSigTimeoutTime" BU_SG_REL_ LE2 SG_ 1283 HVK_Istmodus_Anf 1000;
BA_REL_ "GenSigTimeoutTime" BU_SG_REL_ LE_MLBevo SG_ 1283 HVK_Istmodus_Anf 1000;
BA_REL_ "GenSigTimeoutTime" BU_SG_REL_ DCDC_HV_02 SG_ 1283 HVK_TN1_Sollmodus 1000;
BA_REL_ "GenSigTimeoutTime" BU_SG_REL_ FCU_MLBevo_FCEV SG_ 1283 HVK_MO_EmSollzustand 1000;
BA_REL_ "GenSigTimeoutTime" BU_SG_REL_ BMC_MLBevo SG_ 1283 HVK_BMS_Sollmodus 1000;
BA_REL_ "GenSigTimeoutTime" BU_SG_REL_ DCDC_800V_PAG SG_ 1283 HVK_DCDC_Sollmodus 1000;
BA_REL_ "GenSigTimeoutTime" BU_SG_REL_ DCDC_HV SG_ 1283 HVK_DCDC_Sollmodus 1000;
BA_REL_ "GenSigTimeoutTime" BU_SG_REL_ LE_MLBevo SG_ 1283 HVK_DCDC_Sollmodus 1000;
BA_REL_ "GenSigTimeoutTime" BU_SG_REL_ TME SG_ 1283 HVK_EKK_Sollmodus 1000;
BA_REL_ "GenSigTimeoutTime" BU_SG_REL_ TME SG_ 1283 HVK_HVPTC_Sollmodus 1000;
BA_REL_ "GenSigTimeoutTime" BU_SG_REL_ DCDC_HV_02 SG_ 1283 HVK_HVLM_Sollmodus 1000;
BA_REL_ "GenSigTimeoutTime" BU_SG_REL_ Ladegeraet_Konzern SG_ 1283 HVK_HVLM_Sollmodus 1000;
BA_REL_ "GenSigTimeoutTime" BU_SG_REL_ DCDC_HV_02 SG_ 1283 HV_Bordnetz_aktiv 1000;
BA_REL_ "GenSigTimeoutTime" BU_SG_REL_ Ladegeraet_Konzern SG_ 1283 HV_Bordnetz_aktiv 1000;
BA_REL_ "GenSigTimeoutTime" BU_SG_REL_ LE1 SG_ 1283 HV_Bordnetz_aktiv 1000;
BA_REL_ "GenSigTimeoutTime" BU_SG_REL_ LE2 SG_ 1283 HV_Bordnetz_aktiv 1000;
BA_REL_ "GenSigTimeoutTime" BU_SG_REL_ LE_MLBevo SG_ 1283 HV_Bordnetz_aktiv 1000;
BA_REL_ "GenSigTimeoutTime" BU_SG_REL_ Ladegeraet_Konzern SG_ 1283 HV_Bordnetz_Fehler 1000;
BA_REL_ "GenSigTimeoutTime" BU_SG_REL_ TME SG_ 1283 HV_Bordnetz_Fehler 1000;
BA_REL_ "GenSigTimeoutTime" BU_SG_REL_ DCDC_800V_PAG SG_ 1283 HVK_AktiveEntladung_Anf 1000;
BA_REL_ "GenSigTimeoutTime" BU_SG_REL_ DCDC_HV SG_ 1283 HVK_AktiveEntladung_Anf 1000;
BA_REL_ "GenSigTimeoutTime" BU_SG_REL_ DCDC_HV_02 SG_ 1283 HVK_AktiveEntladung_Anf 1000;
BA_REL_ "GenSigTimeoutTime" BU_SG_REL_ FCU_MLBevo_FCEV SG_ 1283 HVK_AktiveEntladung_Anf 1000;
BA_REL_ "GenSigTimeoutTime" BU_SG_REL_ LE1 SG_ 1283 HVK_AktiveEntladung_Anf 1000;
BA_REL_ "GenSigTimeoutTime" BU_SG_REL_ LE2 SG_ 1283 HVK_AktiveEntladung_Anf 1000;
BA_REL_ "GenSigTimeoutTime" BU_SG_REL_ LE_MLBevo SG_ 1283 HVK_AktiveEntladung_Anf 1000;
BA_REL_ "GenSigTimeoutTime" BU_SG_REL_ BMC_MLBevo SG_ 1283 HVK_Iso_Messung_Start 1000;
BA_REL_ "GenSigTimeoutTime" BU_SG_REL_ DCDC_800V_PAG SG_ 1283 HVK_DCDC_EKK_Sollmodus 1000;
BA_REL_ "GenSigTimeoutTime" BU_SG_REL_ AWC SG_ 1381 HVLM_Zustand_LED 1000;
BA_REL_ "GenSigTimeoutTime" BU_SG_REL_ BMC_MLBevo SG_ 1381 HVLM_Start_Spannungsmessung_DCLS 1000;
BA_REL_ "GenSigTimeoutTime" BU_SG_REL_ Gateway SG_ 1381 PnC_Trigger_OBC_cGW 1000;
BA_REL_ "GenSigTimeoutTime" BU_SG_REL_ Gateway SG_ 1381 HVLM_FreigabeKlimatisierung 1000;
BA_REL_ "GenSigTimeoutTime" BU_SG_REL_ Gateway_PAG SG_ 1381 HVLM_FreigabeKlimatisierung 1000;
BA_REL_ "GenSigTimeoutTime" BU_SG_REL_ TME SG_ 1381 HVLM_FreigabeKlimatisierung 1000;
BA_REL_ "GenSigTimeoutTime" BU_SG_REL_ BMC_MLBevo SG_ 1381 HVLM_IsoMessung_Anf 1000;
BA_REL_ "GenSigTimeoutTime" BU_SG_REL_ DCDC_HV_02 SG_ 1381 HVLM_IsoMessung_Anf 1000;
BA_REL_ "GenSigTimeoutTime" BU_SG_REL_ Gateway SG_ 1381 HVLM_IstSpannung_HV 1000;
BA_REL_ "GenSigTimeoutTime" BU_SG_REL_ Gateway_PAG SG_ 1381 HVLM_IstSpannung_HV 1000;
BA_REL_ "GenSigTimeoutTime" BU_SG_REL_ AWC SG_ 1340 HVLM_04_CRC 1000;
BA_REL_ "GenSigTimeoutTime" BU_SG_REL_ BMC_MLBevo SG_ 1340 HVLM_04_CRC 1000;
BA_REL_ "GenSigTimeoutTime" BU_SG_REL_ DCDC_HV SG_ 1340 HVLM_04_CRC 1000;
BA_REL_ "GenSigTimeoutTime" BU_SG_REL_ Gateway SG_ 1340 HVLM_04_CRC 1000;
BA_REL_ "GenSigTimeoutTime" BU_SG_REL_ Gateway_PAG SG_ 1340 HVLM_04_CRC 1000;
BA_REL_ "GenSigTimeoutTime" BU_SG_REL_ AWC SG_ 1340 HVLM_04_BZ 1000;
BA_REL_ "GenSigTimeoutTime" BU_SG_REL_ BMC_MLBevo SG_ 1340 HVLM_04_BZ 1000;
BA_REL_ "GenSigTimeoutTime" BU_SG_REL_ DCDC_HV SG_ 1340 HVLM_04_BZ 1000;
BA_REL_ "GenSigTimeoutTime" BU_SG_REL_ Gateway SG_ 1340 HVLM_04_BZ 1000;
BA_REL_ "GenSigTimeoutTime" BU_SG_REL_ Gateway_PAG SG_ 1340 HVLM_04_BZ 1000;
BA_REL_ "GenSigTimeoutTime" BU_SG_REL_ TME SG_ 1340 HVLM_STH_Betriebsmodus 1000;
BA_REL_ "GenSigTimeoutTime" BU_SG_REL_ Gateway SG_ 1340 HVLM_HVEM_MaxLeistung 1000;
BA_REL_ "GenSigTimeoutTime" BU_SG_REL_ Gateway_PAG SG_ 1340 HVLM_HVEM_MaxLeistung 1000;
BA_REL_ "GenSigTimeoutTime" BU_SG_REL_ Gateway SG_ 1340 HVLM_Status_Netz 1000;
BA_REL_ "GenSigTimeoutTime" BU_SG_REL_ Gateway_PAG SG_ 1340 HVLM_Status_Netz 1000;
BA_REL_ "GenSigTimeoutTime" BU_SG_REL_ TME SG_ 1340 HVLM_Status_Netz 1000;
BA_REL_ "GenSigTimeoutTime" BU_SG_REL_ Gateway SG_ 1340 HVLM_Ladeart 1000;
BA_REL_ "GenSigTimeoutTime" BU_SG_REL_ Gateway_PAG SG_ 1340 HVLM_Ladeart 1000;
BA_REL_ "GenSigTimeoutTime" BU_SG_REL_ TME SG_ 1340 HVLM_VK_STH_Einsatz 1000;
BA_REL_ "GenSigTimeoutTime" BU_SG_REL_ Gateway SG_ 1340 HVLM_VK_Modus 1000;
BA_REL_ "GenSigTimeoutTime" BU_SG_REL_ Gateway_PAG SG_ 1340 HVLM_VK_Modus 1000;
BA_REL_ "GenSigTimeoutTime" BU_SG_REL_ TME SG_ 1340 HVLM_VK_Modus 1000;
BA_REL_ "GenSigTimeoutTime" BU_SG_REL_ DCDC_800V_PAG SG_ 1340 HVLM_IstModus_02 1000;
BA_REL_ "GenSigTimeoutTime" BU_SG_REL_ DCDC_HV SG_ 1340 HVLM_IstModus_02 1000;
BA_REL_ "GenSigTimeoutTime" BU_SG_REL_ Gateway SG_ 1340 HVLM_IstModus_02 1000;
BA_REL_ "GenSigTimeoutTime" BU_SG_REL_ Gateway_PAG SG_ 1340 HVLM_IstModus_02 1000;
BA_REL_ "GenSigTimeoutTime" BU_SG_REL_ TME SG_ 1340 HVLM_IstModus_02 1000;
BA_REL_ "GenSigTimeoutTime" BU_SG_REL_ Gateway SG_ 1340 HVLM_HV_Anf 1000;
BA_REL_ "GenSigTimeoutTime" BU_SG_REL_ Gateway_PAG SG_ 1340 HVLM_HV_Anf 1000;
BA_REL_ "GenSigTimeoutTime" BU_SG_REL_ Gateway SG_ 1340 HVLM_Fehlerstatus 1000;
BA_REL_ "GenSigTimeoutTime" BU_SG_REL_ Gateway_PAG SG_ 1340 HVLM_Fehlerstatus 1000;
BA_REL_ "GenSigTimeoutTime" BU_SG_REL_ AWC SG_ 1340 HVLM_AWC_Sollmodus 1000;
BA_REL_ "GenSigTimeoutTime" BU_SG_REL_ BMC_MLBevo SG_ 1340 HVLM_Stecker_Status 1000;
BA_REL_ "GenSigTimeoutTime" BU_SG_REL_ Gateway SG_ 1340 HVLM_Stecker_Status 1000;
BA_REL_ "GenSigTimeoutTime" BU_SG_REL_ Gateway_PAG SG_ 1340 HVLM_Stecker_Status 1000;
BA_REL_ "GenSigTimeoutTime" BU_SG_REL_ TME SG_ 1340 HVLM_Stecker_Status 1000;
BA_REL_ "GenSigTimeoutTime" BU_SG_REL_ AWC SG_ 1340 HVLM_LadeAnforderung 1000;
BA_REL_ "GenSigTimeoutTime" BU_SG_REL_ Gateway SG_ 1340 HVLM_LadeAnforderung 1000;
BA_REL_ "GenSigTimeoutTime" BU_SG_REL_ Gateway_PAG SG_ 1340 HVLM_LadeAnforderung 1000;
BA_REL_ "GenSigTimeoutTime" BU_SG_REL_ TME SG_ 1340 HVLM_LadeAnforderung 1000;
BA_REL_ "GenSigTimeoutTime" BU_SG_REL_ Gateway SG_ 1340 HVLM_MaxBatLadestromHV 1000;
BA_REL_ "GenSigTimeoutTime" BU_SG_REL_ Gateway_PAG SG_ 1340 HVLM_MaxBatLadestromHV 1000;
BA_REL_ "GenSigTimeoutTime" BU_SG_REL_ Gateway SG_ 1160 HVLM_MaxLadeLeistung 5000;
BA_REL_ "GenSigTimeoutTime" BU_SG_REL_ Gateway_PAG SG_ 1160 HVLM_MaxLadeLeistung 5000;
BA_REL_ "GenSigTimeoutTime" BU_SG_REL_ TME SG_ 1160 HVLM_MaxLadeLeistung 5000;
BA_REL_ "GenSigTimeoutTime" BU_SG_REL_ Gateway SG_ 1160 HVLM_MaxSpannung_DCLS 5000;
BA_REL_ "GenSigTimeoutTime" BU_SG_REL_ Gateway_PAG SG_ 1160 HVLM_MaxSpannung_DCLS 5000;
BA_REL_ "GenSigTimeoutTime" BU_SG_REL_ Gateway SG_ 1160 HVLM_IstStrom_DCLS 5000;
BA_REL_ "GenSigTimeoutTime" BU_SG_REL_ Gateway_PAG SG_ 1160 HVLM_IstStrom_DCLS 5000;
BA_REL_ "GenSigTimeoutTime" BU_SG_REL_ Gateway SG_ 1160 HVLM_MaxStrom_DCLS 5000;
BA_REL_ "GenSigTimeoutTime" BU_SG_REL_ Gateway_PAG SG_ 1160 HVLM_MaxStrom_DCLS 5000;
BA_REL_ "GenSigTimeoutTime" BU_SG_REL_ Gateway SG_ 1160 HVLM_MinSpannung_DCLS 5000;
BA_REL_ "GenSigTimeoutTime" BU_SG_REL_ Gateway_PAG SG_ 1160 HVLM_MinSpannung_DCLS 5000;
BA_REL_ "GenSigTimeoutTime" BU_SG_REL_ Gateway SG_ 1160 HVLM_MinStrom_DCLS 5000;
BA_REL_ "GenSigTimeoutTime" BU_SG_REL_ Gateway_PAG SG_ 1160 HVLM_MinStrom_DCLS 5000;
BA_REL_ "GenSigTimeoutTime" BU_SG_REL_ BMC_MLBevo SG_ 2589283485 HVLM_Funktion_Dauer_BattKond 5000;
BA_REL_ "GenSigTimeoutTime" BU_SG_REL_ TME SG_ 2589283485 HVLM_BattKond_Anf 5000;
BA_REL_ "GenSigTimeoutTime" BU_SG_REL_ TME SG_ 2589283485 HVLM_Dauer_Klima_02 5000;
BA_REL_ "GenSigTimeoutTime" BU_SG_REL_ AWC SG_ 2589283605 HVLM_AWC_Sollstrom 2000;
VAL_ 116 EM2_IstMoment 4094 "Init" 4095 "Fehler" ;
VAL_ 116 EM2_IstDrehzahl_alt 32766 "Init" 32767 "Fehler" ;
VAL_ 116 EM2_IstDrehzahl 32766 "Init" 32767 "Fehler" ;
VAL_ 116 EM2_offene_Klemme_Verfuegbar 0 "offene_Klemme_nicht_verfuegbar" 1 "offene_Klemme_verfuegbar" ;
VAL_ 116 EM2_MaxZul_Drehzahl 254 "Init" 255 "Fehler" ;
VAL_ 199 EM2_Freigabe_Info_WFS 0 "ungueltig" 1 "gueltig" ;
VAL_ 199 EM2_Sperr_Info_WFS 0 "nicht_gesperrt" 1 "gesperrt" ;
VAL_ 199 EM2_AR_aktiv 0 "Init" ;
VAL_ 199 EM2_Eta_Sys 510 "Init" 511 "Fehler" ;
VAL_ 199 EM2_IstStrom 2046 "Init" 2047 "Fehler" ;
VAL_ 199 EM2_Fehler_ElAntriebFreilauf_Anf 0 "Init" 1 "Fehler_EM_im_Freilauf" ;
VAL_ 199 EM2_Abregelung_Temperatur 0 "Init" 1 "Abregelung_Temperatur" ;
VAL_ 199 EM2_AnlernenElMotor_Anf 0 "kein_Diagnose_Request" 1 "Diagnose_Request" ;
VAL_ 199 EM2_Freigabe_Verfallsinfo_WFS 0 "Aus" 1 "Ein" ;
VAL_ 199 EM2_Parken_WFS_Status 0 "Limitierung_Inaktiv" 1 "Limitierung_Aktiv" 2 "Abbruch" ;
VAL_ 199 EM2_HV_betriebsbereit 0 "Init" 1 "Ready_HV" ;
VAL_ 1105 EM2_MaxPred_Moment 2046 "Init" 2047 "Fehler" ;
VAL_ 1105 EM2_MinPred_Moment 2046 "Init" 2047 "Fehler" ;
VAL_ 1105 EM2_MaxPred_Abknickdrehzahl 255 "Init" ;
VAL_ 1105 EM2_MinPred_Abknickdrehzahl 255 "Init" ;
VAL_ 1105 EM2_Fehler_Leistungsred 0 "Init" 1 "Leistungsreduzierung" ;
VAL_ 1105 EM2_IstSpannung 4094 "Init" 4095 "Fehler" ;
VAL_ 2527679713 EM2_RtmWarnKommunikation 0 "kein_Fehler" 1 "Fehler_Stufe_1" 2 "Fehler_Stufe_2" 3 "Fehler_Stufe_3" 4 "reserviert" 5 "reserviert" 6 "reserviert" 7 "reserviert" ;
VAL_ 2527679713 EM2_RtmWarnUeberdrehzahl 0 "kein_Fehler" 1 "Fehler_Stufe_1" 2 "Fehler_Stufe_2" 3 "Fehler_Stufe_3" 4 "reserviert" 5 "reserviert" 6 "reserviert" 7 "reserviert" ;
VAL_ 2527679713 EM2_RtmWarnUeberstrom 0 "kein_Fehler" 1 "Fehler_Stufe_1" 2 "Fehler_Stufe_2" 3 "Fehler_Stufe_3" 4 "reserviert" 5 "reserviert" 6 "reserviert" 7 "reserviert" ;
VAL_ 2527679649 EM3_OBD_Lampe_Anf 0 "kein_MIL_Request" 1 "MIL_Request" ;
VAL_ 2527679649 EM3_FoD_Freischaltstatus_Fkt1 0 "keine_FoD_Freischaltung" 1 "FoD_Freischaltung_PerformanzP" ;
VAL_ 2527679649 EM3_Temperatur_ElMotor 254 "Init" 255 "Fehler" ;
VAL_ 2527679649 EM3_Temperatur_PWR 254 "Init" 255 "Fehler" ;
VAL_ 2527679649 EM3_Temperatur_Rotor 254 "Init" 255 "Fehler" ;
VAL_ 2527679649 EM3_Verlustleistung_02 1022 "Init" 1023 "Fehler" ;
VAL_ 2527679649 EM3_Temperatur_KW 254 "Init" 255 "Fehler" ;
VAL_ 2463978616 EM3_Istmodus2 0 "Standby" 1 "Momentenreg" 2 "Int_Drehzahlreg" 3 "Spannungsreg" 4 "Ext_Drehzahlreg" 5 "Inverter_Fehler" 6 "Kalibrierung" 8 "Freilauf" 10 "eTV_Modus" 15 "Initialisierung" ;
VAL_ 2463978616 EM3_Fehlerstatus 0 "Komponente_IO" 1 "Eingeschr_KompFkt_Entlad_defekt" 2 "Eingeschr_KompFkt_Phasenabriss" 3 "Eingeschr_KompFkt_Interlock" 4 "Eingeschr_KompFkt_res" 6 "Keine_Komponentenfunktion" 7 "Init" ;
VAL_ 2463978616 EM3_Status_Spgfreiheit 0 "Init" 1 "HV_Komponente_spannungsfrei" 2 "HV_Komp_nicht_spannungsfrei" 3 "Fehler_nicht_spannungsfrei" ;
VAL_ 2463978616 EM3_HYB_11_Sendestatus 0 "EM3_HYB_11_wird_mit_480ms_gesendet" 1 "EM3_HYB_11_wird_mit_40ms_gesendet" ;
VAL_ 2463978616 EM3_EM_SollVolumenstrom 62 "Init" 63 "Fehler" ;
VAL_ 117 EM3_IstMoment 4094 "Init" 4095 "Fehler" ;
VAL_ 117 EM3_IstDrehzahl_alt 32766 "Init" 32767 "Fehler" ;
VAL_ 117 EM3_IstDrehzahl 32766 "Init" 32767 "Fehler" ;
VAL_ 117 EM3_offene_Klemme_Verfuegbar 0 "offene_Klemme_nicht_verfuegbar" 1 "offene_Klemme_verfuegbar" ;
VAL_ 117 EM3_MaxZul_Drehzahl 254 "Init" 255 "Fehler" ;
VAL_ 200 EM3_Freigabe_Info_WFS 0 "ungueltig" 1 "gueltig" ;
VAL_ 200 EM3_Sperr_Info_WFS 0 "nicht_gesperrt" 1 "gesperrt" ;
VAL_ 200 EM3_AR_aktiv 0 "Init" ;
VAL_ 200 EM3_Eta_Sys 510 "Init" 511 "Fehler" ;
VAL_ 200 EM3_IstStrom 2046 "Init" 2047 "Fehler" ;
VAL_ 200 EM3_Fehler_ElAntriebFreilauf_Anf 0 "Init" 1 "Fehler_EM_im_Freilauf" ;
VAL_ 200 EM3_Abregelung_Temperatur 0 "Init" 1 "Abregelung_Temperatur" ;
VAL_ 200 EM3_AnlernenElMotor_Anf 0 "kein_Diagnose_Request" 1 "Diagnose_Request" ;
VAL_ 200 EM3_Freigabe_Verfallsinfo_WFS 0 "Aus" 1 "Ein" ;
VAL_ 200 EM3_Parken_WFS_Status 0 "Limitierung_Inaktiv" 1 "Limitierung_Aktiv" 2 "Abbruch" ;
VAL_ 200 EM3_HV_betriebsbereit 0 "Init" 1 "Ready_HV" ;
VAL_ 1104 EM3_MaxPred_Moment 2046 "Init" 2047 "Fehler" ;
VAL_ 1104 EM3_MinPred_Moment 2046 "Init" 2047 "Fehler" ;
VAL_ 1104 EM3_MaxPred_Abknickdrehzahl 255 "Init" ;
VAL_ 1104 EM3_MinPred_Abknickdrehzahl 255 "Init" ;
VAL_ 1104 EM3_Fehler_Leistungsred 0 "Init" 1 "Leistungsreduzierung" ;
VAL_ 1104 EM3_IstSpannung 4094 "Init" 4095 "Fehler" ;
VAL_ 2527679714 EM3_RtmWarnKommunikation 0 "kein_Fehler" 1 "Fehler_Stufe_1" 2 "Fehler_Stufe_2" 3 "Fehler_Stufe_3" 4 "reserviert" 5 "reserviert" 6 "reserviert" 7 "reserviert" ;
VAL_ 2527679714 EM3_RtmWarnUeberdrehzahl 0 "kein_Fehler" 1 "Fehler_Stufe_1" 2 "Fehler_Stufe_2" 3 "Fehler_Stufe_3" 4 "reserviert" 5 "reserviert" 6 "reserviert" 7 "reserviert" ;
VAL_ 2527679714 EM3_RtmWarnUeberstrom 0 "kein_Fehler" 1 "Fehler_Stufe_1" 2 "Fehler_Stufe_2" 3 "Fehler_Stufe_3" 4 "reserviert" 5 "reserviert" 6 "reserviert" 7 "reserviert" ;
VAL_ 278 ESP_QBit_Wegimpuls_VL 0 "gueltiger_Wert" 1 "Ersatz_Init_oder_Fehlerwert" ;
VAL_ 278 ESP_QBit_Wegimpuls_VR 0 "gueltiger_Wert" 1 "Ersatz_Init_oder_Fehlerwert" ;
VAL_ 278 ESP_QBit_Wegimpuls_HL 0 "gueltiger_Wert" 1 "Ersatz_Init_oder_Fehlerwert" ;
VAL_ 278 ESP_QBit_Wegimpuls_HR 0 "gueltiger_Wert" 1 "Ersatz_Init_oder_Fehlerwert" ;
VAL_ 278 ESP_Wegimpuls_VL 1021 "Init" 1022 "Unterspannung" 1023 "Fehler" ;
VAL_ 278 ESP_Wegimpuls_VR 1021 "Init" 1022 "Unterspannung" 1023 "Fehler" ;
VAL_ 278 ESP_Wegimpuls_HL 1021 "Init" 1022 "Unterspannung" 1023 "Fehler" ;
VAL_ 278 ESP_Wegimpuls_HR 1021 "Init" 1022 "Unterspannung" 1023 "Fehler" ;
VAL_ 278 ESP_VL_Fahrtrichtung 0 "Vorwaerts" 1 "Rueckwaerts" 2 "Init" 3 "ungueltig_oder_nicht_verbaut" ;
VAL_ 278 ESP_VR_Fahrtrichtung 0 "Vorwaerts" 1 "Rueckwaerts" 2 "Init" 3 "ungueltig_oder_nicht_verbaut" ;
VAL_ 278 ESP_HL_Fahrtrichtung 0 "Vorwaerts" 1 "Rueckwaerts" 2 "Init" 3 "ungueltig_oder_nicht_verbaut" ;
VAL_ 278 ESP_HR_Fahrtrichtung 0 "Vorwaerts" 1 "Rueckwaerts" 2 "Init" 3 "ungueltig_oder_nicht_verbaut" ;
VAL_ 418 HMS_P_beibehalten_GE 0 "P_nicht_beibehalten" 1 "P_beibehalten" 2 "Init" 3 "Fehler" ;
VAL_ 418 HMS_Konsistenz_GE 0 "kein_Fehler_erkannt" 1 "Fehler_erkannt" ;
VAL_ 418 HMS_Konsistenz_IPA 0 "kein_Fehler_erkannt" 1 "Fehler_erkannt" ;
VAL_ 418 HMS_Konsistenz_STA 0 "kein_Fehler_erkannt" 1 "Fehler_erkannt" ;
VAL_ 418 HMS_Konsistenz_MO 0 "kein_Fehler_erkannt" 1 "Fehler_erkannt" ;
VAL_ 418 HMS_halten_nicht_verfuegbar 0 "verfuegbar" 1 "nicht_verfuegbar" ;
VAL_ 418 NL_PRIM_STP_01_Status 0 "Notlauf_inaktiv" 1 "Notlauf_bereit" 2 "Notlauf_aktiv" 3 "Notlauf_nicht_verfuegbar" 4 "Notlauf_aktivierbar" ;
VAL_ 418 VMM_Warnblinken 0 "Aus" 1 "An" ;
VAL_ 418 VZM_Status 0 "Initialisierung" 1 "Verfuegbar" 2 "Verfuegbar_mit_eingeschraenkter_Performance" 3 "Nicht_Verfuegbar" 4 "Fehler" ;
VAL_ 418 HMS_Notstopp_Status 0 "Off_Init" 1 "Inaktiv" 2 "Ready" 3 "Aktiv" 4 "Pending" 7 "nicht_Verfuegbar" ;
VAL_ 418 HMS_parken_nicht_verfuegbar 0 "verfuegbar" 1 "nicht_verfuegbar" ;
VAL_ 418 HMS_Anforderung_GE 0 "keine_Anforderung" 1 "P_einlegen" ;
VAL_ 418 HMS_Systemstatus 0 "keine_Funktion_aktiv" 1 "Halten_aktiv" 2 "Parken_angefordert" 3 "Parken_aktiv" 4 "Parken_beibehalten_aktiv" 5 "Anfahren_aktiv" 6 "Loeseanforderung_aktiv" 7 "Loeseanforderung_durch_Fahrer" 8 "Abrutschen_erkannt" 9 "Halten_Standby_aktiv" 10 "Anfahren_Standby_aktiv" 14 "Init" 15 "Fehler" ;
VAL_ 418 HMS_Stillstand 0 "kein_Stillstand" 1 "Stillstand_frueh" 2 "Stillstand" 6 "Init" 7 "Fehler" ;
VAL_ 418 HMS_aktives_System 0 "kein_System__Init_Fehler" 1 "Fahreranforderung_aktiv" 2 "HMS_intern_aktiv" 3 "ACC_aktiv" 4 "Autohold_aktiv" 5 "HHC_aktiv" 6 "HVLM_aktiv" 7 "Getriebe_aktiv" 8 "EBKV_aktiv" 9 "ParkAssist_aktiv" 10 "ARA_aktiv" 12 "autonomous_Hold_aktiv" 13 "STA_aktiv" 14 "Motor_aktiv" 15 "EA_aktiv" 16 "VLK_aktiv" ;
VAL_ 418 HMS_Konsistenz_HVLM 0 "kein_Fehler_erkannt" 1 "Fehler_erkannt" ;
VAL_ 418 HMS_Konsistenz_ACC 0 "kein_Fehler_erkannt" 1 "Fehler_erkannt" ;
VAL_ 418 HMS_Fehlerstatus 0 "kein_Fehler" 1 "Halten_nicht_moeglich" 2 "Sonderbetriebsmodus_aktiv" 3 "Systemeinschraenkung" 4 "Systemstoerung" ;
VAL_ 418 ESP_Index_Haltemoment 0 "Bremsmoment" 1 "Antriebsmoment" ;
VAL_ 418 ESP_Haltemoment 1022 "Init" 1023 "Fehler" ;
VAL_ 1629 BR_Systemart 0 "ABS" 1 "ABS_ASR" 2 "ESP" 3 "ESP_mit_integrierter_EPB" ;
VAL_ 1629 ESP_SpannungsAnf_02 0 "keine_Anforderung" 1 "Anforderung_Stufe1" 2 "Anforderung_Stufe2" 3 "Anforderung_Stufe3" ;
VAL_ 1629 ESP_Charisma_FahrPr 0 "keine_Funktion" 1 "Programm_1" 2 "Programm_2" 3 "Programm_3" 4 "Programm_4" 5 "Programm_5" 6 "Programm_6" 7 "Programm_7" 8 "Programm_8" 9 "Programm_9" 10 "Programm_10" 11 "Programm_11" 12 "Programm_12" 13 "Programm_13" 14 "Programm_14" 15 "Programm_15" ;
VAL_ 1629 ESP_Charisma_Status 0 "Init" 1 "verfuegbar" 2 "nicht_verfuegbar" 3 "asynchron_durch_Fahrerwunsch" ;
VAL_ 1629 ESP_Wiederstart_Anz_01 0 "keine_Anzeige" 1 "Rueckwaertsrollen" ;
VAL_ 1629 ESP_Wiederstart_Anz_02 0 "keine_Anzeige" 1 "Autohold_Rutschen" ;
VAL_ 1629 ESP_Wiederstart_Anz_03 0 "keine_Anzeige" 1 "Offroad_HDC" ;
VAL_ 1629 ESP_Wiederstart_Anz_04 0 "keine_Anzeige" 1 "ESC_Off" ;
VAL_ 1629 ESP_Stoppverbot_Anz_01 0 "keine_Anzeige" 1 "Notbremsung_aktiv" ;
VAL_ 1629 ESP_Stoppverbot_Anz_02 0 "keine_Anzeige" 1 "Autohold_AVH_Rutschen" ;
VAL_ 1629 ESP_Stoppverbot_Anz_03 0 "keine_Anzeige" 1 "Rueckwaertsrollen" ;
VAL_ 1629 ESP_Stoppverbot_Anz_04 0 "keine_Anzeige" 1 "ESP_Pumpenlauf" ;
VAL_ 1629 ESP_Stoppverbot_Anz_05 0 "keine_Anzeige" 1 "ESP_OFF" ;
VAL_ 1629 ESP_Stoppverbot_Anz_06 0 "keine_Anzeige" 1 "Offroad_HDC" ;
VAL_ 1629 ESP_Stoppverbot_Anz_07 0 "keine_Anzeige" 1 "ESP_Haltefunktion_nicht_verfuegbar" ;
VAL_ 1629 ESP_Stoppverbot_Anz_Std 0 "keine_Anzeige" 1 "Standard_Stoppvetogrund" ;
VAL_ 1629 ESP_Dachrelingsensor 0 "Sensor_nicht_verbaut" 1 "Quertraeger_montiert" 2 "Quertraeger_nicht_montiert" 3 "Fehler" ;
VAL_ 1629 ESP_Stoppverbot_Anz_08 0 "keine_Anzeige" 1 "Neigungsbegrenzung" ;
VAL_ 1629 HDC_Charisma_FahrPr 0 "keine_Funktion" 1 "Programm_1" 2 "Programm_2" 3 "Programm_3" 4 "Programm_4" 5 "Programm_5" 6 "Programm_6" 7 "Programm_7" 8 "Programm_8" 9 "Programm_9" 10 "Programm_10" 11 "Programm_11" 12 "Programm_12" 13 "Programm_13" 14 "Programm_14" 15 "Programm_15" ;
VAL_ 1629 HDC_Charisma_Status 0 "Init" 1 "verfuegbar" 2 "nicht_verfuegbar" 3 "asynchron_durch_Fahrerwunsch" ;
VAL_ 1629 BR_QBit_Reifenumfang 0 "gueltiger_Wert" 1 "Ersatz_Init_oder_Fehlerwert" ;
VAL_ 795 ESP_Lampe 0 "Aus" 1 "Ein" ;
VAL_ 795 ABS_Lampe 0 "Aus" 1 "Ein" ;
VAL_ 795 BK_Lampe_02 0 "aus" 1 "ein_statisch" 3 "Warnung" ;
VAL_ 795 TC_Lampe 0 "Aus" 1 "Ein" ;
VAL_ 795 ESP_m_Raddrehz 32765 "Unterspannung" 32766 "Init" 32767 "Fehler" ;
VAL_ 795 ESP_Textanzeigen_03 0 "kein_Text" 1 "ESP_Stoerung" 2 "ABS_Stoerung" 3 "ESP_ABS_Stoerung" 4 "Werkstatt_Bremse" 5 "ASR_Stoerung" 6 "ESP_switched_off" 7 "ASR_off" 8 "ESP_ASR_on" 10 "keine_Bremskraftverstaerkung" 11 "ASR_aktiviert" 12 "ABS_ASR_Stoerung" 15 "ESP_offroad" 17 "ESP_sport" 18 "ESP_Zwangsaktivierung" 19 "ESP_Taster_Info" 20 "TC_aktiv" 21 "reserviert_fuer_Verlwarn" 22 "TC_switched_off" 23 "Verlwarn_akt_Rollsicher_inakt" 24 "ESP_SuperSport" 25 "ESP_Offroad_nicht_verfuegbar" ;
VAL_ 795 ESP_Meldungen 0 "keine_Anzeige" 1 "Autohold_Hinweis_1" 2 "Stoerung_Autohold" 3 "Stoerung_Hillholder" 4 "Uebernehmen" 5 "Autohold_aus" 6 "Autohold_Hinweis_2" ;
VAL_ 795 ESP_Fehlerstatus_Wegimp 0 "Wegimpulse_iO" 1 "Fehler" ;
VAL_ 795 ESP_Wegimp_Ueberlauf 0 "Reset_und_kein_Ueberlauf" 1 "mindestens_1x_Ueberlauf" ;
VAL_ 795 ESP_QBit_Wegimp_VA 0 "gueltiger_Wert" 1 "Ersatz_Init_oder_Fehlerwert" ;
VAL_ 795 ESP_HDC_Geschw_Farbe 0 "Standard_Farbe" 1 "abweichende_Farbe" ;
VAL_ 795 ESP_Off_Lampe 0 "Lampe_aus" 1 "Lampe_ein" ;
VAL_ 795 ESP_HDC_Regelgeschw 0 "nicht_verbaut" 125 "HDC_Standby" 126 "Init" 127 "Fehler" ;
VAL_ 795 ESP_BKV_Warnung 0 "keine_Anzeige" 1 "keine_Bremskraftverstaerkung" ;
VAL_ 2463978667 ESCGeneratorSollMoment 4094 "Init" 4095 "Fehler" ;
VAL_ 2463978667 TSMomBegrenzung 4094 "Init" 4095 "Fehler" ;
VAL_ 2463978667 ESC_Anf_Mindestreku 0 "nicht_angefordert" 1 "angefordert" ;
VAL_ 2463978667 ESC_Status_Schaltkennfeld_sek 0 "keine Anforderung" 1 "ESC Schaltkennfeld" 2 "Schaltverbot" 3 "nicht belegt" ;
VAL_ 2463978667 ESP_M_hyd_anteil_Bremse 4094 "Init" 4095 "Fehler" ;
VAL_ 2527679662 ESC_Reku_Anzeige 0 "keine_Anzeige" 1 "Reku_Anzeige_aktiv" ;
VAL_ 2527679662 ESC_Anf_LadeVorhalt 0 "keine_Anforderung" 1 "SOC_Vorhalt_1_Prozent" 2 "SOC_Vorhalt_2_Prozent" 3 "SOC_Vorhalt_3_Prozent" 4 "SOC_Vorhalt_4_Prozent" 5 "SOC_Vorhalt_5_Prozent" 6 "SOC_Vorhalt_6_Prozent" 7 "SOC_Vorhalt_7_Prozent" 8 "SOC_Vorhalt_8_Prozent" 9 "SOC_Vorhalt_9_Prozent" 10 "SOC_Vorhalt_10_Prozent" 11 "SOC_Vorhalt_11_Prozent" 12 "SOC_Vorhalt_12_Prozent" 13 "SOC_Vorhalt_13_Prozent" 14 "SOC_Vorhalt_14_Prozent" 15 "Init" ;
VAL_ 2527679662 ESC_Textanzeigen_SysSpez 0 "kein_Text" 1 "Schiebedach_offen_Zwangsakt" 2 "Schiebedach_Stoerung_Zwangsakt" 3 "WETaktiv_ESCoff_nicht_verfuegbar" 4 "RANGEaktiv_ESCoff_nicht_verfuegb" ;
VAL_ 2527679662 BRS_BFLS_Verbauzustand 0 "Init" 1 "nicht_verbaut" 2 "verbaut" ;
VAL_ 2527679662 BRS_Bremsfluessigkeit_Warnungen 0 "Init" 1 "iO_keine_Anzeige" 2 "Warnstufe_1" 3 "Warnstufe_2" ;
VAL_ 2527679662 ESC_Anf_Bremsenkuehlung 0 "keine_Anforderung" 1 "SKE_oeffnen" 2 "SKE_oeffnen_Luefter_ansteuern" ;
VAL_ 2463978660 ETL_IstModus 0 "Default" 1 "Standby_Startbereit" 2 "gesteuerter_Betrieb" 3 "gerregelter_Betrieb" 4 "Leerlauf_Freilauf" 5 "Komponenten_Fehler" 6 "Bremsen" ;
VAL_ 2463978660 ETL_IstLeistung 255 "Fehler" ;
VAL_ 2463978660 ETL_IstSpannung 511 "Fehler" ;
VAL_ 2463978660 ETL_Fehler_Blockiert 0 "kein_Fehler" 1 "Fehler" ;
VAL_ 2463978660 ETL_Fehler_Bauteil_Defekt 0 "kein_Fehler" 1 "Fehler" ;
VAL_ 2463978660 ETL_Fehler_Ueberspannung_HV 0 "kein_Fehler" 1 "Fehler" ;
VAL_ 2463978660 ETL_Fehler_Ueberspannung_NV 0 "kein_Fehler" 1 "Fehler" ;
VAL_ 2463978660 ETL_Fehler_Uebertemperatur 0 "kein_Fehler" 1 "Fehler" ;
VAL_ 2463978660 ETL_Fehler_Unterspannung_HV 0 "kein_Fehler" 1 "Fehler" ;
VAL_ 2463978660 ETL_Warnung_Uebertemperatur 0 "keine_Warnung" 1 "Warnung" ;
VAL_ 2463978660 ETL_IstDrehzahl 16383 "Fehler" ;
VAL_ 2463978660 ETL_Status_Spgfreiheit 0 "Init" 1 "HV_Komponente_spannungsfrei" 2 "HV_Komp_nicht_spannungsfrei" 3 "Fehler_nicht_spannungsfrei" ;
VAL_ 2463978660 ETL_IstStrom 255 "Fehler" ;
VAL_ 2463978695 ETL_Temperatur_Axiallager 254 "Init" 255 "Fehler" ;
VAL_ 2463978695 ETL_Temperatur_LE 254 "Init" 255 "Fehler" ;
VAL_ 2463978695 ETL_Temperatur_Stator 254 "Init" 255 "Fehler" ;
VAL_ 2463978695 ETL_Derating 255 "Fehler" ;
VAL_ 2463978695 ETL_Error_NW_Timeout 0 "TestNotCompleted_TOC" 1 "TestCompleted_TOC_PASS" 3 "TestCompleted_TOC_FAIL" ;
VAL_ 264 FA_Hoehenwerte_kalibriert 0 "kalibrierte_Hoehenwerte_in_mm" 1 "Rohwerte" ;
VAL_ 264 EFP_Anf_Bremsenkuehlung 0 "keine_Anforderung" 1 "SKE_oeffnen" 2 "SKE_oeffnen_Luefter_ansteuern" ;
VAL_ 264 FA_Hoehenwert_VL_00 254 "nicht initialisiert" 255 "Fehler" ;
VAL_ 264 FA_Hoehenwert_VR_00 254 "nicht initialisiert" 255 "Fehler" ;
VAL_ 264 FA_Hoehenwert_HL_00 254 "nicht initialisiert" 255 "Fehler" ;
VAL_ 264 FA_Hoehenwert_HR_00 254 "nicht initialisiert" 255 "Fehler" ;
VAL_ 264 FA_Fahrbahnunebenheit 254 "Init" 255 "Fehler" ;
VAL_ 222 FCU_IstLeistung 16382 "Init" 16383 "Fehler" ;
VAL_ 379 FCU_Warn_H2_Konzentrat_Motorraum 0 "Init" 1 "H2_Konzentration_Hoch" 2 "H2_Konzentration_Warnschnwelle" 3 "Drei_Prozent_H2" 4 "Vier_Prozent_H2" 5 "Leak_Check_Shut_Down_failed" 6 "Leak_Check_Start_Up_failed" 7 "reserviert" ;
VAL_ 379 FCU_nicht_verfuegbar 0 "verfuegbar" 1 "nicht_verfuegbar" ;
VAL_ 379 FCU_Startstopp_Anforderung 0 "keine_Anforderung" 1 "Stoppverbot" 2 "Startanforderung" 3 "Stoppanforderung" 4 "Startverbot" 5 "Stoppverbot_weich" 6 "Startwunsch_weich" 7 "Stoppwunsch_weich" 8 "Startverbot_weich" ;
VAL_ 379 FCU_HV_Anf 0 "Init" 1 "HV_Netz_nicht_angefordert" 2 "HV_Netz_angefordert" 3 "Fehler" ;
VAL_ 379 FCU_Klima_Eingr 0 "kein_Eingriff" 1 "Klimakompressor_ausschalten" 2 "Klimakomp_Leistungsreduzierung" 3 "Klimakomp_wegen_Heissleuchte_aus" ;
VAL_ 379 FCU_IstModus 0 "Off" 1 "Standby" 2 "Run" 3 "Sleep" 4 "Blowby" 5 "Fehler_Notabschaltung" 31 "Init" ;
VAL_ 379 FCU_Status_Spgfreiheit 0 "Init" 1 "HV_Komponente_spannungsfrei" 2 "HV_Komp_nicht_spannungsfrei" 3 "Fehler_nicht_spannungsfrei" ;
VAL_ 379 FCU_Fehler_Leistungsreduzierung 0 "kein_Fehler" 1 "Fehler" ;
VAL_ 379 FCU_Fehler_Abschaltanforderung 0 "kein_Fehler" 1 "Fehler" ;
VAL_ 379 FCU_Fehler_Notabschaltung 0 "kein_Fehler" 1 "Fehler" ;
VAL_ 379 FCU_Fehler_Entladung_defekt 0 "nicht_aktiv" 1 "Fehler" 2 "Reserve" 3 "Init" ;
VAL_ 379 FCU_Fehler_Isofehler_I 0 "nicht_aktiv" 1 "aktiv" 2 "Reserve" 3 "Init" ;
VAL_ 379 FCU_Fehler_Isofehler_II 0 "nicht_aktiv" 1 "aktiv" 2 "Reserve" 3 "Init" ;
VAL_ 379 FCU_OBD_Lampe_Anf 0 "kein_MIL_Request" 1 "MIL_Request" ;
VAL_ 379 FCU_Absperrventil_schliessen 0 "nicht_verfuegbar" 1 "Ansteuerung_Ventil_zulaessig" 2 "Ventil_oeffnen_oder_geoeffnet" 3 "Ventil_schliessen_o_geschlossen" ;
VAL_ 379 FCU_TK_Betankung_Anforderung 0 "inaktiv" 1 "aktiv" ;
VAL_ 379 FCU_MinAbs_Leistung 1023 "Init" ;
VAL_ 379 FCU_Ionenspuelung_aktiv 0 "keine_Spuelung" 1 "Spuelung_zwingend_notwendig" 2 "Spuelung_Anforderung" ;
VAL_ 379 FCU_TK_Freigabe_Tankklappe 0 "keineFreigabe" 1 "Freigabe" 2 "Init" 3 "Fehler" ;
VAL_ 2463978657 FCU_Kuehlerluefter_1 126 "Init" 127 "Fehler" ;
VAL_ 2463978657 FCU_MinDyn_Leistung 4095 "Init" ;
VAL_ 2463978657 FCU_MaxKuehlmitteldruck_erreicht 0 "MaxKuehlm_druck_nicht_erreicht" 1 "MaxKuehlm_druck_erreicht" ;
VAL_ 2463978657 FCU_Kuehlerluefter_2 126 "Init" 127 "Fehler" ;
VAL_ 2463978657 FCU_Druck_Kuehlmittel_Stack_Einl 510 "Init" 511 "Fehler" ;
VAL_ 2589283642 FCU_Heizungspumpenansteuerung 13 "nicht_verbaut" 14 "Init" 15 "Fehler" ;
VAL_ 2589283642 FCU_Pred_Startzeit 510 "Init" 511 "Fehler" ;
VAL_ 2589283642 FCU_Hoeheninfo 255 "Fehler" ;
VAL_ 2589283642 FCU_Temp_Kuehlmittel_Stack_Ausl 254 "Init" 255 "Fehler" ;
VAL_ 2589283642 FCU_Temp_Kuehlmittel_Stack_Einl 254 "Init" 255 "Fehler" ;
VAL_ 2589283642 FCU_Temp_Kuehlmittel_KMP_Einl 254 "Init" 255 "Fehler" ;
VAL_ 2589283646 FCU_Istposition_Thermostatventil 254 "Init" 255 "Fehler" ;
VAL_ 2463978770 FCU_TK_H2_Fuellstand 510 "Init" 511 "Fehler" ;
VAL_ 2463978770 FCU_TK_H2_Nachtanken_aktiv 0 "Init" 1 "inaktiv" 2 "aktiv" 3 "Fehler" ;
VAL_ 2463978770 FCU_TK_Meldungen 0 "Init" 1 "Leckage1_Fahrzeug_Halt" 2 "Leckage2_Fahrzeug_NOT" 3 "Tankbereitschaft_herstellen" 4 "Tankbereitschaft_hergestellt" 5 "Fehler_Tanksystem" 7 "Fehler" ;
VAL_ 2463978770 FCU_TK_Tankwarnungen 0 "Init" 1 "Stufe1" 2 "Stufe2" 3 "Stufe3" 7 "Fehler" ;
VAL_ 2463978817 FCU_Betriebspunkt_Soll 0 "Init" 1 "Betriebspunkt_01" 2 "Betriebspunkt_02" 3 "Betriebspunkt_03" 4 "Betriebspunkt_04" 5 "Betriebspunkt_05" 6 "Betriebspunkt_06" 7 "Betriebspunkt_07" 8 "Betriebspunkt_08" 9 "Betriebspunkt_09" 10 "Betriebspunkt_10" 11 "Betriebspunkt_11" 12 "Betriebspunkt_12" 13 "Betriebspunkt_13" 14 "Betriebspunkt_14" 15 "Betriebspunkt_15" ;
VAL_ 2463978817 FCU_Startleistungsbedarf 511 "Init" ;
VAL_ 2463978817 FCU_MaxAbs_Leistung 16383 "Init" ;
VAL_ 606 FCU_Energieaequivalent 4095 "Init" ;
VAL_ 606 FCU_Verbrauch_FC_Nebag_Ueberlauf 0 "kein_Ueberlauf" 1 "Ueberlauf_Verbrauchssignal" ;
VAL_ 606 FCU_Verbrauch_H2_Ueberlauf 0 "kein_Ueberlauf" 1 "Ueberlauf_Verbrauchssignal" ;
VAL_ 606 FCU_Verbrauch_FC_Ueberlauf 0 "kein_Ueberlauf" 1 "Ueberlauf_Verbrauchssignal" ;
VAL_ 607 FCU_TK_Fuellstand 510 "Init" 511 "Fehler" ;
VAL_ 607 FCU_TK_Wasserstoffmasse_Tank 1022 "Init" 1023 "Fehler" ;
VAL_ 607 FCU_Verb_FC_Nebag_Masaequi_Ueb 0 "kein_Ueberlauf" 1 "Ueberlauf_Verbrauchssignal" ;
VAL_ 177 GE_Fahrprogramm 0 "Init" 1 "nicht_belegt" 2 "Normal" 3 "Sport" 4 "Offroad" 5 "Efficiency" 6 "Sport_Plus" 7 "Sport_Response" 10 "Snow" 11 "Gravel" 12 "Mud_Ruts" 13 "Sand_Dune" ;
VAL_ 177 GE_TippZustand 0 "Init_Kein_Tipp" 1 "Tipp_permanent" 2 "Tipp_temporaer" ;
VAL_ 177 GE_Freilauf_Status 0 "Freilauf_inaktiv_aber_moeglich" 1 "Freilauf_aktiv" 2 "Freilauf_nicht_moegl_1Verhinderer" 3 "Freilauf_nicht_moegl_gr_1Verhinderer" 7 "Fehler" ;
VAL_ 177 GE_Grundeinstellung 0 "inaktiv" 1 "aktiv" ;
VAL_ 177 GE_Anschleppstart_Freigabe 0 "keine_Freigabe" 1 "Freigabe" ;
VAL_ 177 GE_Strombedarf_erh 0 "keine_Anforderung" 1 "erhoehte_Anforderung" ;
VAL_ 177 GE_Uefkt_Praed 16383 "Fehler" ;
VAL_ 177 GE_KomFehler_ESP 0 "kein_Fehler" 1 "Fehler" ;
VAL_ 177 GE_Rollrichtung_falsch 0 "richtige_Rollrichtung_o_Init" 1 "falsche_Rollrichtung" ;
VAL_ 177 GE_Getriebestatus_02 0 "inaktiv" 1 "Rennstartvorbereitung" 2 "Rennstart" 3 "Anfahrt" 4 "Anfahrt_Komfort" 5 "Anfahrt_Leerlaufregler" 6 "bereit_zur_Ueberanpressung" 7 "Low_Speed_Modus" 8 "eLaunch" ;
VAL_ 177 GE_Eingangsdrehz_Praed 16382 "Init" 16383 "Fehler" ;
VAL_ 310 HAL_Status 0 "Normalbetrieb" 1 "Lenkungsausfall" 2 "Derating_aktiv" 3 "Lenkung_manuell_deaktiviert" ;
VAL_ 310 HAL_VZ_Radwinkel 0 "positiv_Lenkeinschlag_links" 1 "negativ_Lenkeinschlag_rechts" ;
VAL_ 310 HAL_QBit_Radwinkel 0 "gueltiger_Wert" 1 "Ersatz_Init_oder_Fehlerwert" ;
VAL_ 310 HAL_Radwinkel 1020 "Unterspannung" 1021 "nicht_kalibriert" 1022 "Init" 1023 "Fehler" ;
VAL_ 310 HAL_Warnungen 0 "keine_Warnung" 1 "Ausfall_rote_Warnung" 2 "Systemstoerung_gelbe_Warnung" 3 "HAL_deaktiviert" ;
VAL_ 310 HAL_Winkelbegrenzung 0 "nicht_aktiv" 1 "Lenkwinkelbegrenzung_aktiv" ;
VAL_ 310 HAL_VZ_Fahrerwunschwinkel_Soll 0 "positiv" 1 "negativ" ;
VAL_ 310 HAL_Fahrerwunschwinkel_Soll 1022 "Init" 1023 "Fehler" ;
VAL_ 310 HAL_max_Gradient 126 "Init" 127 "Fehler" ;
VAL_ 310 HAL_EFP_FahrPr 0 "keine_Funktion" 1 "Programm_1" 2 "Programm_2" 3 "Programm_3" 4 "Programm_4" 5 "Programm_5" 6 "Programm_6" 7 "Programm_7" 8 "Programm_8" 9 "Programm_9" 10 "Programm_10" 11 "Programm_11" 12 "Programm_12" 13 "Programm_13" 14 "Programm_14" 15 "Programm_15" ;
VAL_ 310 HAL_Charisma_Status 0 "Init" 1 "verfuegbar" 2 "nicht_verfuegbar" 3 "asynchron_durch_Fahrerwunsch" ;
VAL_ 310 HAL_Charisma_FahrPr 0 "keine_Funktion" 1 "Programm_1" 2 "Programm_2" 3 "Programm_3" 4 "Programm_4" 5 "Programm_5" 6 "Programm_6" 7 "Programm_7" 8 "Programm_8" 9 "Programm_9" 10 "Programm_10" 11 "Programm_11" 12 "Programm_12" 13 "Programm_13" 14 "Programm_14" 15 "Programm_15" ;
VAL_ 1452 HVEM_IstStrom_HVVerbraucher 4094 "Init" 4095 "Fehler" ;
VAL_ 1452 HVEM_Energie_Klima_Vorgabe_HighR 6 "Init" 7 "Fehler" ;
VAL_ 1452 HVEM_IstLeistungNA 510 "Init" 511 "Fehler" ;
VAL_ 1452 HVEM_Leistung_Klima_Vorgabe 254 "Init" 255 "Fehler" ;
VAL_ 1452 HVEM_Nutzbare_Energie 2045 "Max" 2046 "Init" 2047 "Fehler" ;
VAL_ 1452 HVEM_Energie_Klima_Vorgabe 254 "Init" 255 "Fehler" ;
VAL_ 1452 HVEM_MO_MaxLeistungIgnoriert 0 "Max_Leistung_nicht_ignoriert" 1 "Max_Leistung_ignoriert" ;
VAL_ 1362 HVEM_NVNachladen_Energie 254 "Init" 255 "Fehler" ;
VAL_ 1362 HVEM_Max_VK_Betriebsdauer 62 "Init" 63 "Fehler" ;
VAL_ 1362 HVEM_Nachladen_Anf 0 "keine_Anforderung" 1 "Nachladen_angefordert" ;
VAL_ 1362 HVEM_SollStrom_HV 2046 "Init" 2047 "Fehler" ;
VAL_ 1362 HVEM_MaxSpannung_HV 1022 "Init" 1023 "Fehler" ;
VAL_ 1362 HVEM_Abschaltstatus 0 "100" 1 "75" 2 "50" 3 "25" 7 "Init" ;
VAL_ 1362 HVEM_DCDC_Freigabe 0 "keine_Freigabe" 1 "Freigabe" ;
VAL_ 1362 HVEM_FreigabeKlimatisierung 0 "keine_Freigabe" 1 "Freigabe" 2 "Init" 3 "Fehler" ;
VAL_ 1283 HVK_Istmodus_Anf 0 "nicht_angefordert" 1 "angefordert" ;
VAL_ 1283 HVK_TN1_Sollmodus 0 "HV_Off" 1 "HV_On" 2 "reserviert" 3 "Initialisierung" ;
VAL_ 1283 HVK_MO_EmSollzustand 0 "HvOff" 1 "HvStbyReq" 2 "HvStbyWait" 3 "HvBattOnReq" 4 "HvBattOnWait" 10 "HvOnIdle" 18 "HvOnDrvReq" 19 "HvOnDrvWait" 20 "HvOnDrvRdy" 28 "HvStepUpReq" 29 "HvStepUpWait" 30 "HvStepUp" 38 "HvStepDownReq" 39 "HvStepDownWait" 40 "HvStepDown" 46 "HvAcChPreReq" 47 "HvAcChPreWait" 48 "HvAcChReq" 49 "HvAcChWait" 50 "HvAcCh" 56 "HvDcChPreReq" 57 "HvDcChPreWait" 58 "HvDcChReq" 59 "HvDcChWait" 60 "HvDcCh" 67 "HvChOffReq" 68 "HvChOffWait" 69 "HvOnIdleReq" 70 "HvOnIdleWait" 96 "HvCpntOffReq" 97 "HvCpntOffWait" 98 "HvBattOffReq" 99 "HvBattOffWait" 109 "HvDcDcFailOffReq" 110 "HvDcDcFail" 119 "HvElmOffReq" 120 "HvElmOff" 126 "HvFailCpntOffReq" 127 "HvFailCpntOffWait" 128 "HvFailBattOffReq" 129 "HvFailBattOffWait" 130 "HvFailBattOff" 138 "HvFailUCtlReq" 139 "HvFailUCtlWait" 140 "HvFailUCtl" 150 "HvEmgcyOff" 255 "Init" ;
VAL_ 1283 HVK_BMS_Sollmodus 0 "HV_Off" 1 "HV_On" 3 "AC_Laden_erw" 4 "AC_Laden" 6 "DC_Laden" 7 "Init" ;
VAL_ 1283 HVK_DCDC_Sollmodus 0 "Standby" 1 "HV_On_Vorladen" 2 "Tiefsetzen" 3 "Hochsetzen" 4 "Pruefpuls_12V" 7 "Initialisierung" ;
VAL_ 1283 HVK_EKK_Sollmodus 0 "Keine_Freigabe" 1 "Freigabe" 2 "Freigabe_ausgesetzt" 7 "Init" ;
VAL_ 1283 HVK_HVPTC_Sollmodus 0 "Keine_Freigabe" 1 "Freigabe" 2 "Freigabe_ausgesetzt" 7 "Init" ;
VAL_ 1283 HVK_HVLM_Sollmodus 0 "keine_Freigabe" 1 "Freigabe_Lademanager" 7 "Init" ;
VAL_ 1283 HVK_HV_Netz_Warnungen 0 "Keine_Warnung" 1 "Warntext_HV_Netz_Anf" 2 "Fehlertext_HV_Netz_Anf" 3 "Warnung_Kein_Wiederstart_moeglich" ;
VAL_ 1283 HV_Bordnetz_aktiv 0 "inaktiv" 1 "aktiv" ;
VAL_ 1283 HV_Bordnetz_Fehler 0 "kein_Fehler" 1 "Fehler" ;
VAL_ 1283 HVK_Gesamtst_Spgfreiheit 0 "Funktion_Init__ohne_Funktion" 1 "HV_System_spannungsfrei" 2 "HV_System_nicht_spannungsfrei" 3 "Fehler" ;
VAL_ 1283 HVK_AktiveEntladung_Anf 0 "nicht_angefordert" 1 "angefordert" ;
VAL_ 1283 HVK_Iso_Messung_Start 0 "keine_Messung" 1 "Messung_HV_Netz_1" 2 "Messung_HV_Netz_2" 4 "deaktiviert" ;
VAL_ 1283 HVK_DCDC_EKK_Sollmodus 0 "aus" 1 "ein" 2 "reserviert" 3 "Init" ;
VAL_ 1381 HVLM_HV_Abstellzeit 254 "Init" 255 "Fehler" ;
VAL_ 1381 HVLM_Ladesystemhinweise 0 "kein_Hinweis" 1 "Ladesystem_defekt" 2 "Ladesaeule_inkompatibel" 3 "DC_Laden_nicht_moeglich" ;
VAL_ 1381 HVLM_Schluessel_Anfrage 0 "Keine_Anfrage_Init" 1 "Suchanfrage_LKL_1_aktiv" 2 "Suchanfrage_LKL_2_aktiv" 3 "Reserve" ;
VAL_ 1381 HVLM_Zustand_LED 0 "Farbe_1__aus" 1 "Farbe_2__weiss" 2 "Farbe_3__gelb" 3 "Farbe_4__gruen" 4 "Farbe_5__rot" 5 "Farbe_3_pulsierend" 6 "Farbe_4_pulsierend" 7 "Farbe_5_pulsierend" 8 "Farbe_4_5_pulsierend" 9 "Farbe_4__gruen_blinkend" 14 "Init" 15 "Fehler" ;
VAL_ 1381 HVLM_MaxStrom_Netz 126 "Init" 127 "Fehler" ;
VAL_ 1381 HVLM_LG_Sollmodus 0 "Standby" 1 "Netzladung" ;
VAL_ 1381 HVLM_FreigabeTankdeckel 0 "keine_Freigabe" 1 "Freigabe" 2 "Init" 3 "Fehler" ;
VAL_ 1381 HVLM_Stecker_Verriegeln 0 "Stecker_entriegeln" 1 "Stecker_verriegeln" 2 "Init" 3 "keine_Anforderung" ;
VAL_ 1381 HVLM_Start_Spannungsmessung_DCLS 0 "inaktiv" 1 "DCLS_mit_Diode_Start_Messung" 2 "DCLS_ohne_Diode_Start_Messung" 3 "reserve" ;
VAL_ 1381 PnC_Trigger_OBC_cGW 0 "PnC_Init" 1 "PnC_NoNeeds" 2 "PnC_ReportUnknownRootCert" 3 "PnC_CreateVehicleCert" 4 "PnC_DP_RootCertContainer" 5 "PnC_DP_CapabilityIsoTpInfo" 6 "PnC_DP_Contract" 7 "PnC_DP_VehicleCert" 15 "PnC_Error" ;
VAL_ 1381 HVLM_FreigabeKlimatisierung 0 "keine_Freigabe" 1 "Freigabe" 2 "Init" 3 "Fehler" ;
VAL_ 1381 HVLM_Ladetexte 0 "Keine_Anzeige" 1 "AC_Laden_nicht_moeglich" 2 "DC_Laden_nicht_moeglich" 3 "AC_und_DC_Laden_nicht_moeglich" ;
VAL_ 1381 HVLM_IsoMessung_Anf 0 "Laden_mit_Isomessung" 1 "Laden_ohne_Isomessung" ;
VAL_ 1381 HVLM_IstSpannung_HV 1022 "Init" 1023 "Fehler" ;
VAL_ 1340 HVLM_STH_Betriebsmodus 0 "Keine_Klimatisierung" 1 "Heizen" 2 "Abtauen" 6 "Init" 7 "Fehler" ;
VAL_ 1340 HVLM_Standklima_Timer_Status 0 "Standklimatimer_nicht_aktiv" 1 "Standklimatimer_aktiv" ;
VAL_ 1340 HVLM_HVEM_MaxLeistung 510 "Init" 511 "Fehler" ;
VAL_ 1340 HVLM_Status_Netz 0 "Fzg_nicht_am_Netz" 1 "Fzg_ist_am_Stromnetz" ;
VAL_ 1340 HVLM_Anf_Ladescreen 0 "Ladescreen_off" 1 "Ladescreen_on" ;
VAL_ 1340 HVLM_Ladeart 0 "keine_Auswahl" 1 "AC_Laden" 2 "DC_Laden" 3 "Konditionierung" ;
VAL_ 1340 HVLM_VK_STH_Einsatz 0 "Verbrennerstandheizung verbieten" 1 "Automatik (Verbrennerstandheizung erlauben)" 2 "Verbrennerstandheizung erzwingen" 3 "reserviert" 4 "reserviert" 5 "reserviert" 6 "Init" 7 "Fehler" ;
VAL_ 1340 HVLM_VK_Modus 0 "keine Vorkonditionierung" 1 "Sofort-Konditionierung" 2 "zeitversetzte Konditionierung" 3 "Fehler" ;
VAL_ 1340 HVLM_IstModus_02 0 "inaktiv" 1 "aktiv" 2 "Init" 3 "Fehler" ;
VAL_ 1340 HVLM_HV_Anf 0 "keine_Anforderung" 1 "Laden_angefordert" 2 "Batteriekonditionierung_angefordert" 3 "Standklimatisierung_angefordert" ;
VAL_ 1340 HVLM_Fehlerstatus 0 "Komponente_IO" 1 "Eingeschr_KompFkt_DC_Lad_NIO" 2 "Eingeschr_KompFkt_AC_Lad_NIO" 3 "Eingeschr_KompFkt_Interlock" 4 "Eingeschr_KompFkt_reserve" 5 "Eingeschr_KompFkt_reserve" 6 "Keine_Komponentenfunktion" 7 "Init" ;
VAL_ 1340 HVLM_Anforderung_HMS 0 "keine_Anforderung" 1 "halten" 2 "parken" 3 "halten_Standby" 4 "anfahren" 5 "Loesen_ueber_Rampe" ;
VAL_ 1340 HVLM_Parken_beibehalten_HMS 0 "Parken_nicht_beibehalten" 1 "Parken_beibehalten" 2 "Init" 3 "Fehler" ;
VAL_ 1340 HVLM_AWC_Sollmodus 0 "init" 1 "Inaktiv" 2 "Standby" 3 "AWCLaden" 4 "Notabschaltung" 5 "Reserve" 6 "Reserve" 7 "Fehler" ;
VAL_ 1340 HVLM_Stecker_Status 0 "Init" 1 "kein_Stecker_gesteckt" 2 "Stecker_erkannt_nicht_verriegelt" 3 "Stecker_erkannt_und_verriegelt" ;
VAL_ 1340 HVLM_LadeAnforderung 0 "keine_Anforderung" 1 "AC_Laden" 2 "DC_Laden" 3 "Nachladen_12V" 4 "AC_Laden_AWC" 5 "Reserve" 6 "Init" 7 "Fehler" ;
VAL_ 1340 HVLM_MaxBatLadestromHV 254 "Init" 255 "Fehler" ;
VAL_ 1160 HVLM_MaxLadeLeistung 1022 "Init" 1023 "Fehler" ;
VAL_ 1160 HVLM_MaxSpannung_DCLS 1022 "Init" 1023 "Fehler" ;
VAL_ 1160 HVLM_IstStrom_DCLS 510 "Init" 511 "Fehler" ;
VAL_ 1160 HVLM_MaxStrom_DCLS 510 "Init" 511 "Fehler" ;
VAL_ 1160 HVLM_MinSpannung_DCLS 510 "Init" 511 "Fehler" ;
VAL_ 1160 HVLM_MinStrom_DCLS 30 "Init" 31 "Fehler" ;
VAL_ 2589283485 HVLM_Funktion_Dauer_BattKond 0 "inaktiv" 1 "aktiv" ;
VAL_ 2589283485 HVLM_BattKond_Anf 0 "keine_Anforderung" 1 "Anforderung_Heizstufe_1" 2 "Anforderung_Heizstufe_2" 6 "Init" 7 "Fehler" ;
VAL_ 2589283485 HVLM_Dauer_Klima_02 61 "default" 62 "Init" 63 "Fehler" ;
VAL_ 2589283605 HVLM_AWC_Sollstrom 510 "Init" 511 "Fehler" ;
